VERSION ""

NS_ :

BS_:

BU_: IFV_VFP External_Tool IFV_Host MRR

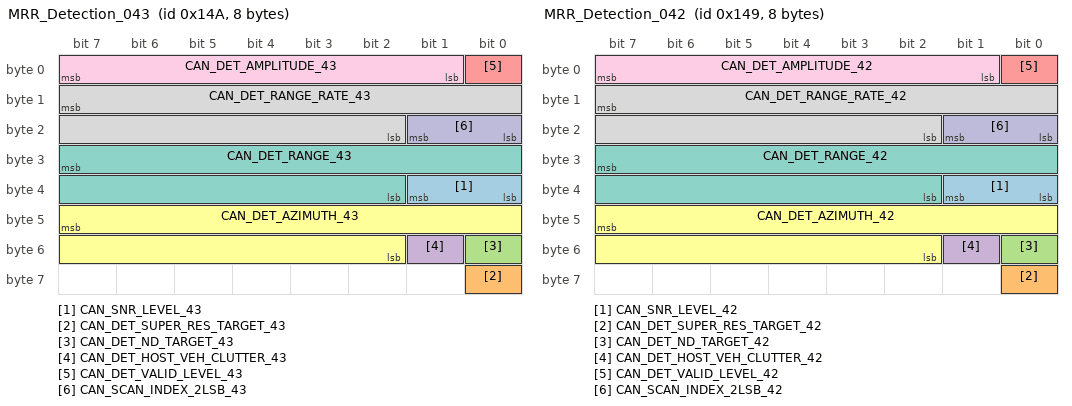
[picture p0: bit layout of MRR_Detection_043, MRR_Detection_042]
BO_ 330 MRR_Detection_043: 8 MRR
 SG_ CAN_SNR_LEVEL_43 : 33|2@0+ (1,0) [0|3] ""  IFV_VFP
 SG_ CAN_DET_SUPER_RES_TARGET_43 : 56|1@0+ (1,0) [0|1] ""  IFV_VFP
 SG_ CAN_DET_ND_TARGET_43 : 48|1@0+ (1,0) [0|1] ""  IFV_VFP
 SG_ CAN_DET_HOST_VEH_CLUTTER_43 : 49|1@0+ (1,0) [0|1] ""  IFV_VFP
 SG_ CAN_DET_VALID_LEVEL_43 : 0|1@0+ (1,0) [0|1] ""  IFV_VFP
 SG_ CAN_DET_AZIMUTH_43 : 47|14@0+ (0.0003834,-3.1416) [-3.1416|3.1396422] "rad"  IFV_VFP
 SG_ CAN_DET_RANGE_43 : 31|14@0+ (0.015625,0) [0|255.984375] "m"  IFV_VFP
 SG_ CAN_DET_RANGE_RATE_43 : 15|14@0+ (0.015625,-128) [-128|127.984375] "m/s"  IFV_VFP
 SG_ CAN_DET_AMPLITUDE_43 : 7|7@0+ (1,-64) [-64|63] "dBsm"  IFV_VFP
 SG_ CAN_SCAN_INDEX_2LSB_43 : 17|2@0+ (1,0) [0|3] ""  IFV_VFP

BO_ 329 MRR_Detection_042: 8 MRR
 SG_ CAN_SNR_LEVEL_42 : 33|2@0+ (1,0) [0|3] ""  IFV_VFP
 SG_ CAN_DET_SUPER_RES_TARGET_42 : 56|1@0+ (1,0) [0|1] ""  IFV_VFP
 SG_ CAN_DET_ND_TARGET_42 : 48|1@0+ (1,0) [0|1] ""  IFV_VFP
 SG_ CAN_DET_HOST_VEH_CLUTTER_42 : 49|1@0+ (1,0) [0|1] ""  IFV_VFP
 SG_ CAN_DET_VALID_LEVEL_42 : 0|1@0+ (1,0) [0|1] ""  IFV_VFP
 SG_ CAN_DET_AZIMUTH_42 : 47|14@0+ (0.0003834,-3.1416) [-3.1416|3.1396422] "rad"  IFV_VFP
 SG_ CAN_DET_RANGE_42 : 31|14@0+ (0.015625,0) [0|255.984375] "m"  IFV_VFP
 SG_ CAN_DET_RANGE_RATE_42 : 15|14@0+ (0.015625,-128) [-128|127.984375] "m/s"  IFV_VFP
 SG_ CAN_DET_AMPLITUDE_42 : 7|7@0+ (1,-64) [-64|63] "dBsm"  IFV_VFP
 SG_ CAN_SCAN_INDEX_2LSB_42 : 17|2@0+ (1,0) [0|3] ""  IFV_VFP

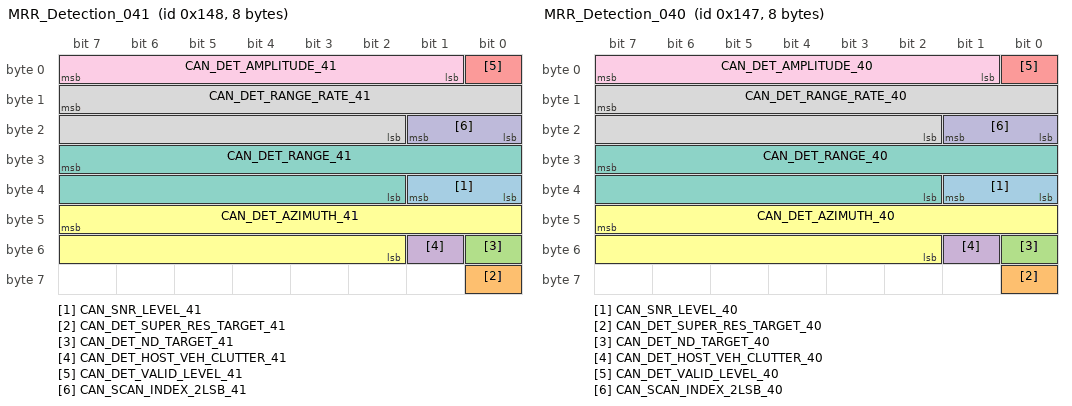
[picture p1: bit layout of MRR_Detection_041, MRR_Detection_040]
BO_ 328 MRR_Detection_041: 8 MRR
 SG_ CAN_SNR_LEVEL_41 : 33|2@0+ (1,0) [0|3] ""  IFV_VFP
 SG_ CAN_DET_SUPER_RES_TARGET_41 : 56|1@0+ (1,0) [0|1] ""  IFV_VFP
 SG_ CAN_DET_ND_TARGET_41 : 48|1@0+ (1,0) [0|1] ""  IFV_VFP
 SG_ CAN_DET_HOST_VEH_CLUTTER_41 : 49|1@0+ (1,0) [0|1] ""  IFV_VFP
 SG_ CAN_DET_VALID_LEVEL_41 : 0|1@0+ (1,0) [0|1] ""  IFV_VFP
 SG_ CAN_DET_AZIMUTH_41 : 47|14@0+ (0.0003834,-3.1416) [-3.1416|3.1396422] "rad"  IFV_VFP
 SG_ CAN_DET_RANGE_41 : 31|14@0+ (0.015625,0) [0|255.984375] "m"  IFV_VFP
 SG_ CAN_DET_RANGE_RATE_41 : 15|14@0+ (0.015625,-128) [-128|127.984375] "m/s"  IFV_VFP
 SG_ CAN_DET_AMPLITUDE_41 : 7|7@0+ (1,-64) [-64|63] "dBsm"  IFV_VFP
 SG_ CAN_SCAN_INDEX_2LSB_41 : 17|2@0+ (1,0) [0|3] ""  IFV_VFP

BO_ 327 MRR_Detection_040: 8 MRR
 SG_ CAN_SNR_LEVEL_40 : 33|2@0+ (1,0) [0|3] ""  IFV_VFP
 SG_ CAN_DET_SUPER_RES_TARGET_40 : 56|1@0+ (1,0) [0|1] ""  IFV_VFP
 SG_ CAN_DET_ND_TARGET_40 : 48|1@0+ (1,0) [0|1] ""  IFV_VFP
 SG_ CAN_DET_HOST_VEH_CLUTTER_40 : 49|1@0+ (1,0) [0|1] ""  IFV_VFP
 SG_ CAN_DET_VALID_LEVEL_40 : 0|1@0+ (1,0) [0|1] ""  IFV_VFP
 SG_ CAN_DET_AZIMUTH_40 : 47|14@0+ (0.0003834,-3.1416) [-3.1416|3.1396422] "rad"  IFV_VFP
 SG_ CAN_DET_RANGE_40 : 31|14@0+ (0.015625,0) [0|255.984375] "m"  IFV_VFP
 SG_ CAN_DET_RANGE_RATE_40 : 15|14@0+ (0.015625,-128) [-128|127.984375] "m/s"  IFV_VFP
 SG_ CAN_DET_AMPLITUDE_40 : 7|7@0+ (1,-64) [-64|63] "dBsm"  IFV_VFP
 SG_ CAN_SCAN_INDEX_2LSB_40 : 17|2@0+ (1,0) [0|3] ""  IFV_VFP

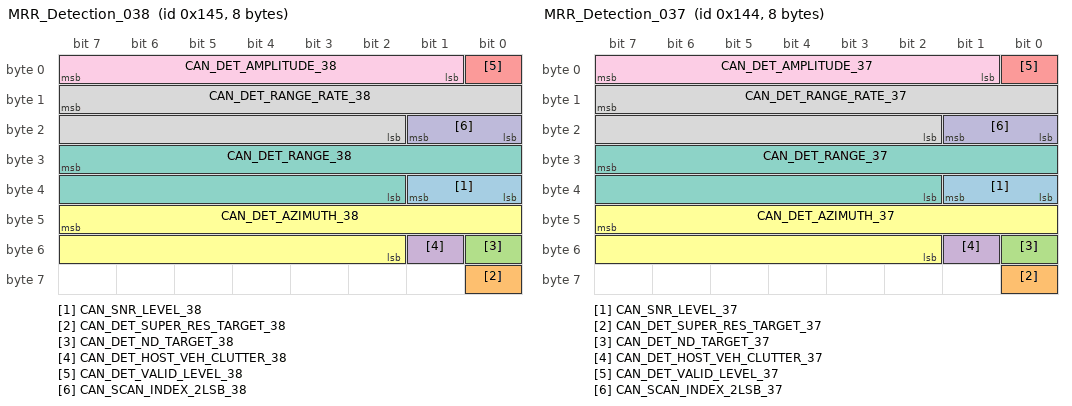
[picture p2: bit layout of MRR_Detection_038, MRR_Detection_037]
BO_ 325 MRR_Detection_038: 8 MRR
 SG_ CAN_SNR_LEVEL_38 : 33|2@0+ (1,0) [0|3] ""  IFV_VFP
 SG_ CAN_DET_SUPER_RES_TARGET_38 : 56|1@0+ (1,0) [0|1] ""  IFV_VFP
 SG_ CAN_DET_ND_TARGET_38 : 48|1@0+ (1,0) [0|1] ""  IFV_VFP
 SG_ CAN_DET_HOST_VEH_CLUTTER_38 : 49|1@0+ (1,0) [0|1] ""  IFV_VFP
 SG_ CAN_DET_VALID_LEVEL_38 : 0|1@0+ (1,0) [0|1] ""  IFV_VFP
 SG_ CAN_DET_AZIMUTH_38 : 47|14@0+ (0.0003834,-3.1416) [-3.1416|3.1396422] "rad"  IFV_VFP
 SG_ CAN_DET_RANGE_38 : 31|14@0+ (0.015625,0) [0|255.984375] "m"  IFV_VFP
 SG_ CAN_DET_RANGE_RATE_38 : 15|14@0+ (0.015625,-128) [-128|127.984375] "m/s"  IFV_VFP
 SG_ CAN_DET_AMPLITUDE_38 : 7|7@0+ (1,-64) [-64|63] "dBsm"  IFV_VFP
 SG_ CAN_SCAN_INDEX_2LSB_38 : 17|2@0+ (1,0) [0|3] ""  IFV_VFP

BO_ 324 MRR_Detection_037: 8 MRR
 SG_ CAN_SNR_LEVEL_37 : 33|2@0+ (1,0) [0|3] ""  IFV_VFP
 SG_ CAN_DET_SUPER_RES_TARGET_37 : 56|1@0+ (1,0) [0|1] ""  IFV_VFP
 SG_ CAN_DET_ND_TARGET_37 : 48|1@0+ (1,0) [0|1] ""  IFV_VFP
 SG_ CAN_DET_HOST_VEH_CLUTTER_37 : 49|1@0+ (1,0) [0|1] ""  IFV_VFP
 SG_ CAN_DET_VALID_LEVEL_37 : 0|1@0+ (1,0) [0|1] ""  IFV_VFP
 SG_ CAN_DET_AZIMUTH_37 : 47|14@0+ (0.0003834,-3.1416) [-3.1416|3.1396422] "rad"  IFV_VFP
 SG_ CAN_DET_RANGE_37 : 31|14@0+ (0.015625,0) [0|255.984375] "m"  IFV_VFP
 SG_ CAN_DET_RANGE_RATE_37 : 15|14@0+ (0.015625,-128) [-128|127.984375] "m/s"  IFV_VFP
 SG_ CAN_DET_AMPLITUDE_37 : 7|7@0+ (1,-64) [-64|63] "dBsm"  IFV_VFP
 SG_ CAN_SCAN_INDEX_2LSB_37 : 17|2@0+ (1,0) [0|3] ""  IFV_VFP

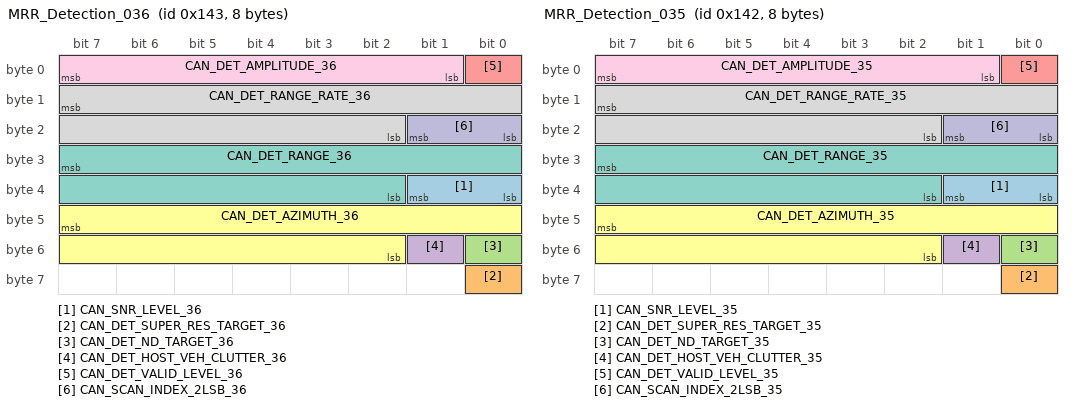
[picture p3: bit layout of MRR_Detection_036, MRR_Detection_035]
BO_ 323 MRR_Detection_036: 8 MRR
 SG_ CAN_SNR_LEVEL_36 : 33|2@0+ (1,0) [0|3] ""  IFV_VFP
 SG_ CAN_DET_SUPER_RES_TARGET_36 : 56|1@0+ (1,0) [0|1] ""  IFV_VFP
 SG_ CAN_DET_ND_TARGET_36 : 48|1@0+ (1,0) [0|1] ""  IFV_VFP
 SG_ CAN_DET_HOST_VEH_CLUTTER_36 : 49|1@0+ (1,0) [0|1] ""  IFV_VFP
 SG_ CAN_DET_VALID_LEVEL_36 : 0|1@0+ (1,0) [0|1] ""  IFV_VFP
 SG_ CAN_DET_AZIMUTH_36 : 47|14@0+ (0.0003834,-3.1416) [-3.1416|3.1396422] "rad"  IFV_VFP
 SG_ CAN_DET_RANGE_36 : 31|14@0+ (0.015625,0) [0|255.984375] "m"  IFV_VFP
 SG_ CAN_DET_RANGE_RATE_36 : 15|14@0+ (0.015625,-128) [-128|127.984375] "m/s"  IFV_VFP
 SG_ CAN_DET_AMPLITUDE_36 : 7|7@0+ (1,-64) [-64|63] "dBsm"  IFV_VFP
 SG_ CAN_SCAN_INDEX_2LSB_36 : 17|2@0+ (1,0) [0|3] ""  IFV_VFP

BO_ 322 MRR_Detection_035: 8 MRR
 SG_ CAN_SNR_LEVEL_35 : 33|2@0+ (1,0) [0|3] ""  IFV_VFP
 SG_ CAN_DET_SUPER_RES_TARGET_35 : 56|1@0+ (1,0) [0|1] ""  IFV_VFP
 SG_ CAN_DET_ND_TARGET_35 : 48|1@0+ (1,0) [0|1] ""  IFV_VFP
 SG_ CAN_DET_HOST_VEH_CLUTTER_35 : 49|1@0+ (1,0) [0|1] ""  IFV_VFP
 SG_ CAN_DET_VALID_LEVEL_35 : 0|1@0+ (1,0) [0|1] ""  IFV_VFP
 SG_ CAN_DET_AZIMUTH_35 : 47|14@0+ (0.0003834,-3.1416) [-3.1416|3.1396422] "rad"  IFV_VFP
 SG_ CAN_DET_RANGE_35 : 31|14@0+ (0.015625,0) [0|255.984375] "m"  IFV_VFP
 SG_ CAN_DET_RANGE_RATE_35 : 15|14@0+ (0.015625,-128) [-128|127.984375] "m/s"  IFV_VFP
 SG_ CAN_DET_AMPLITUDE_35 : 7|7@0+ (1,-64) [-64|63] "dBsm"  IFV_VFP
 SG_ CAN_SCAN_INDEX_2LSB_35 : 17|2@0+ (1,0) [0|3] ""  IFV_VFP

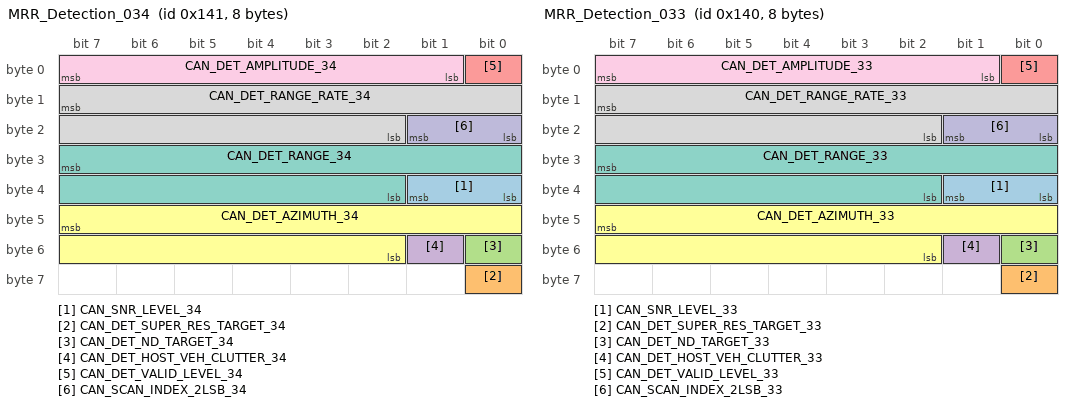
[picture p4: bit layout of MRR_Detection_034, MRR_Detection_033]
BO_ 321 MRR_Detection_034: 8 MRR
 SG_ CAN_SNR_LEVEL_34 : 33|2@0+ (1,0) [0|3] ""  IFV_VFP
 SG_ CAN_DET_SUPER_RES_TARGET_34 : 56|1@0+ (1,0) [0|1] ""  IFV_VFP
 SG_ CAN_DET_ND_TARGET_34 : 48|1@0+ (1,0) [0|1] ""  IFV_VFP
 SG_ CAN_DET_HOST_VEH_CLUTTER_34 : 49|1@0+ (1,0) [0|1] ""  IFV_VFP
 SG_ CAN_DET_VALID_LEVEL_34 : 0|1@0+ (1,0) [0|1] ""  IFV_VFP
 SG_ CAN_DET_AZIMUTH_34 : 47|14@0+ (0.0003834,-3.1416) [-3.1416|3.1396422] "rad"  IFV_VFP
 SG_ CAN_DET_RANGE_34 : 31|14@0+ (0.015625,0) [0|255.984375] "m"  IFV_VFP
 SG_ CAN_DET_RANGE_RATE_34 : 15|14@0+ (0.015625,-128) [-128|127.984375] "m/s"  IFV_VFP
 SG_ CAN_DET_AMPLITUDE_34 : 7|7@0+ (1,-64) [-64|63] "dBsm"  IFV_VFP
 SG_ CAN_SCAN_INDEX_2LSB_34 : 17|2@0+ (1,0) [0|3] ""  IFV_VFP

BO_ 320 MRR_Detection_033: 8 MRR
 SG_ CAN_SNR_LEVEL_33 : 33|2@0+ (1,0) [0|3] ""  IFV_VFP
 SG_ CAN_DET_SUPER_RES_TARGET_33 : 56|1@0+ (1,0) [0|1] ""  IFV_VFP
 SG_ CAN_DET_ND_TARGET_33 : 48|1@0+ (1,0) [0|1] ""  IFV_VFP
 SG_ CAN_DET_HOST_VEH_CLUTTER_33 : 49|1@0+ (1,0) [0|1] ""  IFV_VFP
 SG_ CAN_DET_VALID_LEVEL_33 : 0|1@0+ (1,0) [0|1] ""  IFV_VFP
 SG_ CAN_DET_AZIMUTH_33 : 47|14@0+ (0.0003834,-3.1416) [-3.1416|3.1396422] "rad"  IFV_VFP
 SG_ CAN_DET_RANGE_33 : 31|14@0+ (0.015625,0) [0|255.984375] "m"  IFV_VFP
 SG_ CAN_DET_RANGE_RATE_33 : 15|14@0+ (0.015625,-128) [-128|127.984375] "m/s"  IFV_VFP
 SG_ CAN_DET_AMPLITUDE_33 : 7|7@0+ (1,-64) [-64|63] "dBsm"  IFV_VFP
 SG_ CAN_SCAN_INDEX_2LSB_33 : 17|2@0+ (1,0) [0|3] ""  IFV_VFP

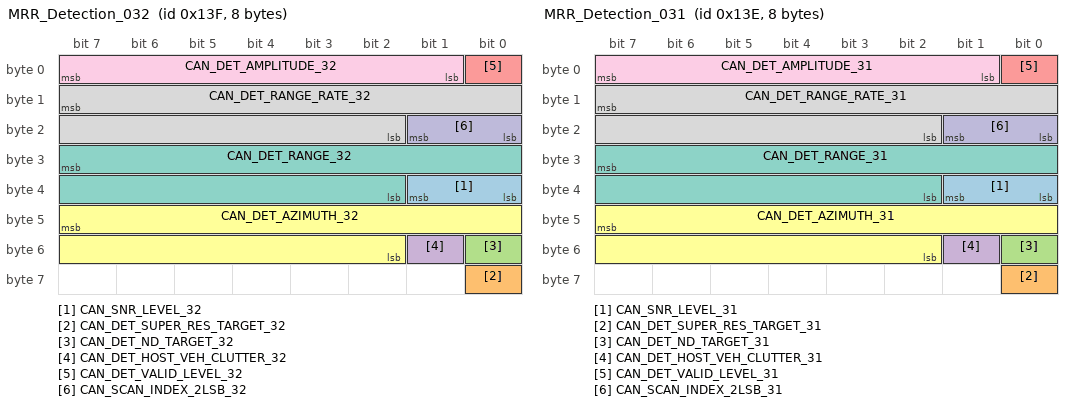
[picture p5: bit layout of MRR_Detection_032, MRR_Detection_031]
BO_ 319 MRR_Detection_032: 8 MRR
 SG_ CAN_SNR_LEVEL_32 : 33|2@0+ (1,0) [0|3] ""  IFV_VFP
 SG_ CAN_DET_SUPER_RES_TARGET_32 : 56|1@0+ (1,0) [0|1] ""  IFV_VFP
 SG_ CAN_DET_ND_TARGET_32 : 48|1@0+ (1,0) [0|1] ""  IFV_VFP
 SG_ CAN_DET_HOST_VEH_CLUTTER_32 : 49|1@0+ (1,0) [0|1] ""  IFV_VFP
 SG_ CAN_DET_VALID_LEVEL_32 : 0|1@0+ (1,0) [0|1] ""  IFV_VFP
 SG_ CAN_DET_AZIMUTH_32 : 47|14@0+ (0.0003834,-3.1416) [-3.1416|3.1396422] "rad"  IFV_VFP
 SG_ CAN_DET_RANGE_32 : 31|14@0+ (0.015625,0) [0|255.984375] "m"  IFV_VFP
 SG_ CAN_DET_RANGE_RATE_32 : 15|14@0+ (0.015625,-128) [-128|127.984375] "m/s"  IFV_VFP
 SG_ CAN_DET_AMPLITUDE_32 : 7|7@0+ (1,-64) [-64|63] "dBsm"  IFV_VFP
 SG_ CAN_SCAN_INDEX_2LSB_32 : 17|2@0+ (1,0) [0|3] ""  IFV_VFP

BO_ 318 MRR_Detection_031: 8 MRR
 SG_ CAN_SNR_LEVEL_31 : 33|2@0+ (1,0) [0|3] ""  IFV_VFP
 SG_ CAN_DET_SUPER_RES_TARGET_31 : 56|1@0+ (1,0) [0|1] ""  IFV_VFP
 SG_ CAN_DET_ND_TARGET_31 : 48|1@0+ (1,0) [0|1] ""  IFV_VFP
 SG_ CAN_DET_HOST_VEH_CLUTTER_31 : 49|1@0+ (1,0) [0|1] ""  IFV_VFP
 SG_ CAN_DET_VALID_LEVEL_31 : 0|1@0+ (1,0) [0|1] ""  IFV_VFP
 SG_ CAN_DET_AZIMUTH_31 : 47|14@0+ (0.0003834,-3.1416) [-3.1416|3.1396422] "rad"  IFV_VFP
 SG_ CAN_DET_RANGE_31 : 31|14@0+ (0.015625,0) [0|255.984375] "m"  IFV_VFP
 SG_ CAN_DET_RANGE_RATE_31 : 15|14@0+ (0.015625,-128) [-128|127.984375] "m/s"  IFV_VFP
 SG_ CAN_DET_AMPLITUDE_31 : 7|7@0+ (1,-64) [-64|63] "dBsm"  IFV_VFP
 SG_ CAN_SCAN_INDEX_2LSB_31 : 17|2@0+ (1,0) [0|3] ""  IFV_VFP

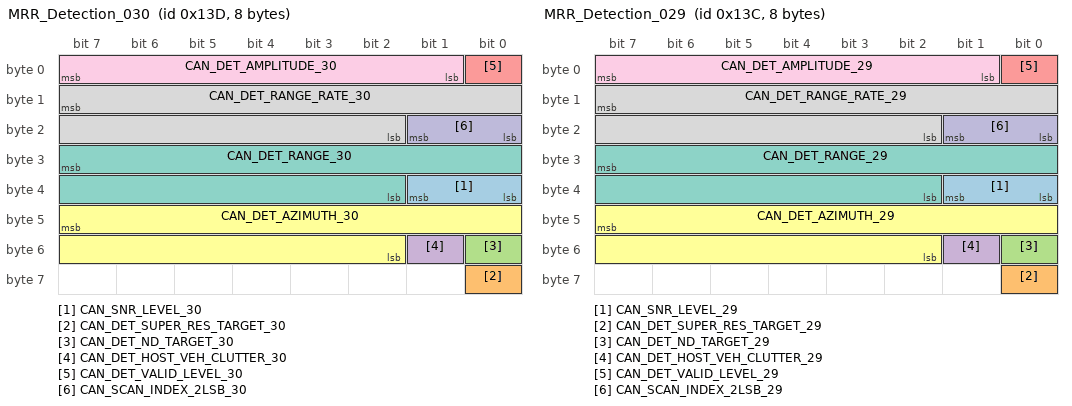
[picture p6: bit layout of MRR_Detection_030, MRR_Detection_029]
BO_ 317 MRR_Detection_030: 8 MRR
 SG_ CAN_SNR_LEVEL_30 : 33|2@0+ (1,0) [0|3] ""  IFV_VFP
 SG_ CAN_DET_SUPER_RES_TARGET_30 : 56|1@0+ (1,0) [0|1] ""  IFV_VFP
 SG_ CAN_DET_ND_TARGET_30 : 48|1@0+ (1,0) [0|1] ""  IFV_VFP
 SG_ CAN_DET_HOST_VEH_CLUTTER_30 : 49|1@0+ (1,0) [0|1] ""  IFV_VFP
 SG_ CAN_DET_VALID_LEVEL_30 : 0|1@0+ (1,0) [0|1] ""  IFV_VFP
 SG_ CAN_DET_AZIMUTH_30 : 47|14@0+ (0.0003834,-3.1416) [-3.1416|3.1396422] "rad"  IFV_VFP
 SG_ CAN_DET_RANGE_30 : 31|14@0+ (0.015625,0) [0|255.984375] "m"  IFV_VFP
 SG_ CAN_DET_RANGE_RATE_30 : 15|14@0+ (0.015625,-128) [-128|127.984375] "m/s"  IFV_VFP
 SG_ CAN_DET_AMPLITUDE_30 : 7|7@0+ (1,-64) [-64|63] "dBsm"  IFV_VFP
 SG_ CAN_SCAN_INDEX_2LSB_30 : 17|2@0+ (1,0) [0|3] ""  IFV_VFP

BO_ 316 MRR_Detection_029: 8 MRR
 SG_ CAN_SNR_LEVEL_29 : 33|2@0+ (1,0) [0|3] ""  IFV_VFP
 SG_ CAN_DET_SUPER_RES_TARGET_29 : 56|1@0+ (1,0) [0|1] ""  IFV_VFP
 SG_ CAN_DET_ND_TARGET_29 : 48|1@0+ (1,0) [0|1] ""  IFV_VFP
 SG_ CAN_DET_HOST_VEH_CLUTTER_29 : 49|1@0+ (1,0) [0|1] ""  IFV_VFP
 SG_ CAN_DET_VALID_LEVEL_29 : 0|1@0+ (1,0) [0|1] ""  IFV_VFP
 SG_ CAN_DET_AZIMUTH_29 : 47|14@0+ (0.0003834,-3.1416) [-3.1416|3.1396422] "rad"  IFV_VFP
 SG_ CAN_DET_RANGE_29 : 31|14@0+ (0.015625,0) [0|255.984375] "m"  IFV_VFP
 SG_ CAN_DET_RANGE_RATE_29 : 15|14@0+ (0.015625,-128) [-128|127.984375] "m/s"  IFV_VFP
 SG_ CAN_DET_AMPLITUDE_29 : 7|7@0+ (1,-64) [-64|63] "dBsm"  IFV_VFP
 SG_ CAN_SCAN_INDEX_2LSB_29 : 17|2@0+ (1,0) [0|3] ""  IFV_VFP

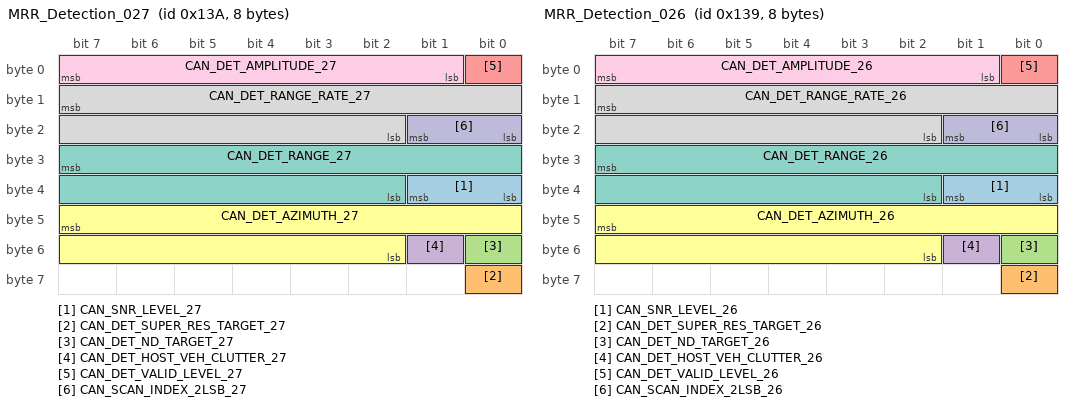
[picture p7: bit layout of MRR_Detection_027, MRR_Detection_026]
BO_ 314 MRR_Detection_027: 8 MRR
 SG_ CAN_SNR_LEVEL_27 : 33|2@0+ (1,0) [0|3] ""  IFV_VFP
 SG_ CAN_DET_SUPER_RES_TARGET_27 : 56|1@0+ (1,0) [0|1] ""  IFV_VFP
 SG_ CAN_DET_ND_TARGET_27 : 48|1@0+ (1,0) [0|1] ""  IFV_VFP
 SG_ CAN_DET_HOST_VEH_CLUTTER_27 : 49|1@0+ (1,0) [0|1] ""  IFV_VFP
 SG_ CAN_DET_VALID_LEVEL_27 : 0|1@0+ (1,0) [0|1] ""  IFV_VFP
 SG_ CAN_DET_AZIMUTH_27 : 47|14@0+ (0.0003834,-3.1416) [-3.1416|3.1396422] "rad"  IFV_VFP
 SG_ CAN_DET_RANGE_27 : 31|14@0+ (0.015625,0) [0|255.984375] "m"  IFV_VFP
 SG_ CAN_DET_RANGE_RATE_27 : 15|14@0+ (0.015625,-128) [-128|127.984375] "m/s"  IFV_VFP
 SG_ CAN_DET_AMPLITUDE_27 : 7|7@0+ (1,-64) [-64|63] "dBsm"  IFV_VFP
 SG_ CAN_SCAN_INDEX_2LSB_27 : 17|2@0+ (1,0) [0|3] ""  IFV_VFP

BO_ 313 MRR_Detection_026: 8 MRR
 SG_ CAN_SNR_LEVEL_26 : 33|2@0+ (1,0) [0|3] ""  IFV_VFP
 SG_ CAN_DET_SUPER_RES_TARGET_26 : 56|1@0+ (1,0) [0|1] ""  IFV_VFP
 SG_ CAN_DET_ND_TARGET_26 : 48|1@0+ (1,0) [0|1] ""  IFV_VFP
 SG_ CAN_DET_HOST_VEH_CLUTTER_26 : 49|1@0+ (1,0) [0|1] ""  IFV_VFP
 SG_ CAN_DET_VALID_LEVEL_26 : 0|1@0+ (1,0) [0|1] ""  IFV_VFP
 SG_ CAN_DET_AZIMUTH_26 : 47|14@0+ (0.0003834,-3.1416) [-3.1416|3.1396422] "rad"  IFV_VFP
 SG_ CAN_DET_RANGE_26 : 31|14@0+ (0.015625,0) [0|255.984375] "m"  IFV_VFP
 SG_ CAN_DET_RANGE_RATE_26 : 15|14@0+ (0.015625,-128) [-128|127.984375] "m/s"  IFV_VFP
 SG_ CAN_DET_AMPLITUDE_26 : 7|7@0+ (1,-64) [-64|63] "dBsm"  IFV_VFP
 SG_ CAN_SCAN_INDEX_2LSB_26 : 17|2@0+ (1,0) [0|3] ""  IFV_VFP

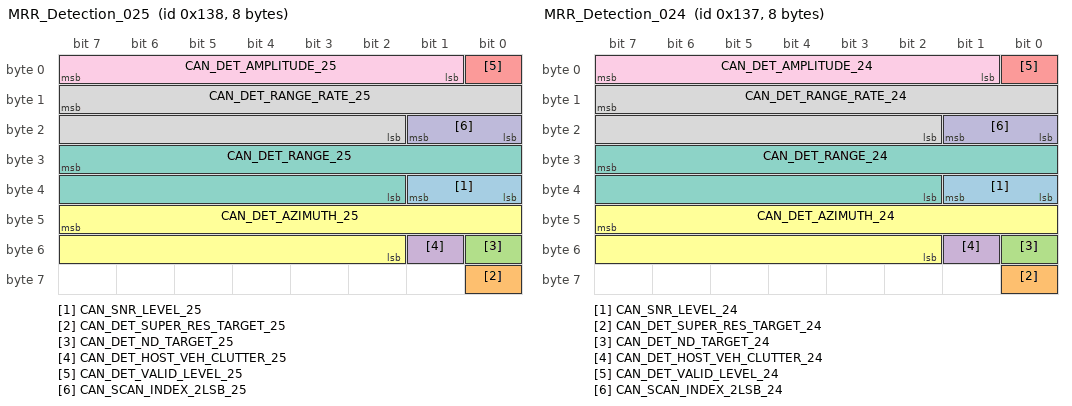
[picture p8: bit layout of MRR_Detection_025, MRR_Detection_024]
BO_ 312 MRR_Detection_025: 8 MRR
 SG_ CAN_SNR_LEVEL_25 : 33|2@0+ (1,0) [0|3] ""  IFV_VFP
 SG_ CAN_DET_SUPER_RES_TARGET_25 : 56|1@0+ (1,0) [0|1] ""  IFV_VFP
 SG_ CAN_DET_ND_TARGET_25 : 48|1@0+ (1,0) [0|1] ""  IFV_VFP
 SG_ CAN_DET_HOST_VEH_CLUTTER_25 : 49|1@0+ (1,0) [0|1] ""  IFV_VFP
 SG_ CAN_DET_VALID_LEVEL_25 : 0|1@0+ (1,0) [0|1] ""  IFV_VFP
 SG_ CAN_DET_AZIMUTH_25 : 47|14@0+ (0.0003834,-3.1416) [-3.1416|3.1396422] "rad"  IFV_VFP
 SG_ CAN_DET_RANGE_25 : 31|14@0+ (0.015625,0) [0|255.984375] "m"  IFV_VFP
 SG_ CAN_DET_RANGE_RATE_25 : 15|14@0+ (0.015625,-128) [-128|127.984375] "m/s"  IFV_VFP
 SG_ CAN_DET_AMPLITUDE_25 : 7|7@0+ (1,-64) [-64|63] "dBsm"  IFV_VFP
 SG_ CAN_SCAN_INDEX_2LSB_25 : 17|2@0+ (1,0) [0|3] ""  IFV_VFP

BO_ 311 MRR_Detection_024: 8 MRR
 SG_ CAN_SNR_LEVEL_24 : 33|2@0+ (1,0) [0|3] ""  IFV_VFP
 SG_ CAN_DET_SUPER_RES_TARGET_24 : 56|1@0+ (1,0) [0|1] ""  IFV_VFP
 SG_ CAN_DET_ND_TARGET_24 : 48|1@0+ (1,0) [0|1] ""  IFV_VFP
 SG_ CAN_DET_HOST_VEH_CLUTTER_24 : 49|1@0+ (1,0) [0|1] ""  IFV_VFP
 SG_ CAN_DET_VALID_LEVEL_24 : 0|1@0+ (1,0) [0|1] ""  IFV_VFP
 SG_ CAN_DET_AZIMUTH_24 : 47|14@0+ (0.0003834,-3.1416) [-3.1416|3.1396422] "rad"  IFV_VFP
 SG_ CAN_DET_RANGE_24 : 31|14@0+ (0.015625,0) [0|255.984375] "m"  IFV_VFP
 SG_ CAN_DET_RANGE_RATE_24 : 15|14@0+ (0.015625,-128) [-128|127.984375] "m/s"  IFV_VFP
 SG_ CAN_DET_AMPLITUDE_24 : 7|7@0+ (1,-64) [-64|63] "dBsm"  IFV_VFP
 SG_ CAN_SCAN_INDEX_2LSB_24 : 17|2@0+ (1,0) [0|3] ""  IFV_VFP

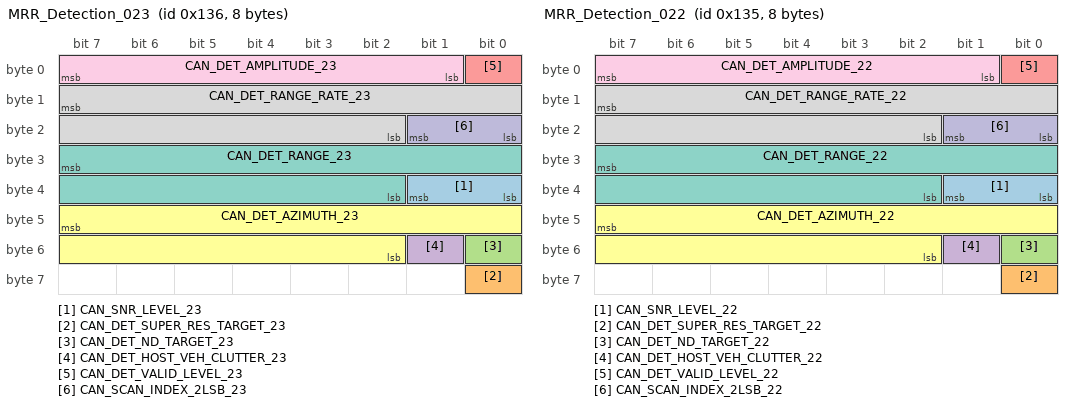
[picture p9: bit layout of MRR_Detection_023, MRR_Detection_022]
BO_ 310 MRR_Detection_023: 8 MRR
 SG_ CAN_SNR_LEVEL_23 : 33|2@0+ (1,0) [0|3] ""  IFV_VFP
 SG_ CAN_DET_SUPER_RES_TARGET_23 : 56|1@0+ (1,0) [0|1] ""  IFV_VFP
 SG_ CAN_DET_ND_TARGET_23 : 48|1@0+ (1,0) [0|1] ""  IFV_VFP
 SG_ CAN_DET_HOST_VEH_CLUTTER_23 : 49|1@0+ (1,0) [0|1] ""  IFV_VFP
 SG_ CAN_DET_VALID_LEVEL_23 : 0|1@0+ (1,0) [0|1] ""  IFV_VFP
 SG_ CAN_DET_AZIMUTH_23 : 47|14@0+ (0.0003834,-3.1416) [-3.1416|3.1396422] "rad"  IFV_VFP
 SG_ CAN_DET_RANGE_23 : 31|14@0+ (0.015625,0) [0|255.984375] "m"  IFV_VFP
 SG_ CAN_DET_RANGE_RATE_23 : 15|14@0+ (0.015625,-128) [-128|127.984375] "m/s"  IFV_VFP
 SG_ CAN_DET_AMPLITUDE_23 : 7|7@0+ (1,-64) [-64|63] "dBsm"  IFV_VFP
 SG_ CAN_SCAN_INDEX_2LSB_23 : 17|2@0+ (1,0) [0|3] ""  IFV_VFP

BO_ 309 MRR_Detection_022: 8 MRR
 SG_ CAN_SNR_LEVEL_22 : 33|2@0+ (1,0) [0|3] ""  IFV_VFP
 SG_ CAN_DET_SUPER_RES_TARGET_22 : 56|1@0+ (1,0) [0|1] ""  IFV_VFP
 SG_ CAN_DET_ND_TARGET_22 : 48|1@0+ (1,0) [0|1] ""  IFV_VFP
 SG_ CAN_DET_HOST_VEH_CLUTTER_22 : 49|1@0+ (1,0) [0|1] ""  IFV_VFP
 SG_ CAN_DET_VALID_LEVEL_22 : 0|1@0+ (1,0) [0|1] ""  IFV_VFP
 SG_ CAN_DET_AZIMUTH_22 : 47|14@0+ (0.0003834,-3.1416) [-3.1416|3.1396422] "rad"  IFV_VFP
 SG_ CAN_DET_RANGE_22 : 31|14@0+ (0.015625,0) [0|255.984375] "m"  IFV_VFP
 SG_ CAN_DET_RANGE_RATE_22 : 15|14@0+ (0.015625,-128) [-128|127.984375] "m/s"  IFV_VFP
 SG_ CAN_DET_AMPLITUDE_22 : 7|7@0+ (1,-64) [-64|63] "dBsm"  IFV_VFP
 SG_ CAN_SCAN_INDEX_2LSB_22 : 17|2@0+ (1,0) [0|3] ""  IFV_VFP

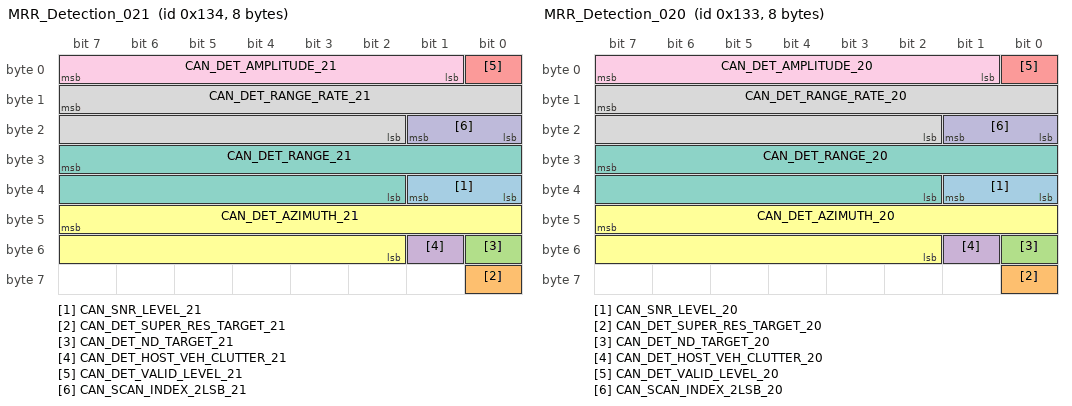
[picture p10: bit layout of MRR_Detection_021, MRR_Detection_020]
BO_ 308 MRR_Detection_021: 8 MRR
 SG_ CAN_SNR_LEVEL_21 : 33|2@0+ (1,0) [0|3] ""  IFV_VFP
 SG_ CAN_DET_SUPER_RES_TARGET_21 : 56|1@0+ (1,0) [0|1] ""  IFV_VFP
 SG_ CAN_DET_ND_TARGET_21 : 48|1@0+ (1,0) [0|1] ""  IFV_VFP
 SG_ CAN_DET_HOST_VEH_CLUTTER_21 : 49|1@0+ (1,0) [0|1] ""  IFV_VFP
 SG_ CAN_DET_VALID_LEVEL_21 : 0|1@0+ (1,0) [0|1] ""  IFV_VFP
 SG_ CAN_DET_AZIMUTH_21 : 47|14@0+ (0.0003834,-3.1416) [-3.1416|3.1396422] "rad"  IFV_VFP
 SG_ CAN_DET_RANGE_21 : 31|14@0+ (0.015625,0) [0|255.984375] "m"  IFV_VFP
 SG_ CAN_DET_RANGE_RATE_21 : 15|14@0+ (0.015625,-128) [-128|127.984375] "m/s"  IFV_VFP
 SG_ CAN_DET_AMPLITUDE_21 : 7|7@0+ (1,-64) [-64|63] "dBsm"  IFV_VFP
 SG_ CAN_SCAN_INDEX_2LSB_21 : 17|2@0+ (1,0) [0|3] ""  IFV_VFP

BO_ 307 MRR_Detection_020: 8 MRR
 SG_ CAN_SNR_LEVEL_20 : 33|2@0+ (1,0) [0|3] ""  IFV_VFP
 SG_ CAN_DET_SUPER_RES_TARGET_20 : 56|1@0+ (1,0) [0|1] ""  IFV_VFP
 SG_ CAN_DET_ND_TARGET_20 : 48|1@0+ (1,0) [0|1] ""  IFV_VFP
 SG_ CAN_DET_HOST_VEH_CLUTTER_20 : 49|1@0+ (1,0) [0|1] ""  IFV_VFP
 SG_ CAN_DET_VALID_LEVEL_20 : 0|1@0+ (1,0) [0|1] ""  IFV_VFP
 SG_ CAN_DET_AZIMUTH_20 : 47|14@0+ (0.0003834,-3.1416) [-3.1416|3.1396422] "rad"  IFV_VFP
 SG_ CAN_DET_RANGE_20 : 31|14@0+ (0.015625,0) [0|255.984375] "m"  IFV_VFP
 SG_ CAN_DET_RANGE_RATE_20 : 15|14@0+ (0.015625,-128) [-128|127.984375] "m/s"  IFV_VFP
 SG_ CAN_DET_AMPLITUDE_20 : 7|7@0+ (1,-64) [-64|63] "dBsm"  IFV_VFP
 SG_ CAN_SCAN_INDEX_2LSB_20 : 17|2@0+ (1,0) [0|3] ""  IFV_VFP

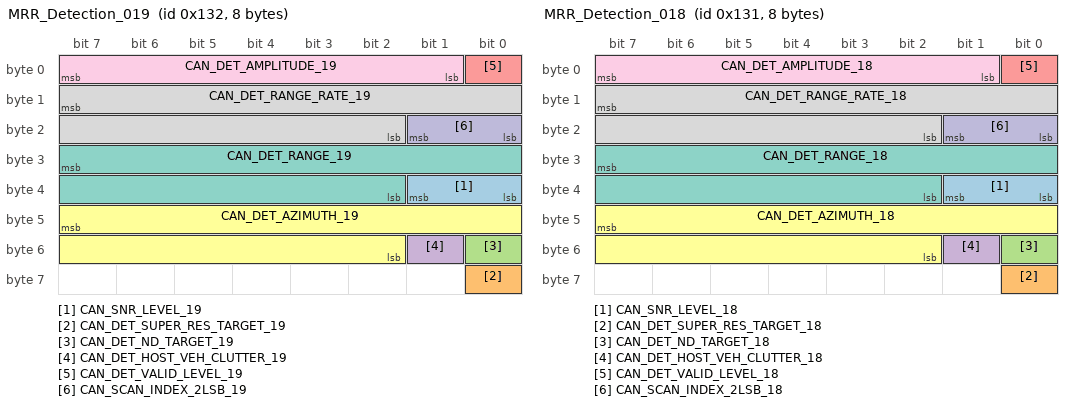
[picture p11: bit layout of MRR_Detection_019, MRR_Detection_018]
BO_ 306 MRR_Detection_019: 8 MRR
 SG_ CAN_SNR_LEVEL_19 : 33|2@0+ (1,0) [0|3] ""  IFV_VFP
 SG_ CAN_DET_SUPER_RES_TARGET_19 : 56|1@0+ (1,0) [0|1] ""  IFV_VFP
 SG_ CAN_DET_ND_TARGET_19 : 48|1@0+ (1,0) [0|1] ""  IFV_VFP
 SG_ CAN_DET_HOST_VEH_CLUTTER_19 : 49|1@0+ (1,0) [0|1] ""  IFV_VFP
 SG_ CAN_DET_VALID_LEVEL_19 : 0|1@0+ (1,0) [0|1] ""  IFV_VFP
 SG_ CAN_DET_AZIMUTH_19 : 47|14@0+ (0.0003834,-3.1416) [-3.1416|3.1396422] "rad"  IFV_VFP
 SG_ CAN_DET_RANGE_19 : 31|14@0+ (0.015625,0) [0|255.984375] "m"  IFV_VFP
 SG_ CAN_DET_RANGE_RATE_19 : 15|14@0+ (0.015625,-128) [-128|127.984375] "m/s"  IFV_VFP
 SG_ CAN_DET_AMPLITUDE_19 : 7|7@0+ (1,-64) [-64|63] "dBsm"  IFV_VFP
 SG_ CAN_SCAN_INDEX_2LSB_19 : 17|2@0+ (1,0) [0|3] ""  IFV_VFP

BO_ 305 MRR_Detection_018: 8 MRR
 SG_ CAN_SNR_LEVEL_18 : 33|2@0+ (1,0) [0|3] ""  IFV_VFP
 SG_ CAN_DET_SUPER_RES_TARGET_18 : 56|1@0+ (1,0) [0|1] ""  IFV_VFP
 SG_ CAN_DET_ND_TARGET_18 : 48|1@0+ (1,0) [0|1] ""  IFV_VFP
 SG_ CAN_DET_HOST_VEH_CLUTTER_18 : 49|1@0+ (1,0) [0|1] ""  IFV_VFP
 SG_ CAN_DET_VALID_LEVEL_18 : 0|1@0+ (1,0) [0|1] ""  IFV_VFP
 SG_ CAN_DET_AZIMUTH_18 : 47|14@0+ (0.0003834,-3.1416) [-3.1416|3.1396422] "rad"  IFV_VFP
 SG_ CAN_DET_RANGE_18 : 31|14@0+ (0.015625,0) [0|255.984375] "m"  IFV_VFP
 SG_ CAN_DET_RANGE_RATE_18 : 15|14@0+ (0.015625,-128) [-128|127.984375] "m/s"  IFV_VFP
 SG_ CAN_DET_AMPLITUDE_18 : 7|7@0+ (1,-64) [-64|63] "dBsm"  IFV_VFP
 SG_ CAN_SCAN_INDEX_2LSB_18 : 17|2@0+ (1,0) [0|3] ""  IFV_VFP

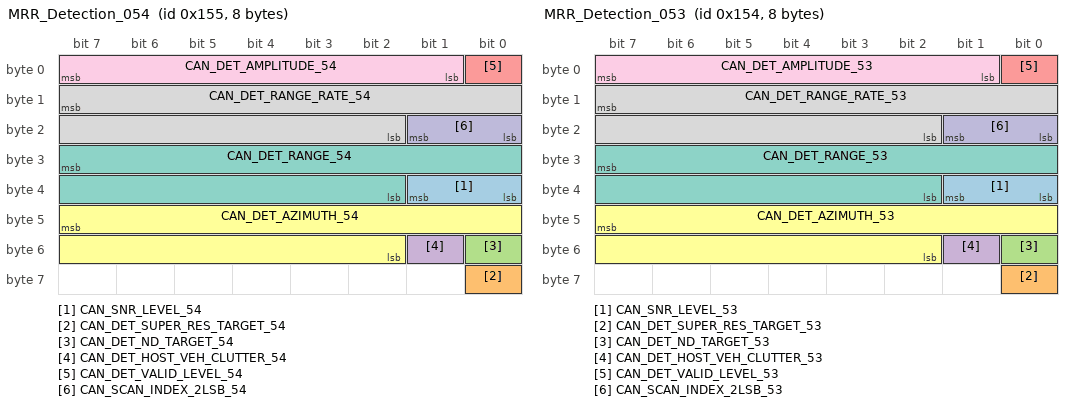
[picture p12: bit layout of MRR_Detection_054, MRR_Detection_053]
BO_ 341 MRR_Detection_054: 8 MRR
 SG_ CAN_SNR_LEVEL_54 : 33|2@0+ (1,0) [0|3] ""  IFV_VFP
 SG_ CAN_DET_SUPER_RES_TARGET_54 : 56|1@0+ (1,0) [0|1] ""  IFV_VFP
 SG_ CAN_DET_ND_TARGET_54 : 48|1@0+ (1,0) [0|1] ""  IFV_VFP
 SG_ CAN_DET_HOST_VEH_CLUTTER_54 : 49|1@0+ (1,0) [0|1] ""  IFV_VFP
 SG_ CAN_DET_VALID_LEVEL_54 : 0|1@0+ (1,0) [0|1] ""  IFV_VFP
 SG_ CAN_DET_AZIMUTH_54 : 47|14@0+ (0.0003834,-3.1416) [-3.1416|3.1396422] "rad"  IFV_VFP
 SG_ CAN_DET_RANGE_54 : 31|14@0+ (0.015625,0) [0|255.984375] "m"  IFV_VFP
 SG_ CAN_DET_RANGE_RATE_54 : 15|14@0+ (0.015625,-128) [-128|127.984375] "m/s"  IFV_VFP
 SG_ CAN_DET_AMPLITUDE_54 : 7|7@0+ (1,-64) [-64|63] "dBsm"  IFV_VFP
 SG_ CAN_SCAN_INDEX_2LSB_54 : 17|2@0+ (1,0) [0|3] ""  IFV_VFP

BO_ 340 MRR_Detection_053: 8 MRR
 SG_ CAN_SNR_LEVEL_53 : 33|2@0+ (1,0) [0|3] ""  IFV_VFP
 SG_ CAN_DET_SUPER_RES_TARGET_53 : 56|1@0+ (1,0) [0|1] ""  IFV_VFP
 SG_ CAN_DET_ND_TARGET_53 : 48|1@0+ (1,0) [0|1] ""  IFV_VFP
 SG_ CAN_DET_HOST_VEH_CLUTTER_53 : 49|1@0+ (1,0) [0|1] ""  IFV_VFP
 SG_ CAN_DET_VALID_LEVEL_53 : 0|1@0+ (1,0) [0|1] ""  IFV_VFP
 SG_ CAN_DET_AZIMUTH_53 : 47|14@0+ (0.0003834,-3.1416) [-3.1416|3.1396422] "rad"  IFV_VFP
 SG_ CAN_DET_RANGE_53 : 31|14@0+ (0.015625,0) [0|255.984375] "m"  IFV_VFP
 SG_ CAN_DET_RANGE_RATE_53 : 15|14@0+ (0.015625,-128) [-128|127.984375] "m/s"  IFV_VFP
 SG_ CAN_DET_AMPLITUDE_53 : 7|7@0+ (1,-64) [-64|63] "dBsm"  IFV_VFP
 SG_ CAN_SCAN_INDEX_2LSB_53 : 17|2@0+ (1,0) [0|3] ""  IFV_VFP

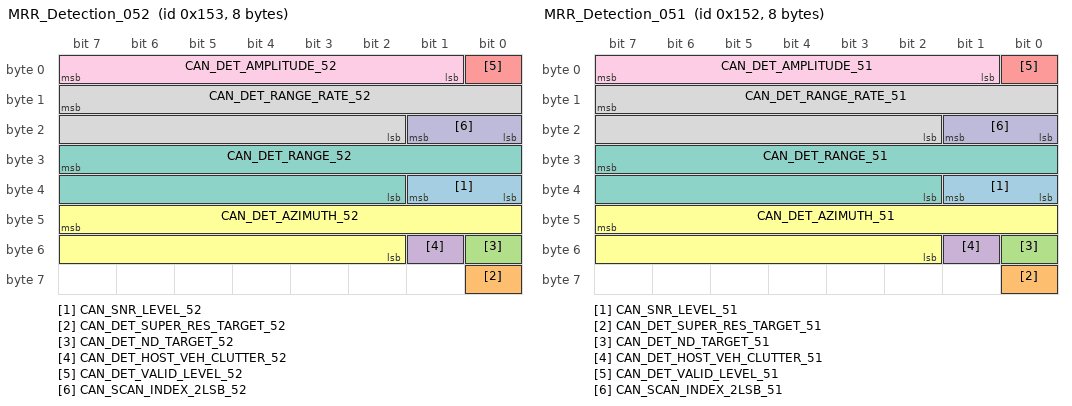
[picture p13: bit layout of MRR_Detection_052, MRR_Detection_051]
BO_ 339 MRR_Detection_052: 8 MRR
 SG_ CAN_SNR_LEVEL_52 : 33|2@0+ (1,0) [0|3] ""  IFV_VFP
 SG_ CAN_DET_SUPER_RES_TARGET_52 : 56|1@0+ (1,0) [0|1] ""  IFV_VFP
 SG_ CAN_DET_ND_TARGET_52 : 48|1@0+ (1,0) [0|1] ""  IFV_VFP
 SG_ CAN_DET_HOST_VEH_CLUTTER_52 : 49|1@0+ (1,0) [0|1] ""  IFV_VFP
 SG_ CAN_DET_VALID_LEVEL_52 : 0|1@0+ (1,0) [0|1] ""  IFV_VFP
 SG_ CAN_DET_AZIMUTH_52 : 47|14@0+ (0.0003834,-3.1416) [-3.1416|3.1396422] "rad"  IFV_VFP
 SG_ CAN_DET_RANGE_52 : 31|14@0+ (0.015625,0) [0|255.984375] "m"  IFV_VFP
 SG_ CAN_DET_RANGE_RATE_52 : 15|14@0+ (0.015625,-128) [-128|127.984375] "m/s"  IFV_VFP
 SG_ CAN_DET_AMPLITUDE_52 : 7|7@0+ (1,-64) [-64|63] "dBsm"  IFV_VFP
 SG_ CAN_SCAN_INDEX_2LSB_52 : 17|2@0+ (1,0) [0|3] ""  IFV_VFP

BO_ 338 MRR_Detection_051: 8 MRR
 SG_ CAN_SNR_LEVEL_51 : 33|2@0+ (1,0) [0|3] ""  IFV_VFP
 SG_ CAN_DET_SUPER_RES_TARGET_51 : 56|1@0+ (1,0) [0|1] ""  IFV_VFP
 SG_ CAN_DET_ND_TARGET_51 : 48|1@0+ (1,0) [0|1] ""  IFV_VFP
 SG_ CAN_DET_HOST_VEH_CLUTTER_51 : 49|1@0+ (1,0) [0|1] ""  IFV_VFP
 SG_ CAN_DET_VALID_LEVEL_51 : 0|1@0+ (1,0) [0|1] ""  IFV_VFP
 SG_ CAN_DET_AZIMUTH_51 : 47|14@0+ (0.0003834,-3.1416) [-3.1416|3.1396422] "rad"  IFV_VFP
 SG_ CAN_DET_RANGE_51 : 31|14@0+ (0.015625,0) [0|255.984375] "m"  IFV_VFP
 SG_ CAN_DET_RANGE_RATE_51 : 15|14@0+ (0.015625,-128) [-128|127.984375] "m/s"  IFV_VFP
 SG_ CAN_DET_AMPLITUDE_51 : 7|7@0+ (1,-64) [-64|63] "dBsm"  IFV_VFP
 SG_ CAN_SCAN_INDEX_2LSB_51 : 17|2@0+ (1,0) [0|3] ""  IFV_VFP

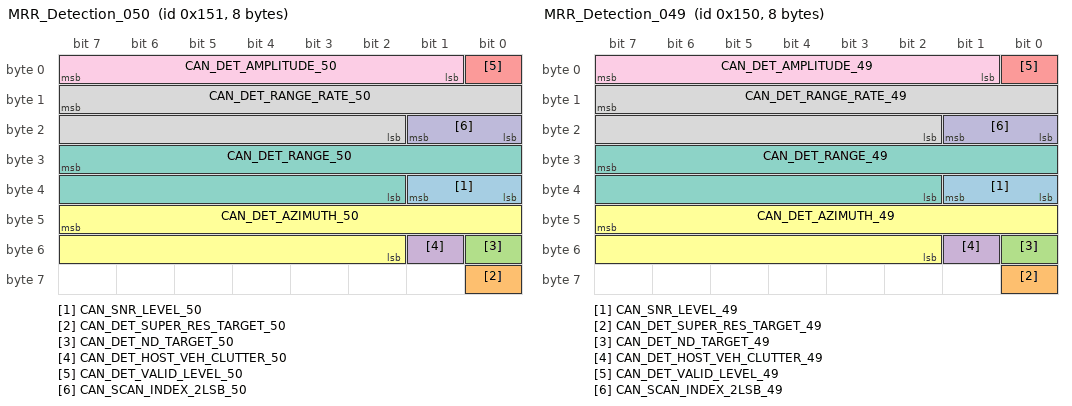
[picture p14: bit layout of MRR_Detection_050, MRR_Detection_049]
BO_ 337 MRR_Detection_050: 8 MRR
 SG_ CAN_SNR_LEVEL_50 : 33|2@0+ (1,0) [0|3] ""  IFV_VFP
 SG_ CAN_DET_SUPER_RES_TARGET_50 : 56|1@0+ (1,0) [0|1] ""  IFV_VFP
 SG_ CAN_DET_ND_TARGET_50 : 48|1@0+ (1,0) [0|1] ""  IFV_VFP
 SG_ CAN_DET_HOST_VEH_CLUTTER_50 : 49|1@0+ (1,0) [0|1] ""  IFV_VFP
 SG_ CAN_DET_VALID_LEVEL_50 : 0|1@0+ (1,0) [0|1] ""  IFV_VFP
 SG_ CAN_DET_AZIMUTH_50 : 47|14@0+ (0.0003834,-3.1416) [-3.1416|3.1396422] "rad"  IFV_VFP
 SG_ CAN_DET_RANGE_50 : 31|14@0+ (0.015625,0) [0|255.984375] "m"  IFV_VFP
 SG_ CAN_DET_RANGE_RATE_50 : 15|14@0+ (0.015625,-128) [-128|127.984375] "m/s"  IFV_VFP
 SG_ CAN_DET_AMPLITUDE_50 : 7|7@0+ (1,-64) [-64|63] "dBsm"  IFV_VFP
 SG_ CAN_SCAN_INDEX_2LSB_50 : 17|2@0+ (1,0) [0|3] ""  IFV_VFP

BO_ 336 MRR_Detection_049: 8 MRR
 SG_ CAN_SNR_LEVEL_49 : 33|2@0+ (1,0) [0|3] ""  IFV_VFP
 SG_ CAN_DET_SUPER_RES_TARGET_49 : 56|1@0+ (1,0) [0|1] ""  IFV_VFP
 SG_ CAN_DET_ND_TARGET_49 : 48|1@0+ (1,0) [0|1] ""  IFV_VFP
 SG_ CAN_DET_HOST_VEH_CLUTTER_49 : 49|1@0+ (1,0) [0|1] ""  IFV_VFP
 SG_ CAN_DET_VALID_LEVEL_49 : 0|1@0+ (1,0) [0|1] ""  IFV_VFP
 SG_ CAN_DET_AZIMUTH_49 : 47|14@0+ (0.0003834,-3.1416) [-3.1416|3.1396422] "rad"  IFV_VFP
 SG_ CAN_DET_RANGE_49 : 31|14@0+ (0.015625,0) [0|255.984375] "m"  IFV_VFP
 SG_ CAN_DET_RANGE_RATE_49 : 15|14@0+ (0.015625,-128) [-128|127.984375] "m/s"  IFV_VFP
 SG_ CAN_DET_AMPLITUDE_49 : 7|7@0+ (1,-64) [-64|63] "dBsm"  IFV_VFP
 SG_ CAN_SCAN_INDEX_2LSB_49 : 17|2@0+ (1,0) [0|3] ""  IFV_VFP

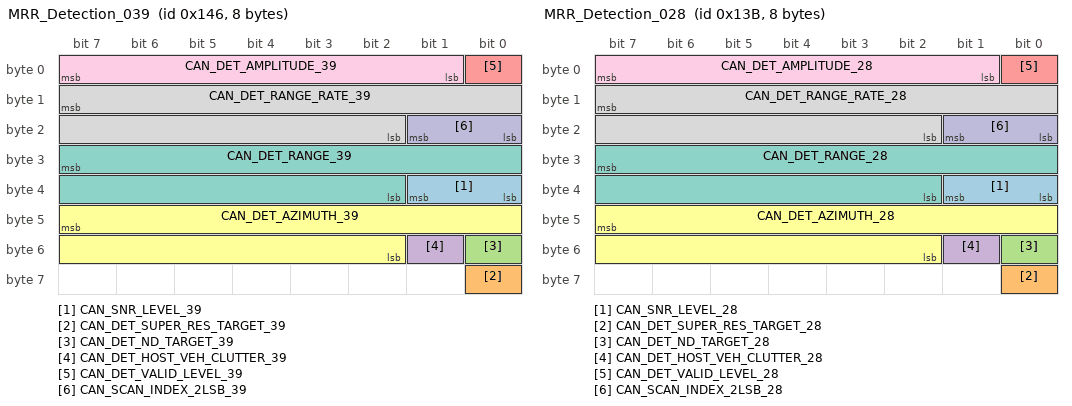
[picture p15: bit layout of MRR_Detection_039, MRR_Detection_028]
BO_ 326 MRR_Detection_039: 8 MRR
 SG_ CAN_SNR_LEVEL_39 : 33|2@0+ (1,0) [0|3] ""  IFV_VFP
 SG_ CAN_DET_SUPER_RES_TARGET_39 : 56|1@0+ (1,0) [0|1] ""  IFV_VFP
 SG_ CAN_DET_ND_TARGET_39 : 48|1@0+ (1,0) [0|1] ""  IFV_VFP
 SG_ CAN_DET_HOST_VEH_CLUTTER_39 : 49|1@0+ (1,0) [0|1] ""  IFV_VFP
 SG_ CAN_DET_VALID_LEVEL_39 : 0|1@0+ (1,0) [0|1] ""  IFV_VFP
 SG_ CAN_DET_AZIMUTH_39 : 47|14@0+ (0.0003834,-3.1416) [-3.1416|3.1396422] "rad"  IFV_VFP
 SG_ CAN_DET_RANGE_39 : 31|14@0+ (0.015625,0) [0|255.984375] "m"  IFV_VFP
 SG_ CAN_DET_RANGE_RATE_39 : 15|14@0+ (0.015625,-128) [-128|127.984375] "m/s"  IFV_VFP
 SG_ CAN_DET_AMPLITUDE_39 : 7|7@0+ (1,-64) [-64|63] "dBsm"  IFV_VFP
 SG_ CAN_SCAN_INDEX_2LSB_39 : 17|2@0+ (1,0) [0|3] ""  IFV_VFP

BO_ 315 MRR_Detection_028: 8 MRR
 SG_ CAN_SNR_LEVEL_28 : 33|2@0+ (1,0) [0|3] ""  IFV_VFP
 SG_ CAN_DET_SUPER_RES_TARGET_28 : 56|1@0+ (1,0) [0|1] ""  IFV_VFP
 SG_ CAN_DET_ND_TARGET_28 : 48|1@0+ (1,0) [0|1] ""  IFV_VFP
 SG_ CAN_DET_HOST_VEH_CLUTTER_28 : 49|1@0+ (1,0) [0|1] ""  IFV_VFP
 SG_ CAN_DET_VALID_LEVEL_28 : 0|1@0+ (1,0) [0|1] ""  IFV_VFP
 SG_ CAN_DET_AZIMUTH_28 : 47|14@0+ (0.0003834,-3.1416) [-3.1416|3.1396422] "rad"  IFV_VFP
 SG_ CAN_DET_RANGE_28 : 31|14@0+ (0.015625,0) [0|255.984375] "m"  IFV_VFP
 SG_ CAN_DET_RANGE_RATE_28 : 15|14@0+ (0.015625,-128) [-128|127.984375] "m/s"  IFV_VFP
 SG_ CAN_DET_AMPLITUDE_28 : 7|7@0+ (1,-64) [-64|63] "dBsm"  IFV_VFP
 SG_ CAN_SCAN_INDEX_2LSB_28 : 17|2@0+ (1,0) [0|3] ""  IFV_VFP

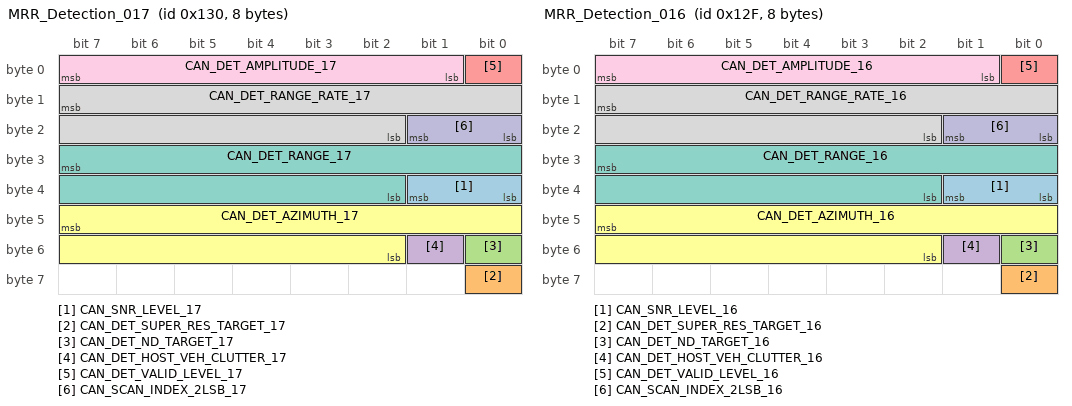
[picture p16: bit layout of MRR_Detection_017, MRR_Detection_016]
BO_ 304 MRR_Detection_017: 8 MRR
 SG_ CAN_SNR_LEVEL_17 : 33|2@0+ (1,0) [0|3] ""  IFV_VFP
 SG_ CAN_DET_SUPER_RES_TARGET_17 : 56|1@0+ (1,0) [0|1] ""  IFV_VFP
 SG_ CAN_DET_ND_TARGET_17 : 48|1@0+ (1,0) [0|1] ""  IFV_VFP
 SG_ CAN_DET_HOST_VEH_CLUTTER_17 : 49|1@0+ (1,0) [0|1] ""  IFV_VFP
 SG_ CAN_DET_VALID_LEVEL_17 : 0|1@0+ (1,0) [0|1] ""  IFV_VFP
 SG_ CAN_DET_AZIMUTH_17 : 47|14@0+ (0.0003834,-3.1416) [-3.1416|3.1396422] "rad"  IFV_VFP
 SG_ CAN_DET_RANGE_17 : 31|14@0+ (0.015625,0) [0|255.984375] "m"  IFV_VFP
 SG_ CAN_DET_RANGE_RATE_17 : 15|14@0+ (0.015625,-128) [-128|127.984375] "m/s"  IFV_VFP
 SG_ CAN_DET_AMPLITUDE_17 : 7|7@0+ (1,-64) [-64|63] "dBsm"  IFV_VFP
 SG_ CAN_SCAN_INDEX_2LSB_17 : 17|2@0+ (1,0) [0|3] ""  IFV_VFP

BO_ 303 MRR_Detection_016: 8 MRR
 SG_ CAN_SNR_LEVEL_16 : 33|2@0+ (1,0) [0|3] ""  IFV_VFP
 SG_ CAN_DET_SUPER_RES_TARGET_16 : 56|1@0+ (1,0) [0|1] ""  IFV_VFP
 SG_ CAN_DET_ND_TARGET_16 : 48|1@0+ (1,0) [0|1] ""  IFV_VFP
 SG_ CAN_DET_HOST_VEH_CLUTTER_16 : 49|1@0+ (1,0) [0|1] ""  IFV_VFP
 SG_ CAN_DET_VALID_LEVEL_16 : 0|1@0+ (1,0) [0|1] ""  IFV_VFP
 SG_ CAN_DET_AZIMUTH_16 : 47|14@0+ (0.0003834,-3.1416) [-3.1416|3.1396422] "rad"  IFV_VFP
 SG_ CAN_DET_RANGE_16 : 31|14@0+ (0.015625,0) [0|255.984375] "m"  IFV_VFP
 SG_ CAN_DET_RANGE_RATE_16 : 15|14@0+ (0.015625,-128) [-128|127.984375] "m/s"  IFV_VFP
 SG_ CAN_DET_AMPLITUDE_16 : 7|7@0+ (1,-64) [-64|63] "dBsm"  IFV_VFP
 SG_ CAN_SCAN_INDEX_2LSB_16 : 17|2@0+ (1,0) [0|3] ""  IFV_VFP

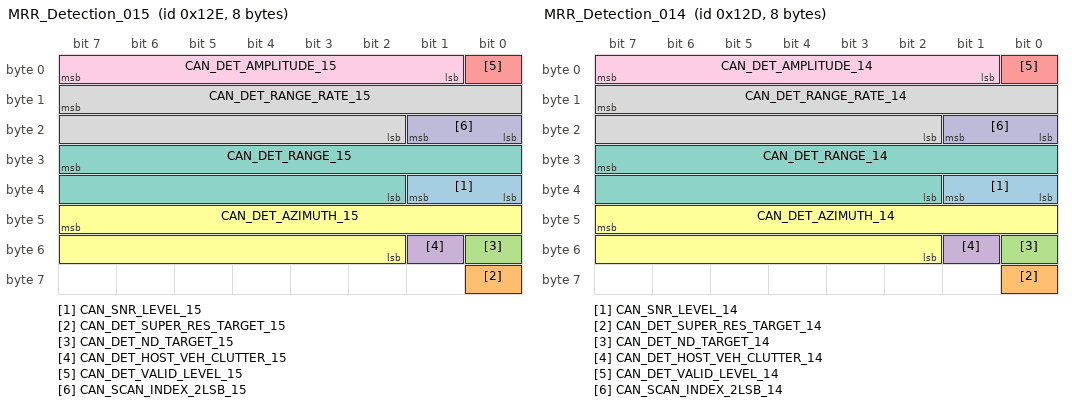
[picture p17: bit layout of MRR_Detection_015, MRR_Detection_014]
BO_ 302 MRR_Detection_015: 8 MRR
 SG_ CAN_SNR_LEVEL_15 : 33|2@0+ (1,0) [0|3] ""  IFV_VFP
 SG_ CAN_DET_SUPER_RES_TARGET_15 : 56|1@0+ (1,0) [0|1] ""  IFV_VFP
 SG_ CAN_DET_ND_TARGET_15 : 48|1@0+ (1,0) [0|1] ""  IFV_VFP
 SG_ CAN_DET_HOST_VEH_CLUTTER_15 : 49|1@0+ (1,0) [0|1] ""  IFV_VFP
 SG_ CAN_DET_VALID_LEVEL_15 : 0|1@0+ (1,0) [0|1] ""  IFV_VFP
 SG_ CAN_DET_AZIMUTH_15 : 47|14@0+ (0.0003834,-3.1416) [-3.1416|3.1396422] "rad"  IFV_VFP
 SG_ CAN_DET_RANGE_15 : 31|14@0+ (0.015625,0) [0|255.984375] "m"  IFV_VFP
 SG_ CAN_DET_RANGE_RATE_15 : 15|14@0+ (0.015625,-128) [-128|127.984375] "m/s"  IFV_VFP
 SG_ CAN_DET_AMPLITUDE_15 : 7|7@0+ (1,-64) [-64|63] "dBsm"  IFV_VFP
 SG_ CAN_SCAN_INDEX_2LSB_15 : 17|2@0+ (1,0) [0|3] ""  IFV_VFP

BO_ 301 MRR_Detection_014: 8 MRR
 SG_ CAN_SNR_LEVEL_14 : 33|2@0+ (1,0) [0|3] ""  IFV_VFP
 SG_ CAN_DET_SUPER_RES_TARGET_14 : 56|1@0+ (1,0) [0|1] ""  IFV_VFP
 SG_ CAN_DET_ND_TARGET_14 : 48|1@0+ (1,0) [0|1] ""  IFV_VFP
 SG_ CAN_DET_HOST_VEH_CLUTTER_14 : 49|1@0+ (1,0) [0|1] ""  IFV_VFP
 SG_ CAN_DET_VALID_LEVEL_14 : 0|1@0+ (1,0) [0|1] ""  IFV_VFP
 SG_ CAN_DET_AZIMUTH_14 : 47|14@0+ (0.0003834,-3.1416) [-3.1416|3.1396422] "rad"  IFV_VFP
 SG_ CAN_DET_RANGE_14 : 31|14@0+ (0.015625,0) [0|255.984375] "m"  IFV_VFP
 SG_ CAN_DET_RANGE_RATE_14 : 15|14@0+ (0.015625,-128) [-128|127.984375] "m/s"  IFV_VFP
 SG_ CAN_DET_AMPLITUDE_14 : 7|7@0+ (1,-64) [-64|63] "dBsm"  IFV_VFP
 SG_ CAN_SCAN_INDEX_2LSB_14 : 17|2@0+ (1,0) [0|3] ""  IFV_VFP

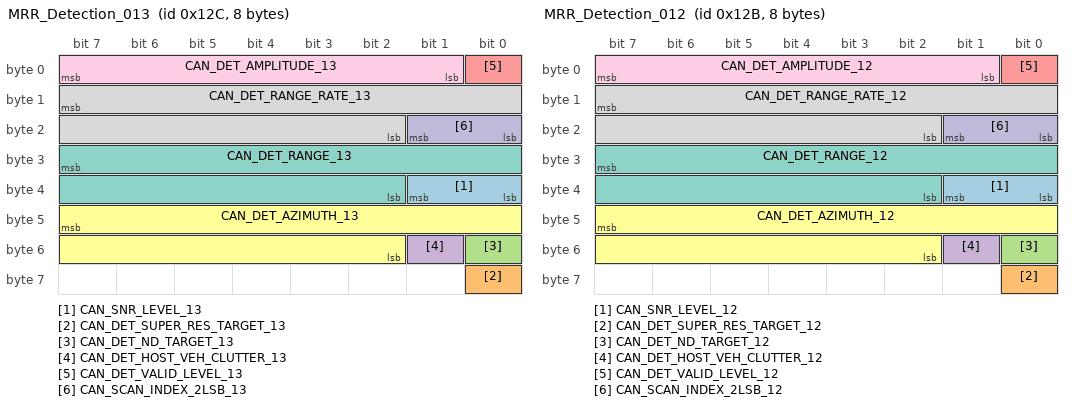
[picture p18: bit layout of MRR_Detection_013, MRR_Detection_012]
BO_ 300 MRR_Detection_013: 8 MRR
 SG_ CAN_SNR_LEVEL_13 : 33|2@0+ (1,0) [0|3] ""  IFV_VFP
 SG_ CAN_DET_SUPER_RES_TARGET_13 : 56|1@0+ (1,0) [0|1] ""  IFV_VFP
 SG_ CAN_DET_ND_TARGET_13 : 48|1@0+ (1,0) [0|1] ""  IFV_VFP
 SG_ CAN_DET_HOST_VEH_CLUTTER_13 : 49|1@0+ (1,0) [0|1] ""  IFV_VFP
 SG_ CAN_DET_VALID_LEVEL_13 : 0|1@0+ (1,0) [0|1] ""  IFV_VFP
 SG_ CAN_DET_AZIMUTH_13 : 47|14@0+ (0.0003834,-3.1416) [-3.1416|3.1396422] "rad"  IFV_VFP
 SG_ CAN_DET_RANGE_13 : 31|14@0+ (0.015625,0) [0|255.984375] "m"  IFV_VFP
 SG_ CAN_DET_RANGE_RATE_13 : 15|14@0+ (0.015625,-128) [-128|127.984375] "m/s"  IFV_VFP
 SG_ CAN_DET_AMPLITUDE_13 : 7|7@0+ (1,-64) [-64|63] "dBsm"  IFV_VFP
 SG_ CAN_SCAN_INDEX_2LSB_13 : 17|2@0+ (1,0) [0|3] ""  IFV_VFP

BO_ 299 MRR_Detection_012: 8 MRR
 SG_ CAN_SNR_LEVEL_12 : 33|2@0+ (1,0) [0|3] ""  IFV_VFP
 SG_ CAN_DET_SUPER_RES_TARGET_12 : 56|1@0+ (1,0) [0|1] ""  IFV_VFP
 SG_ CAN_DET_ND_TARGET_12 : 48|1@0+ (1,0) [0|1] ""  IFV_VFP
 SG_ CAN_DET_HOST_VEH_CLUTTER_12 : 49|1@0+ (1,0) [0|1] ""  IFV_VFP
 SG_ CAN_DET_VALID_LEVEL_12 : 0|1@0+ (1,0) [0|1] ""  IFV_VFP
 SG_ CAN_DET_AZIMUTH_12 : 47|14@0+ (0.0003834,-3.1416) [-3.1416|3.1396422] "rad"  IFV_VFP
 SG_ CAN_DET_RANGE_12 : 31|14@0+ (0.015625,0) [0|255.984375] "m"  IFV_VFP
 SG_ CAN_DET_RANGE_RATE_12 : 15|14@0+ (0.015625,-128) [-128|127.984375] "m/s"  IFV_VFP
 SG_ CAN_DET_AMPLITUDE_12 : 7|7@0+ (1,-64) [-64|63] "dBsm"  IFV_VFP
 SG_ CAN_SCAN_INDEX_2LSB_12 : 17|2@0+ (1,0) [0|3] ""  IFV_VFP

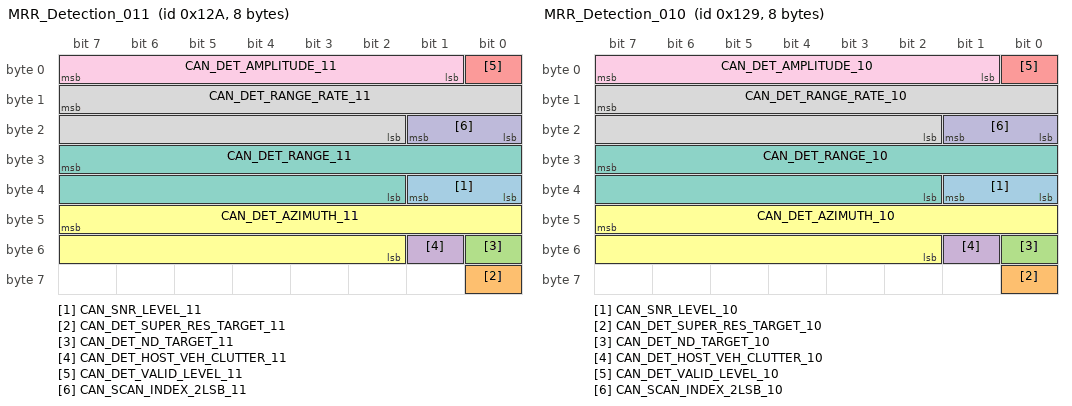
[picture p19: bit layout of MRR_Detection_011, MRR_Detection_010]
BO_ 298 MRR_Detection_011: 8 MRR
 SG_ CAN_SNR_LEVEL_11 : 33|2@0+ (1,0) [0|3] ""  IFV_VFP
 SG_ CAN_DET_SUPER_RES_TARGET_11 : 56|1@0+ (1,0) [0|1] ""  IFV_VFP
 SG_ CAN_DET_ND_TARGET_11 : 48|1@0+ (1,0) [0|1] ""  IFV_VFP
 SG_ CAN_DET_HOST_VEH_CLUTTER_11 : 49|1@0+ (1,0) [0|1] ""  IFV_VFP
 SG_ CAN_DET_VALID_LEVEL_11 : 0|1@0+ (1,0) [0|1] ""  IFV_VFP
 SG_ CAN_DET_AZIMUTH_11 : 47|14@0+ (0.0003834,-3.1416) [-3.1416|3.1396422] "rad"  IFV_VFP
 SG_ CAN_DET_RANGE_11 : 31|14@0+ (0.015625,0) [0|255.984375] "m"  IFV_VFP
 SG_ CAN_DET_RANGE_RATE_11 : 15|14@0+ (0.015625,-128) [-128|127.984375] "m/s"  IFV_VFP
 SG_ CAN_DET_AMPLITUDE_11 : 7|7@0+ (1,-64) [-64|63] "dBsm"  IFV_VFP
 SG_ CAN_SCAN_INDEX_2LSB_11 : 17|2@0+ (1,0) [0|3] ""  IFV_VFP

BO_ 297 MRR_Detection_010: 8 MRR
 SG_ CAN_SNR_LEVEL_10 : 33|2@0+ (1,0) [0|3] ""  IFV_VFP
 SG_ CAN_DET_SUPER_RES_TARGET_10 : 56|1@0+ (1,0) [0|1] ""  IFV_VFP
 SG_ CAN_DET_ND_TARGET_10 : 48|1@0+ (1,0) [0|1] ""  IFV_VFP
 SG_ CAN_DET_HOST_VEH_CLUTTER_10 : 49|1@0+ (1,0) [0|1] ""  IFV_VFP
 SG_ CAN_DET_VALID_LEVEL_10 : 0|1@0+ (1,0) [0|1] ""  IFV_VFP
 SG_ CAN_DET_AZIMUTH_10 : 47|14@0+ (0.0003834,-3.1416) [-3.1416|3.1396422] "rad"  IFV_VFP
 SG_ CAN_DET_RANGE_10 : 31|14@0+ (0.015625,0) [0|255.984375] "m"  IFV_VFP
 SG_ CAN_DET_RANGE_RATE_10 : 15|14@0+ (0.015625,-128) [-128|127.984375] "m/s"  IFV_VFP
 SG_ CAN_DET_AMPLITUDE_10 : 7|7@0+ (1,-64) [-64|63] "dBsm"  IFV_VFP
 SG_ CAN_SCAN_INDEX_2LSB_10 : 17|2@0+ (1,0) [0|3] ""  IFV_VFP

BO_ 296 MRR_Detection_009: 8 MRR
 SG_ CAN_SNR_LEVEL_09 : 33|2@0+ (1,0) [0|3] ""  IFV_VFP
 SG_ CAN_DET_SUPER_RES_TARGET_09 : 56|1@0+ (1,0) [0|1] ""  IFV_VFP
 SG_ CAN_DET_ND_TARGET_09 : 48|1@0+ (1,0) [0|1] ""  IFV_VFP
 SG_ CAN_DET_HOST_VEH_CLUTTER_09 : 49|1@0+ (1,0) [0|1] ""  IFV_VFP
 SG_ CAN_DET_VALID_LEVEL_09 : 0|1@0+ (1,0) [0|1] ""  IFV_VFP
 SG_ CAN_DET_AZIMUTH_09 : 47|14@0+ (0.0003834,-3.1416) [-3.1416|3.1396422] "rad"  IFV_VFP
 SG_ CAN_DET_RANGE_09 : 31|14@0+ (0.015625,0) [0|255.984375] "m"  IFV_VFP
 SG_ CAN_DET_RANGE_RATE_09 : 15|14@0+ (0.015625,-128) [-128|127.984375] "m/s"  IFV_VFP
 SG_ CAN_DET_AMPLITUDE_09 : 7|7@0+ (1,-64) [-64|63] "dBsm"  IFV_VFP
 SG_ CAN_SCAN_INDEX_2LSB_09 : 17|2@0+ (1,0) [0|3] ""  IFV_VFP

BO_ 295 MRR_Detection_008: 8 MRR
 SG_ CAN_SNR_LEVEL_08 : 33|2@0+ (1,0) [0|3] ""  IFV_VFP
 SG_ CAN_DET_SUPER_RES_TARGET_08 : 56|1@0+ (1,0) [0|1] ""  IFV_VFP
 SG_ CAN_DET_ND_TARGET_08 : 48|1@0+ (1,0) [0|1] ""  IFV_VFP
 SG_ CAN_DET_HOST_VEH_CLUTTER_08 : 49|1@0+ (1,0) [0|1] ""  IFV_VFP
 SG_ CAN_DET_VALID_LEVEL_08 : 0|1@0+ (1,0) [0|1] ""  IFV_VFP
 SG_ CAN_DET_AZIMUTH_08 : 47|14@0+ (0.0003834,-3.1416) [-3.1416|3.1396422] "rad"  IFV_VFP
 SG_ CAN_DET_RANGE_08 : 31|14@0+ (0.015625,0) [0|255.984375] "m"  IFV_VFP
 SG_ CAN_DET_RANGE_RATE_08 : 15|14@0+ (0.015625,-128) [-128|127.984375] "m/s"  IFV_VFP
 SG_ CAN_DET_AMPLITUDE_08 : 7|7@0+ (1,-64) [-64|63] "dBsm"  IFV_VFP
 SG_ CAN_SCAN_INDEX_2LSB_08 : 17|2@0+ (1,0) [0|3] ""  IFV_VFP

BO_ 294 MRR_Detection_007: 8 MRR
 SG_ CAN_SNR_LEVEL_07 : 33|2@0+ (1,0) [0|3] ""  IFV_VFP
 SG_ CAN_DET_SUPER_RES_TARGET_07 : 56|1@0+ (1,0) [0|1] ""  IFV_VFP
 SG_ CAN_DET_ND_TARGET_07 : 48|1@0+ (1,0) [0|1] ""  IFV_VFP
 SG_ CAN_DET_HOST_VEH_CLUTTER_07 : 49|1@0+ (1,0) [0|1] ""  IFV_VFP
 SG_ CAN_DET_VALID_LEVEL_07 : 0|1@0+ (1,0) [0|1] ""  IFV_VFP
 SG_ CAN_DET_AZIMUTH_07 : 47|14@0+ (0.0003834,-3.1416) [-3.1416|3.1396422] "rad"  IFV_VFP
 SG_ CAN_DET_RANGE_07 : 31|14@0+ (0.015625,0) [0|255.984375] "m"  IFV_VFP
 SG_ CAN_DET_RANGE_RATE_07 : 15|14@0+ (0.015625,-128) [-128|127.984375] "m/s"  IFV_VFP
 SG_ CAN_DET_AMPLITUDE_07 : 7|7@0+ (1,-64) [-64|63] "dBsm"  IFV_VFP
 SG_ CAN_SCAN_INDEX_2LSB_07 : 17|2@0+ (1,0) [0|3] ""  IFV_VFP

BO_ 293 MRR_Detection_006: 8 MRR
 SG_ CAN_SNR_LEVEL_06 : 33|2@0+ (1,0) [0|3] ""  IFV_VFP
 SG_ CAN_DET_SUPER_RES_TARGET_06 : 56|1@0+ (1,0) [0|1] ""  IFV_VFP
 SG_ CAN_DET_ND_TARGET_06 : 48|1@0+ (1,0) [0|1] ""  IFV_VFP
 SG_ CAN_DET_HOST_VEH_CLUTTER_06 : 49|1@0+ (1,0) [0|1] ""  IFV_VFP
 SG_ CAN_DET_VALID_LEVEL_06 : 0|1@0+ (1,0) [0|1] ""  IFV_VFP
 SG_ CAN_DET_AZIMUTH_06 : 47|14@0+ (0.0003834,-3.1416) [-3.1416|3.1396422] "rad"  IFV_VFP
 SG_ CAN_DET_RANGE_06 : 31|14@0+ (0.015625,0) [0|255.984375] "m"  IFV_VFP
 SG_ CAN_DET_RANGE_RATE_06 : 15|14@0+ (0.015625,-128) [-128|127.984375] "m/s"  IFV_VFP
 SG_ CAN_DET_AMPLITUDE_06 : 7|7@0+ (1,-64) [-64|63] "dBsm"  IFV_VFP
 SG_ CAN_SCAN_INDEX_2LSB_06 : 17|2@0+ (1,0) [0|3] ""  IFV_VFP

BO_ 292 MRR_Detection_005: 8 MRR
 SG_ CAN_SNR_LEVEL_05 : 33|2@0+ (1,0) [0|3] ""  IFV_VFP
 SG_ CAN_DET_SUPER_RES_TARGET_05 : 56|1@0+ (1,0) [0|1] ""  IFV_VFP
 SG_ CAN_DET_ND_TARGET_05 : 48|1@0+ (1,0) [0|1] ""  IFV_VFP
 SG_ CAN_DET_HOST_VEH_CLUTTER_05 : 49|1@0+ (1,0) [0|1] ""  IFV_VFP
 SG_ CAN_DET_VALID_LEVEL_05 : 0|1@0+ (1,0) [0|1] ""  IFV_VFP
 SG_ CAN_DET_AZIMUTH_05 : 47|14@0+ (0.0003834,-3.1416) [-3.1416|3.1396422] "rad"  IFV_VFP
 SG_ CAN_DET_RANGE_05 : 31|14@0+ (0.015625,0) [0|255.984375] "m"  IFV_VFP
 SG_ CAN_DET_RANGE_RATE_05 : 15|14@0+ (0.015625,-128) [-128|127.984375] "m/s"  IFV_VFP
 SG_ CAN_DET_AMPLITUDE_05 : 7|7@0+ (1,-64) [-64|63] "dBsm"  IFV_VFP
 SG_ CAN_SCAN_INDEX_2LSB_05 : 17|2@0+ (1,0) [0|3] ""  IFV_VFP

BO_ 290 MRR_Detection_003: 8 MRR
 SG_ CAN_SNR_LEVEL_03 : 33|2@0+ (1,0) [0|3] ""  IFV_VFP
 SG_ CAN_DET_SUPER_RES_TARGET_03 : 56|1@0+ (1,0) [0|1] ""  IFV_VFP
 SG_ CAN_DET_ND_TARGET_03 : 48|1@0+ (1,0) [0|1] ""  IFV_VFP
 SG_ CAN_DET_HOST_VEH_CLUTTER_03 : 49|1@0+ (1,0) [0|1] ""  IFV_VFP
 SG_ CAN_DET_VALID_LEVEL_03 : 0|1@0+ (1,0) [0|1] ""  IFV_VFP
 SG_ CAN_DET_AZIMUTH_03 : 47|14@0+ (0.0003834,-3.1416) [-3.1416|3.1396422] "rad"  IFV_VFP
 SG_ CAN_DET_RANGE_03 : 31|14@0+ (0.015625,0) [0|255.984375] "m"  IFV_VFP
 SG_ CAN_DET_RANGE_RATE_03 : 15|14@0+ (0.015625,-128) [-128|127.984375] "m/s"  IFV_VFP
 SG_ CAN_DET_AMPLITUDE_03 : 7|7@0+ (1,-64) [-64|63] "dBsm"  IFV_VFP
 SG_ CAN_SCAN_INDEX_2LSB_03 : 17|2@0+ (1,0) [0|3] ""  IFV_VFP

BO_ 289 MRR_Detection_002: 8 MRR
 SG_ CAN_SNR_LEVEL_02 : 33|2@0+ (1,0) [0|3] ""  IFV_VFP
 SG_ CAN_DET_SUPER_RES_TARGET_02 : 56|1@0+ (1,0) [0|1] ""  IFV_VFP
 SG_ CAN_DET_ND_TARGET_02 : 48|1@0+ (1,0) [0|1] ""  IFV_VFP
 SG_ CAN_DET_HOST_VEH_CLUTTER_02 : 49|1@0+ (1,0) [0|1] ""  IFV_VFP
 SG_ CAN_DET_VALID_LEVEL_02 : 0|1@0+ (1,0) [0|1] ""  IFV_VFP
 SG_ CAN_DET_AZIMUTH_02 : 47|14@0+ (0.0003834,-3.1416) [-3.1416|3.1396422] "rad"  IFV_VFP
 SG_ CAN_DET_RANGE_02 : 31|14@0+ (0.015625,0) [0|255.984375] "m"  IFV_VFP
 SG_ CAN_DET_RANGE_RATE_02 : 15|14@0+ (0.015625,-128) [-128|127.984375] "m/s"  IFV_VFP
 SG_ CAN_DET_AMPLITUDE_02 : 7|7@0+ (1,-64) [-64|63] "dBsm"  IFV_VFP
 SG_ CAN_SCAN_INDEX_2LSB_02 : 17|2@0+ (1,0) [0|3] ""  IFV_VFP

BO_ 288 MRR_Detection_001: 8 MRR
 SG_ CAN_SNR_LEVEL_01 : 33|2@0+ (1,0) [0|3] ""  IFV_VFP
 SG_ CAN_DET_SUPER_RES_TARGET_01 : 56|1@0+ (1,0) [0|1] ""  IFV_VFP
 SG_ CAN_DET_ND_TARGET_01 : 48|1@0+ (1,0) [0|1] ""  IFV_VFP
 SG_ CAN_DET_HOST_VEH_CLUTTER_01 : 49|1@0+ (1,0) [0|1] ""  IFV_VFP
 SG_ CAN_DET_VALID_LEVEL_01 : 0|1@0+ (1,0) [0|1] ""  IFV_VFP
 SG_ CAN_DET_AZIMUTH_01 : 47|14@0+ (0.0003834,-3.1416) [-3.1416|3.1396422] "rad"  IFV_VFP
 SG_ CAN_DET_RANGE_01 : 31|14@0+ (0.015625,0) [0|255.984375] "m"  IFV_VFP
 SG_ CAN_DET_RANGE_RATE_01 : 15|14@0+ (0.015625,-128) [-128|127.984375] "m/s"  IFV_VFP
 SG_ CAN_DET_AMPLITUDE_01 : 7|7@0+ (1,-64) [-64|63] "dBsm"  IFV_VFP
 SG_ CAN_SCAN_INDEX_2LSB_01 : 17|2@0+ (1,0) [0|3] ""  IFV_VFP

BA_DEF_ SG_  "CrossOver_InfoCAN" ENUM  "No","Yes";
BA_DEF_ SG_  "CrossOver_LIN" ENUM  "No","Yes";
BA_DEF_ SG_  "UsedOnPgmDBC" ENUM  "No","Yes";
BA_DEF_ SG_  "GenSigTimeoutTime_RCM" INT 0 100000;
BA_DEF_ SG_  "GenSigTimeoutTime_OCS" INT 0 100000;
BA_DEF_ SG_  "GenSigTimeoutTime_ABS_ESC" INT 0 100000;
BA_DEF_ SG_  "GenSigTimeoutTime_CCM" INT 0 100000;
BA_DEF_ SG_  "GenSigTimeoutTime_IPMA" INT 0 100000;
BA_DEF_ SG_  "GenSigTimeoutTime_SCCM" INT 0 100000;
BA_DEF_ SG_  "GenSigTimeoutTime_PSCM" INT 0 100000;
BA_DEF_ BO_  "EventRateOfChange" INT 10 10000;
BA_DEF_ SG_  "GenSigVtName" STRING ;
BA_DEF_ SG_  "GenSigVtEn" STRING ;
BA_DEF_ SG_  "GenSigCmt" STRING ;
BA_DEF_ SG_  "GenSigSendType" ENUM  "Cyclic","OnWrite","vector_leerstring","OnChange","vector_leerstring","IfActive","vector_leerstring","NoSigSendType";
BA_DEF_ SG_  "GenSigStartValue" INT 0 1000000000;
BA_DEF_ BO_  "GenMsgILSupport" ENUM  "No","Yes";
BA_DEF_ BO_  "GenMsgSendType" ENUM  "FixedPeriodic","Event","EnabledPeriodic","NotUsed","NotUsed","EventPeriodic","NotUsed","NotUsed","NoMsgSendType";
BA_DEF_ BO_  "GenMsgCycleTime" INT 0 100000;
BA_DEF_ BO_  "GenMsgDelayTime" INT 0 1000;
BA_DEF_ BO_  "GenMsgNrOfRepetition" INT 0 100;
BA_DEF_ BO_  "NetworkInitialization" ENUM  "No","Yes";
BA_DEF_ SG_  "SystemSignalLongSymbol" STRING ;
BA_DEF_DEF_  "CrossOver_InfoCAN" "No";
BA_DEF_DEF_  "CrossOver_LIN" "No";
BA_DEF_DEF_  "UsedOnPgmDBC" "Yes";
BA_DEF_DEF_  "GenSigTimeoutTime_RCM" 0;
BA_DEF_DEF_  "GenSigTimeoutTime_OCS" 0;
BA_DEF_DEF_  "GenSigTimeoutTime_ABS_ESC" 0;
BA_DEF_DEF_  "GenSigTimeoutTime_CCM" 0;
BA_DEF_DEF_  "GenSigTimeoutTime_IPMA" 0;
BA_DEF_DEF_  "GenSigTimeoutTime_SCCM" 0;
BA_DEF_DEF_  "GenSigTimeoutTime_PSCM" 0;
BA_DEF_DEF_  "EventRateOfChange" 10000;
BA_DEF_DEF_  "GenSigVtName" "";
BA_DEF_DEF_  "GenSigVtEn" "";
BA_DEF_DEF_  "GenSigCmt" "";
BA_DEF_DEF_  "GenSigSendType" "NoSigSendType";
BA_DEF_DEF_  "GenSigStartValue" 0;
BA_DEF_DEF_  "GenMsgILSupport" "Yes";
BA_DEF_DEF_  "GenMsgSendType" "NoMsgSendType";
BA_DEF_DEF_  "GenMsgCycleTime" 0;
BA_DEF_DEF_  "GenMsgDelayTime" 0;
BA_DEF_DEF_  "GenMsgNrOfRepetition" 0;
BA_DEF_DEF_  "NetworkInitialization" "No";
BA_DEF_DEF_  "SystemSignalLongSymbol" "";
BA_ "GenMsgSendType" BO_ 330 1;
BA_ "GenMsgSendType" BO_ 329 1;
BA_ "GenMsgSendType" BO_ 328 1;
BA_ "GenMsgSendType" BO_ 327 1;
BA_ "GenMsgSendType" BO_ 325 1;
BA_ "GenMsgSendType" BO_ 324 1;
BA_ "GenMsgSendType" BO_ 323 1;
BA_ "GenMsgSendType" BO_ 322 1;
BA_ "GenMsgSendType" BO_ 321 1;
BA_ "GenMsgSendType" BO_ 320 1;
BA_ "GenMsgSendType" BO_ 319 1;
BA_ "GenMsgSendType" BO_ 318 1;
BA_ "GenMsgSendType" BO_ 317 1;
BA_ "GenMsgSendType" BO_ 316 1;
BA_ "GenMsgSendType" BO_ 314 1;
BA_ "GenMsgSendType" BO_ 313 1;
BA_ "GenMsgSendType" BO_ 312 1;
BA_ "GenMsgSendType" BO_ 311 1;
BA_ "GenMsgSendType" BO_ 310 1;
BA_ "GenMsgSendType" BO_ 309 1;
BA_ "GenMsgSendType" BO_ 308 1;
BA_ "GenMsgSendType" BO_ 307 1;
BA_ "GenMsgSendType" BO_ 306 1;
BA_ "GenMsgSendType" BO_ 305 1;
BA_ "GenMsgSendType" BO_ 341 1;
BA_ "GenMsgSendType" BO_ 340 1;
BA_ "GenMsgSendType" BO_ 339 1;
BA_ "GenMsgSendType" BO_ 338 1;
BA_ "GenMsgSendType" BO_ 337 1;
BA_ "GenMsgSendType" BO_ 336 1;
BA_ "GenMsgSendType" BO_ 326 1;
BA_ "GenMsgSendType" BO_ 315 1;
BA_ "GenMsgSendType" BO_ 304 1;
BA_ "GenMsgSendType" BO_ 303 1;
BA_ "GenMsgSendType" BO_ 302 1;
BA_ "GenMsgSendType" BO_ 301 1;
BA_ "GenMsgSendType" BO_ 300 1;
BA_ "GenMsgSendType" BO_ 299 1;
BA_ "GenMsgSendType" BO_ 298 1;
BA_ "GenMsgSendType" BO_ 297 1;
BA_ "GenMsgSendType" BO_ 296 1;
BA_ "GenMsgSendType" BO_ 295 1;
BA_ "GenMsgSendType" BO_ 294 1;
BA_ "GenMsgSendType" BO_ 293 1;
BA_ "GenMsgSendType" BO_ 292 1;
BA_ "GenMsgSendType" BO_ 290 1;
BA_ "GenMsgSendType" BO_ 289 1;
BA_ "GenMsgSendType" BO_ 288 1;
BA_ "GenSigCmt" SG_ 330 CAN_SNR_LEVEL_43 "Signal to noise level 43";
BA_ "GenSigSendType" SG_ 330 CAN_SNR_LEVEL_43 1;
BA_ "GenSigVtName" SG_ 330 CAN_SNR_LEVEL_43 "VtSig_CAN_SNR_LEVEL_43";
BA_ "GenSigVtEn" SG_ 330 CAN_SNR_LEVEL_43 "TRUE";
BA_ "GenSigCmt" SG_ 330 CAN_DET_SUPER_RES_TARGET_43 "Super resolution target 43";
BA_ "GenSigSendType" SG_ 330 CAN_DET_SUPER_RES_TARGET_43 1;
BA_ "GenSigCmt" SG_ 330 CAN_DET_ND_TARGET_43 "Near discrimination target 43";
BA_ "GenSigSendType" SG_ 330 CAN_DET_ND_TARGET_43 1;
BA_ "GenSigCmt" SG_ 330 CAN_DET_HOST_VEH_CLUTTER_43 "Host vehicle clutter 43";
BA_ "GenSigSendType" SG_ 330 CAN_DET_HOST_VEH_CLUTTER_43 1;
BA_ "GenSigCmt" SG_ 330 CAN_DET_VALID_LEVEL_43 "Detected object valid level 43";
BA_ "GenSigSendType" SG_ 330 CAN_DET_VALID_LEVEL_43 1;
BA_ "GenSigCmt" SG_ 330 CAN_DET_AZIMUTH_43 "Detected object azimuth position 43";
BA_ "GenSigSendType" SG_ 330 CAN_DET_AZIMUTH_43 1;
BA_ "GenSigStartValue" SG_ 330 CAN_DET_AZIMUTH_43 8194;
BA_ "GenSigCmt" SG_ 330 CAN_DET_RANGE_43 "Detected object range 43";
BA_ "GenSigSendType" SG_ 330 CAN_DET_RANGE_43 1;
BA_ "GenSigCmt" SG_ 330 CAN_DET_RANGE_RATE_43 "Detected object range rate 43";
BA_ "GenSigSendType" SG_ 330 CAN_DET_RANGE_RATE_43 1;
BA_ "GenSigStartValue" SG_ 330 CAN_DET_RANGE_RATE_43 8192;
BA_ "GenSigCmt" SG_ 330 CAN_DET_AMPLITUDE_43 "Detected object amplitude 43";
BA_ "GenSigSendType" SG_ 330 CAN_DET_AMPLITUDE_43 1;
BA_ "GenSigCmt" SG_ 330 CAN_SCAN_INDEX_2LSB_43 "The two LSB of scan index 43";
BA_ "GenSigSendType" SG_ 330 CAN_SCAN_INDEX_2LSB_43 1;
BA_ "GenSigCmt" SG_ 329 CAN_SNR_LEVEL_42 "Signal to noise level 42";
BA_ "GenSigSendType" SG_ 329 CAN_SNR_LEVEL_42 1;
BA_ "GenSigVtName" SG_ 329 CAN_SNR_LEVEL_42 "VtSig_CAN_SNR_LEVEL_42";
BA_ "GenSigVtEn" SG_ 329 CAN_SNR_LEVEL_42 "TRUE";
BA_ "GenSigCmt" SG_ 329 CAN_DET_SUPER_RES_TARGET_42 "Super resolution target 42";
BA_ "GenSigSendType" SG_ 329 CAN_DET_SUPER_RES_TARGET_42 1;
BA_ "GenSigCmt" SG_ 329 CAN_DET_ND_TARGET_42 "Near discrimination target 42";
BA_ "GenSigSendType" SG_ 329 CAN_DET_ND_TARGET_42 1;
BA_ "GenSigCmt" SG_ 329 CAN_DET_HOST_VEH_CLUTTER_42 "Host vehicle clutter 42";
BA_ "GenSigSendType" SG_ 329 CAN_DET_HOST_VEH_CLUTTER_42 1;
BA_ "GenSigCmt" SG_ 329 CAN_DET_VALID_LEVEL_42 "Detected object valid level 42";
BA_ "GenSigSendType" SG_ 329 CAN_DET_VALID_LEVEL_42 1;
BA_ "GenSigCmt" SG_ 329 CAN_DET_AZIMUTH_42 "Detected object azimuth position 42";
BA_ "GenSigSendType" SG_ 329 CAN_DET_AZIMUTH_42 1;
BA_ "GenSigStartValue" SG_ 329 CAN_DET_AZIMUTH_42 8194;
BA_ "GenSigCmt" SG_ 329 CAN_DET_RANGE_42 "Detected object range 42";
BA_ "GenSigSendType" SG_ 329 CAN_DET_RANGE_42 1;
BA_ "GenSigCmt" SG_ 329 CAN_DET_RANGE_RATE_42 "Detected object range rate 42";
BA_ "GenSigSendType" SG_ 329 CAN_DET_RANGE_RATE_42 1;
BA_ "GenSigStartValue" SG_ 329 CAN_DET_RANGE_RATE_42 8192;
BA_ "GenSigCmt" SG_ 329 CAN_DET_AMPLITUDE_42 "Detected object amplitude 42";
BA_ "GenSigSendType" SG_ 329 CAN_DET_AMPLITUDE_42 1;
BA_ "GenSigCmt" SG_ 329 CAN_SCAN_INDEX_2LSB_42 "The two LSB of scan index 42";
BA_ "GenSigSendType" SG_ 329 CAN_SCAN_INDEX_2LSB_42 1;
BA_ "GenSigCmt" SG_ 328 CAN_SNR_LEVEL_41 "Signal to noise level 41";
BA_ "GenSigSendType" SG_ 328 CAN_SNR_LEVEL_41 1;
BA_ "GenSigVtName" SG_ 328 CAN_SNR_LEVEL_41 "VtSig_CAN_SNR_LEVEL_41";
BA_ "GenSigVtEn" SG_ 328 CAN_SNR_LEVEL_41 "TRUE";
BA_ "GenSigCmt" SG_ 328 CAN_DET_SUPER_RES_TARGET_41 "Super resolution target 41";
BA_ "GenSigSendType" SG_ 328 CAN_DET_SUPER_RES_TARGET_41 1;
BA_ "GenSigCmt" SG_ 328 CAN_DET_ND_TARGET_41 "Near discrimination target 41";
BA_ "GenSigSendType" SG_ 328 CAN_DET_ND_TARGET_41 1;
BA_ "GenSigCmt" SG_ 328 CAN_DET_HOST_VEH_CLUTTER_41 "Host vehicle clutter 41";
BA_ "GenSigSendType" SG_ 328 CAN_DET_HOST_VEH_CLUTTER_41 1;
BA_ "GenSigCmt" SG_ 328 CAN_DET_VALID_LEVEL_41 "Detected object valid level 41";
BA_ "GenSigSendType" SG_ 328 CAN_DET_VALID_LEVEL_41 1;
BA_ "GenSigCmt" SG_ 328 CAN_DET_AZIMUTH_41 "Detected object azimuth position 41";
BA_ "GenSigSendType" SG_ 328 CAN_DET_AZIMUTH_41 1;
BA_ "GenSigStartValue" SG_ 328 CAN_DET_AZIMUTH_41 8194;
BA_ "GenSigCmt" SG_ 328 CAN_DET_RANGE_41 "Detected object range 41";
BA_ "GenSigSendType" SG_ 328 CAN_DET_RANGE_41 1;
BA_ "GenSigCmt" SG_ 328 CAN_DET_RANGE_RATE_41 "Detected object range rate 41";
BA_ "GenSigSendType" SG_ 328 CAN_DET_RANGE_RATE_41 1;
BA_ "GenSigStartValue" SG_ 328 CAN_DET_RANGE_RATE_41 8192;
BA_ "GenSigCmt" SG_ 328 CAN_DET_AMPLITUDE_41 "Detected object amplitude 41";
BA_ "GenSigSendType" SG_ 328 CAN_DET_AMPLITUDE_41 1;
BA_ "GenSigCmt" SG_ 328 CAN_SCAN_INDEX_2LSB_41 "The two LSB of scan index 41";
BA_ "GenSigSendType" SG_ 328 CAN_SCAN_INDEX_2LSB_41 1;
BA_ "GenSigCmt" SG_ 327 CAN_SNR_LEVEL_40 "Signal to noise level 40";
BA_ "GenSigSendType" SG_ 327 CAN_SNR_LEVEL_40 1;
BA_ "GenSigVtName" SG_ 327 CAN_SNR_LEVEL_40 "VtSig_CAN_SNR_LEVEL_40";
BA_ "GenSigVtEn" SG_ 327 CAN_SNR_LEVEL_40 "TRUE";
BA_ "GenSigCmt" SG_ 327 CAN_DET_SUPER_RES_TARGET_40 "Super resolution target 40";
BA_ "GenSigSendType" SG_ 327 CAN_DET_SUPER_RES_TARGET_40 1;
BA_ "GenSigCmt" SG_ 327 CAN_DET_ND_TARGET_40 "Near discrimination target 40";
BA_ "GenSigSendType" SG_ 327 CAN_DET_ND_TARGET_40 1;
BA_ "GenSigCmt" SG_ 327 CAN_DET_HOST_VEH_CLUTTER_40 "Host vehicle clutter 40";
BA_ "GenSigSendType" SG_ 327 CAN_DET_HOST_VEH_CLUTTER_40 1;
BA_ "GenSigCmt" SG_ 327 CAN_DET_VALID_LEVEL_40 "Detected object valid level 40";
BA_ "GenSigSendType" SG_ 327 CAN_DET_VALID_LEVEL_40 1;
BA_ "GenSigCmt" SG_ 327 CAN_DET_AZIMUTH_40 "Detected object azimuth position 40";
BA_ "GenSigSendType" SG_ 327 CAN_DET_AZIMUTH_40 1;
BA_ "GenSigStartValue" SG_ 327 CAN_DET_AZIMUTH_40 8194;
BA_ "GenSigCmt" SG_ 327 CAN_DET_RANGE_40 "Detected object range 40";
BA_ "GenSigSendType" SG_ 327 CAN_DET_RANGE_40 1;
BA_ "GenSigCmt" SG_ 327 CAN_DET_RANGE_RATE_40 "Detected object range rate 40";
BA_ "GenSigSendType" SG_ 327 CAN_DET_RANGE_RATE_40 1;
BA_ "GenSigStartValue" SG_ 327 CAN_DET_RANGE_RATE_40 8192;
BA_ "GenSigCmt" SG_ 327 CAN_DET_AMPLITUDE_40 "Detected object amplitude 40";
BA_ "GenSigSendType" SG_ 327 CAN_DET_AMPLITUDE_40 1;
BA_ "GenSigCmt" SG_ 327 CAN_SCAN_INDEX_2LSB_40 "The two LSB of scan index 40";
BA_ "GenSigSendType" SG_ 327 CAN_SCAN_INDEX_2LSB_40 1;
BA_ "GenSigCmt" SG_ 325 CAN_SNR_LEVEL_38 "Signal to noise level 38";
BA_ "GenSigSendType" SG_ 325 CAN_SNR_LEVEL_38 1;
BA_ "GenSigVtName" SG_ 325 CAN_SNR_LEVEL_38 "VtSig_CAN_SNR_LEVEL_38";
BA_ "GenSigVtEn" SG_ 325 CAN_SNR_LEVEL_38 "TRUE";
BA_ "GenSigCmt" SG_ 325 CAN_DET_SUPER_RES_TARGET_38 "Super resolution target 38";
BA_ "GenSigSendType" SG_ 325 CAN_DET_SUPER_RES_TARGET_38 1;
BA_ "GenSigCmt" SG_ 325 CAN_DET_ND_TARGET_38 "Near discrimination target 38";
BA_ "GenSigSendType" SG_ 325 CAN_DET_ND_TARGET_38 1;
BA_ "GenSigCmt" SG_ 325 CAN_DET_HOST_VEH_CLUTTER_38 "Host vehicle clutter 38";
BA_ "GenSigSendType" SG_ 325 CAN_DET_HOST_VEH_CLUTTER_38 1;
BA_ "GenSigCmt" SG_ 325 CAN_DET_VALID_LEVEL_38 "Detected object valid level 38";
BA_ "GenSigSendType" SG_ 325 CAN_DET_VALID_LEVEL_38 1;
BA_ "GenSigCmt" SG_ 325 CAN_DET_AZIMUTH_38 "Detected object azimuth position 38";
BA_ "GenSigSendType" SG_ 325 CAN_DET_AZIMUTH_38 1;
BA_ "GenSigStartValue" SG_ 325 CAN_DET_AZIMUTH_38 8194;
BA_ "GenSigCmt" SG_ 325 CAN_DET_RANGE_38 "Detected object range 38";
BA_ "GenSigSendType" SG_ 325 CAN_DET_RANGE_38 1;
BA_ "GenSigCmt" SG_ 325 CAN_DET_RANGE_RATE_38 "Detected object range rate 38";
BA_ "GenSigSendType" SG_ 325 CAN_DET_RANGE_RATE_38 1;
BA_ "GenSigStartValue" SG_ 325 CAN_DET_RANGE_RATE_38 8192;
BA_ "GenSigCmt" SG_ 325 CAN_DET_AMPLITUDE_38 "Detected object amplitude 38";
BA_ "GenSigSendType" SG_ 325 CAN_DET_AMPLITUDE_38 1;
BA_ "GenSigCmt" SG_ 325 CAN_SCAN_INDEX_2LSB_38 "The two LSB of scan index 38";
BA_ "GenSigSendType" SG_ 325 CAN_SCAN_INDEX_2LSB_38 1;
BA_ "GenSigCmt" SG_ 324 CAN_SNR_LEVEL_37 "Signal to noise level 37";
BA_ "GenSigSendType" SG_ 324 CAN_SNR_LEVEL_37 1;
BA_ "GenSigVtName" SG_ 324 CAN_SNR_LEVEL_37 "VtSig_CAN_SNR_LEVEL_37";
BA_ "GenSigVtEn" SG_ 324 CAN_SNR_LEVEL_37 "TRUE";
BA_ "GenSigCmt" SG_ 324 CAN_DET_SUPER_RES_TARGET_37 "Super resolution target 37";
BA_ "GenSigSendType" SG_ 324 CAN_DET_SUPER_RES_TARGET_37 1;
BA_ "GenSigCmt" SG_ 324 CAN_DET_ND_TARGET_37 "Near discrimination target 37";
BA_ "GenSigSendType" SG_ 324 CAN_DET_ND_TARGET_37 1;
BA_ "GenSigCmt" SG_ 324 CAN_DET_HOST_VEH_CLUTTER_37 "Host vehicle clutter 37";
BA_ "GenSigSendType" SG_ 324 CAN_DET_HOST_VEH_CLUTTER_37 1;
BA_ "GenSigCmt" SG_ 324 CAN_DET_VALID_LEVEL_37 "Detected object valid level 37";
BA_ "GenSigSendType" SG_ 324 CAN_DET_VALID_LEVEL_37 1;
BA_ "GenSigCmt" SG_ 324 CAN_DET_AZIMUTH_37 "Detected object azimuth position 37";
BA_ "GenSigSendType" SG_ 324 CAN_DET_AZIMUTH_37 1;
BA_ "GenSigStartValue" SG_ 324 CAN_DET_AZIMUTH_37 8194;
BA_ "GenSigCmt" SG_ 324 CAN_DET_RANGE_37 "Detected object range 37";
BA_ "GenSigSendType" SG_ 324 CAN_DET_RANGE_37 1;
BA_ "GenSigCmt" SG_ 324 CAN_DET_RANGE_RATE_37 "Detected object range rate 37";
BA_ "GenSigSendType" SG_ 324 CAN_DET_RANGE_RATE_37 1;
BA_ "GenSigStartValue" SG_ 324 CAN_DET_RANGE_RATE_37 8192;
BA_ "GenSigCmt" SG_ 324 CAN_DET_AMPLITUDE_37 "Detected object amplitude 37";
BA_ "GenSigSendType" SG_ 324 CAN_DET_AMPLITUDE_37 1;
BA_ "GenSigCmt" SG_ 324 CAN_SCAN_INDEX_2LSB_37 "The two LSB of scan index 37";
BA_ "GenSigSendType" SG_ 324 CAN_SCAN_INDEX_2LSB_37 1;
BA_ "GenSigCmt" SG_ 323 CAN_SNR_LEVEL_36 "Signal to noise level 36";
BA_ "GenSigSendType" SG_ 323 CAN_SNR_LEVEL_36 1;
BA_ "GenSigVtName" SG_ 323 CAN_SNR_LEVEL_36 "VtSig_CAN_SNR_LEVEL_36";
BA_ "GenSigVtEn" SG_ 323 CAN_SNR_LEVEL_36 "TRUE";
BA_ "GenSigCmt" SG_ 323 CAN_DET_SUPER_RES_TARGET_36 "Super resolution target 36";
BA_ "GenSigSendType" SG_ 323 CAN_DET_SUPER_RES_TARGET_36 1;
BA_ "GenSigCmt" SG_ 323 CAN_DET_ND_TARGET_36 "Near discrimination target 36";
BA_ "GenSigSendType" SG_ 323 CAN_DET_ND_TARGET_36 1;
BA_ "GenSigCmt" SG_ 323 CAN_DET_HOST_VEH_CLUTTER_36 "Host vehicle clutter 36";
BA_ "GenSigSendType" SG_ 323 CAN_DET_HOST_VEH_CLUTTER_36 1;
BA_ "GenSigCmt" SG_ 323 CAN_DET_VALID_LEVEL_36 "Detected object valid level 36";
BA_ "GenSigSendType" SG_ 323 CAN_DET_VALID_LEVEL_36 1;
BA_ "GenSigCmt" SG_ 323 CAN_DET_AZIMUTH_36 "Detected object azimuth position 36";
BA_ "GenSigSendType" SG_ 323 CAN_DET_AZIMUTH_36 1;
BA_ "GenSigStartValue" SG_ 323 CAN_DET_AZIMUTH_36 8194;
BA_ "GenSigCmt" SG_ 323 CAN_DET_RANGE_36 "Detected object range 36";
BA_ "GenSigSendType" SG_ 323 CAN_DET_RANGE_36 1;
BA_ "GenSigCmt" SG_ 323 CAN_DET_RANGE_RATE_36 "Detected object range rate 36";
BA_ "GenSigSendType" SG_ 323 CAN_DET_RANGE_RATE_36 1;
BA_ "GenSigStartValue" SG_ 323 CAN_DET_RANGE_RATE_36 8192;
BA_ "GenSigCmt" SG_ 323 CAN_DET_AMPLITUDE_36 "Detected object amplitude 36";
BA_ "GenSigSendType" SG_ 323 CAN_DET_AMPLITUDE_36 1;
BA_ "GenSigCmt" SG_ 323 CAN_SCAN_INDEX_2LSB_36 "The two LSB of scan index 36";
BA_ "GenSigSendType" SG_ 323 CAN_SCAN_INDEX_2LSB_36 1;
BA_ "GenSigCmt" SG_ 322 CAN_SNR_LEVEL_35 "Signal to noise level 35";
BA_ "GenSigSendType" SG_ 322 CAN_SNR_LEVEL_35 1;
BA_ "GenSigVtName" SG_ 322 CAN_SNR_LEVEL_35 "VtSig_CAN_SNR_LEVEL_35";
BA_ "GenSigVtEn" SG_ 322 CAN_SNR_LEVEL_35 "TRUE";
BA_ "GenSigCmt" SG_ 322 CAN_DET_SUPER_RES_TARGET_35 "Super resolution target 35";
BA_ "GenSigSendType" SG_ 322 CAN_DET_SUPER_RES_TARGET_35 1;
BA_ "GenSigCmt" SG_ 322 CAN_DET_ND_TARGET_35 "Near discrimination target 35";
BA_ "GenSigSendType" SG_ 322 CAN_DET_ND_TARGET_35 1;
BA_ "GenSigCmt" SG_ 322 CAN_DET_HOST_VEH_CLUTTER_35 "Host vehicle clutter 35";
BA_ "GenSigSendType" SG_ 322 CAN_DET_HOST_VEH_CLUTTER_35 1;
BA_ "GenSigCmt" SG_ 322 CAN_DET_VALID_LEVEL_35 "Detected object valid level 35";
BA_ "GenSigSendType" SG_ 322 CAN_DET_VALID_LEVEL_35 1;
BA_ "GenSigCmt" SG_ 322 CAN_DET_AZIMUTH_35 "Detected object azimuth position 35";
BA_ "GenSigSendType" SG_ 322 CAN_DET_AZIMUTH_35 1;
BA_ "GenSigStartValue" SG_ 322 CAN_DET_AZIMUTH_35 8194;
BA_ "GenSigCmt" SG_ 322 CAN_DET_RANGE_35 "Detected object range 35";
BA_ "GenSigSendType" SG_ 322 CAN_DET_RANGE_35 1;
BA_ "GenSigCmt" SG_ 322 CAN_DET_RANGE_RATE_35 "Detected object range rate 35";
BA_ "GenSigSendType" SG_ 322 CAN_DET_RANGE_RATE_35 1;
BA_ "GenSigStartValue" SG_ 322 CAN_DET_RANGE_RATE_35 8192;
BA_ "GenSigCmt" SG_ 322 CAN_DET_AMPLITUDE_35 "Detected object amplitude 35";
BA_ "GenSigSendType" SG_ 322 CAN_DET_AMPLITUDE_35 1;
BA_ "GenSigCmt" SG_ 322 CAN_SCAN_INDEX_2LSB_35 "The two LSB of scan index 35";
BA_ "GenSigSendType" SG_ 322 CAN_SCAN_INDEX_2LSB_35 1;
BA_ "GenSigCmt" SG_ 321 CAN_SNR_LEVEL_34 "Signal to noise level 34";
BA_ "GenSigSendType" SG_ 321 CAN_SNR_LEVEL_34 1;
BA_ "GenSigVtName" SG_ 321 CAN_SNR_LEVEL_34 "VtSig_CAN_SNR_LEVEL_34";
BA_ "GenSigVtEn" SG_ 321 CAN_SNR_LEVEL_34 "TRUE";
BA_ "GenSigCmt" SG_ 321 CAN_DET_SUPER_RES_TARGET_34 "Super resolution target 34";
BA_ "GenSigSendType" SG_ 321 CAN_DET_SUPER_RES_TARGET_34 1;
BA_ "GenSigCmt" SG_ 321 CAN_DET_ND_TARGET_34 "Near discrimination target 34";
BA_ "GenSigSendType" SG_ 321 CAN_DET_ND_TARGET_34 1;
BA_ "GenSigCmt" SG_ 321 CAN_DET_HOST_VEH_CLUTTER_34 "Host vehicle clutter 34";
BA_ "GenSigSendType" SG_ 321 CAN_DET_HOST_VEH_CLUTTER_34 1;
BA_ "GenSigCmt" SG_ 321 CAN_DET_VALID_LEVEL_34 "Detected object valid level 34";
BA_ "GenSigSendType" SG_ 321 CAN_DET_VALID_LEVEL_34 1;
BA_ "GenSigCmt" SG_ 321 CAN_DET_AZIMUTH_34 "Detected object azimuth position 34";
BA_ "GenSigSendType" SG_ 321 CAN_DET_AZIMUTH_34 1;
BA_ "GenSigStartValue" SG_ 321 CAN_DET_AZIMUTH_34 8194;
BA_ "GenSigCmt" SG_ 321 CAN_DET_RANGE_34 "Detected object range 34";
BA_ "GenSigSendType" SG_ 321 CAN_DET_RANGE_34 1;
BA_ "GenSigCmt" SG_ 321 CAN_DET_RANGE_RATE_34 "Detected object range rate 34";
BA_ "GenSigSendType" SG_ 321 CAN_DET_RANGE_RATE_34 1;
BA_ "GenSigStartValue" SG_ 321 CAN_DET_RANGE_RATE_34 8192;
BA_ "GenSigCmt" SG_ 321 CAN_DET_AMPLITUDE_34 "Detected object amplitude 34";
BA_ "GenSigSendType" SG_ 321 CAN_DET_AMPLITUDE_34 1;
BA_ "GenSigCmt" SG_ 321 CAN_SCAN_INDEX_2LSB_34 "The two LSB of scan index 34";
BA_ "GenSigSendType" SG_ 321 CAN_SCAN_INDEX_2LSB_34 1;
BA_ "GenSigCmt" SG_ 320 CAN_SNR_LEVEL_33 "Signal to noise level 33";
BA_ "GenSigSendType" SG_ 320 CAN_SNR_LEVEL_33 1;
BA_ "GenSigVtName" SG_ 320 CAN_SNR_LEVEL_33 "VtSig_CAN_SNR_LEVEL_33";
BA_ "GenSigVtEn" SG_ 320 CAN_SNR_LEVEL_33 "TRUE";
BA_ "GenSigCmt" SG_ 320 CAN_DET_SUPER_RES_TARGET_33 "Super resolution target 33";
BA_ "GenSigSendType" SG_ 320 CAN_DET_SUPER_RES_TARGET_33 1;
BA_ "GenSigCmt" SG_ 320 CAN_DET_ND_TARGET_33 "Near discrimination target 33";
BA_ "GenSigSendType" SG_ 320 CAN_DET_ND_TARGET_33 1;
BA_ "GenSigCmt" SG_ 320 CAN_DET_HOST_VEH_CLUTTER_33 "Host vehicle clutter 33";
BA_ "GenSigSendType" SG_ 320 CAN_DET_HOST_VEH_CLUTTER_33 1;
BA_ "GenSigCmt" SG_ 320 CAN_DET_VALID_LEVEL_33 "Detected object valid level 33";
BA_ "GenSigSendType" SG_ 320 CAN_DET_VALID_LEVEL_33 1;
BA_ "GenSigCmt" SG_ 320 CAN_DET_AZIMUTH_33 "Detected object azimuth position 33";
BA_ "GenSigSendType" SG_ 320 CAN_DET_AZIMUTH_33 1;
BA_ "GenSigStartValue" SG_ 320 CAN_DET_AZIMUTH_33 8194;
BA_ "GenSigCmt" SG_ 320 CAN_DET_RANGE_33 "Detected object range 33";
BA_ "GenSigSendType" SG_ 320 CAN_DET_RANGE_33 1;
BA_ "GenSigCmt" SG_ 320 CAN_DET_RANGE_RATE_33 "Detected object range rate 33";
BA_ "GenSigSendType" SG_ 320 CAN_DET_RANGE_RATE_33 1;
BA_ "GenSigStartValue" SG_ 320 CAN_DET_RANGE_RATE_33 8192;
BA_ "GenSigCmt" SG_ 320 CAN_DET_AMPLITUDE_33 "Detected object amplitude 33";
BA_ "GenSigSendType" SG_ 320 CAN_DET_AMPLITUDE_33 1;
BA_ "GenSigCmt" SG_ 320 CAN_SCAN_INDEX_2LSB_33 "The two LSB of scan index 33";
BA_ "GenSigSendType" SG_ 320 CAN_SCAN_INDEX_2LSB_33 1;
BA_ "GenSigCmt" SG_ 319 CAN_SNR_LEVEL_32 "Signal to noise level 32";
BA_ "GenSigSendType" SG_ 319 CAN_SNR_LEVEL_32 1;
BA_ "GenSigVtName" SG_ 319 CAN_SNR_LEVEL_32 "VtSig_CAN_SNR_LEVEL_32";
BA_ "GenSigVtEn" SG_ 319 CAN_SNR_LEVEL_32 "TRUE";
BA_ "GenSigCmt" SG_ 319 CAN_DET_SUPER_RES_TARGET_32 "Super resolution target 32";
BA_ "GenSigSendType" SG_ 319 CAN_DET_SUPER_RES_TARGET_32 1;
BA_ "GenSigCmt" SG_ 319 CAN_DET_ND_TARGET_32 "Near discrimination target 32";
BA_ "GenSigSendType" SG_ 319 CAN_DET_ND_TARGET_32 1;
BA_ "GenSigCmt" SG_ 319 CAN_DET_HOST_VEH_CLUTTER_32 "Host vehicle clutter 32";
BA_ "GenSigSendType" SG_ 319 CAN_DET_HOST_VEH_CLUTTER_32 1;
BA_ "GenSigCmt" SG_ 319 CAN_DET_VALID_LEVEL_32 "Detected object valid level 32";
BA_ "GenSigSendType" SG_ 319 CAN_DET_VALID_LEVEL_32 1;
BA_ "GenSigCmt" SG_ 319 CAN_DET_AZIMUTH_32 "Detected object azimuth position 32";
BA_ "GenSigSendType" SG_ 319 CAN_DET_AZIMUTH_32 1;
BA_ "GenSigStartValue" SG_ 319 CAN_DET_AZIMUTH_32 8194;
BA_ "GenSigCmt" SG_ 319 CAN_DET_RANGE_32 "Detected object range 32";
BA_ "GenSigSendType" SG_ 319 CAN_DET_RANGE_32 1;
BA_ "GenSigCmt" SG_ 319 CAN_DET_RANGE_RATE_32 "Detected object range rate 32";
BA_ "GenSigSendType" SG_ 319 CAN_DET_RANGE_RATE_32 1;
BA_ "GenSigStartValue" SG_ 319 CAN_DET_RANGE_RATE_32 8192;
BA_ "GenSigCmt" SG_ 319 CAN_DET_AMPLITUDE_32 "Detected object amplitude 32";
BA_ "GenSigSendType" SG_ 319 CAN_DET_AMPLITUDE_32 1;
BA_ "GenSigCmt" SG_ 319 CAN_SCAN_INDEX_2LSB_32 "The two LSB of scan index 32";
BA_ "GenSigSendType" SG_ 319 CAN_SCAN_INDEX_2LSB_32 1;
BA_ "GenSigCmt" SG_ 318 CAN_SNR_LEVEL_31 "Signal to noise level 31";
BA_ "GenSigSendType" SG_ 318 CAN_SNR_LEVEL_31 1;
BA_ "GenSigVtName" SG_ 318 CAN_SNR_LEVEL_31 "VtSig_CAN_SNR_LEVEL_31";
BA_ "GenSigVtEn" SG_ 318 CAN_SNR_LEVEL_31 "TRUE";
BA_ "GenSigCmt" SG_ 318 CAN_DET_SUPER_RES_TARGET_31 "Super resolution target 31";
BA_ "GenSigSendType" SG_ 318 CAN_DET_SUPER_RES_TARGET_31 1;
BA_ "GenSigCmt" SG_ 318 CAN_DET_ND_TARGET_31 "Near discrimination target 31";
BA_ "GenSigSendType" SG_ 318 CAN_DET_ND_TARGET_31 1;
BA_ "GenSigCmt" SG_ 318 CAN_DET_HOST_VEH_CLUTTER_31 "Host vehicle clutter 31";
BA_ "GenSigSendType" SG_ 318 CAN_DET_HOST_VEH_CLUTTER_31 1;
BA_ "GenSigCmt" SG_ 318 CAN_DET_VALID_LEVEL_31 "Detected object valid level 31";
BA_ "GenSigSendType" SG_ 318 CAN_DET_VALID_LEVEL_31 1;
BA_ "GenSigCmt" SG_ 318 CAN_DET_AZIMUTH_31 "Detected object azimuth position 31";
BA_ "GenSigSendType" SG_ 318 CAN_DET_AZIMUTH_31 1;
BA_ "GenSigStartValue" SG_ 318 CAN_DET_AZIMUTH_31 8194;
BA_ "GenSigCmt" SG_ 318 CAN_DET_RANGE_31 "Detected object range 31";
BA_ "GenSigSendType" SG_ 318 CAN_DET_RANGE_31 1;
BA_ "GenSigCmt" SG_ 318 CAN_DET_RANGE_RATE_31 "Detected object range rate 31";
BA_ "GenSigSendType" SG_ 318 CAN_DET_RANGE_RATE_31 1;
BA_ "GenSigStartValue" SG_ 318 CAN_DET_RANGE_RATE_31 8192;
BA_ "GenSigCmt" SG_ 318 CAN_DET_AMPLITUDE_31 "Detected object amplitude 31";
BA_ "GenSigSendType" SG_ 318 CAN_DET_AMPLITUDE_31 1;
BA_ "GenSigCmt" SG_ 318 CAN_SCAN_INDEX_2LSB_31 "The two LSB of scan index 31";
BA_ "GenSigSendType" SG_ 318 CAN_SCAN_INDEX_2LSB_31 1;
BA_ "GenSigCmt" SG_ 317 CAN_SNR_LEVEL_30 "Signal to noise level 30";
BA_ "GenSigSendType" SG_ 317 CAN_SNR_LEVEL_30 1;
BA_ "GenSigVtName" SG_ 317 CAN_SNR_LEVEL_30 "VtSig_CAN_SNR_LEVEL_30";
BA_ "GenSigVtEn" SG_ 317 CAN_SNR_LEVEL_30 "TRUE";
BA_ "GenSigCmt" SG_ 317 CAN_DET_SUPER_RES_TARGET_30 "Super resolution target 30";
BA_ "GenSigSendType" SG_ 317 CAN_DET_SUPER_RES_TARGET_30 1;
BA_ "GenSigCmt" SG_ 317 CAN_DET_ND_TARGET_30 "Near discrimination target 30";
BA_ "GenSigSendType" SG_ 317 CAN_DET_ND_TARGET_30 1;
BA_ "GenSigCmt" SG_ 317 CAN_DET_HOST_VEH_CLUTTER_30 "Host vehicle clutter 30";
BA_ "GenSigSendType" SG_ 317 CAN_DET_HOST_VEH_CLUTTER_30 1;
BA_ "GenSigCmt" SG_ 317 CAN_DET_VALID_LEVEL_30 "Detected object valid level 30";
BA_ "GenSigSendType" SG_ 317 CAN_DET_VALID_LEVEL_30 1;
BA_ "GenSigCmt" SG_ 317 CAN_DET_AZIMUTH_30 "Detected object azimuth position 30";
BA_ "GenSigSendType" SG_ 317 CAN_DET_AZIMUTH_30 1;
BA_ "GenSigStartValue" SG_ 317 CAN_DET_AZIMUTH_30 8194;
BA_ "GenSigCmt" SG_ 317 CAN_DET_RANGE_30 "Detected object range 30";
BA_ "GenSigSendType" SG_ 317 CAN_DET_RANGE_30 1;
BA_ "GenSigCmt" SG_ 317 CAN_DET_RANGE_RATE_30 "Detected object range rate 30";
BA_ "GenSigSendType" SG_ 317 CAN_DET_RANGE_RATE_30 1;
BA_ "GenSigStartValue" SG_ 317 CAN_DET_RANGE_RATE_30 8192;
BA_ "GenSigCmt" SG_ 317 CAN_DET_AMPLITUDE_30 "Detected object amplitude 30";
BA_ "GenSigSendType" SG_ 317 CAN_DET_AMPLITUDE_30 1;
BA_ "GenSigCmt" SG_ 317 CAN_SCAN_INDEX_2LSB_30 "The two LSB of scan index 30";
BA_ "GenSigSendType" SG_ 317 CAN_SCAN_INDEX_2LSB_30 1;
BA_ "GenSigCmt" SG_ 316 CAN_SNR_LEVEL_29 "Signal to noise level 29";
BA_ "GenSigSendType" SG_ 316 CAN_SNR_LEVEL_29 1;
BA_ "GenSigVtName" SG_ 316 CAN_SNR_LEVEL_29 "VtSig_CAN_SNR_LEVEL_29";
BA_ "GenSigVtEn" SG_ 316 CAN_SNR_LEVEL_29 "TRUE";
BA_ "GenSigCmt" SG_ 316 CAN_DET_SUPER_RES_TARGET_29 "Super resolution target 29";
BA_ "GenSigSendType" SG_ 316 CAN_DET_SUPER_RES_TARGET_29 1;
BA_ "GenSigCmt" SG_ 316 CAN_DET_ND_TARGET_29 "Near discrimination target 29";
BA_ "GenSigSendType" SG_ 316 CAN_DET_ND_TARGET_29 1;
BA_ "GenSigCmt" SG_ 316 CAN_DET_HOST_VEH_CLUTTER_29 "Host vehicle clutter 29";
BA_ "GenSigSendType" SG_ 316 CAN_DET_HOST_VEH_CLUTTER_29 1;
BA_ "GenSigCmt" SG_ 316 CAN_DET_VALID_LEVEL_29 "Detected object valid level 29";
BA_ "GenSigSendType" SG_ 316 CAN_DET_VALID_LEVEL_29 1;
BA_ "GenSigCmt" SG_ 316 CAN_DET_AZIMUTH_29 "Detected object azimuth position 29";
BA_ "GenSigSendType" SG_ 316 CAN_DET_AZIMUTH_29 1;
BA_ "GenSigStartValue" SG_ 316 CAN_DET_AZIMUTH_29 8194;
BA_ "GenSigCmt" SG_ 316 CAN_DET_RANGE_29 "Detected object range 29";
BA_ "GenSigSendType" SG_ 316 CAN_DET_RANGE_29 1;
BA_ "GenSigCmt" SG_ 316 CAN_DET_RANGE_RATE_29 "Detected object range rate 29";
BA_ "GenSigSendType" SG_ 316 CAN_DET_RANGE_RATE_29 1;
BA_ "GenSigStartValue" SG_ 316 CAN_DET_RANGE_RATE_29 8192;
BA_ "GenSigCmt" SG_ 316 CAN_DET_AMPLITUDE_29 "Detected object amplitude 29";
BA_ "GenSigSendType" SG_ 316 CAN_DET_AMPLITUDE_29 1;
BA_ "GenSigCmt" SG_ 316 CAN_SCAN_INDEX_2LSB_29 "The two LSB of scan index 29";
BA_ "GenSigSendType" SG_ 316 CAN_SCAN_INDEX_2LSB_29 1;
BA_ "GenSigCmt" SG_ 314 CAN_SNR_LEVEL_27 "Signal to noise level 27";
BA_ "GenSigSendType" SG_ 314 CAN_SNR_LEVEL_27 1;
BA_ "GenSigVtName" SG_ 314 CAN_SNR_LEVEL_27 "VtSig_CAN_SNR_LEVEL_27";
BA_ "GenSigVtEn" SG_ 314 CAN_SNR_LEVEL_27 "TRUE";
BA_ "GenSigCmt" SG_ 314 CAN_DET_SUPER_RES_TARGET_27 "Super resolution target 27";
BA_ "GenSigSendType" SG_ 314 CAN_DET_SUPER_RES_TARGET_27 1;
BA_ "GenSigCmt" SG_ 314 CAN_DET_ND_TARGET_27 "Near discrimination target 27";
BA_ "GenSigSendType" SG_ 314 CAN_DET_ND_TARGET_27 1;
BA_ "GenSigCmt" SG_ 314 CAN_DET_HOST_VEH_CLUTTER_27 "Host vehicle clutter 27";
BA_ "GenSigSendType" SG_ 314 CAN_DET_HOST_VEH_CLUTTER_27 1;
BA_ "GenSigCmt" SG_ 314 CAN_DET_VALID_LEVEL_27 "Detected object valid level 27";
BA_ "GenSigSendType" SG_ 314 CAN_DET_VALID_LEVEL_27 1;
BA_ "GenSigCmt" SG_ 314 CAN_DET_AZIMUTH_27 "Detected object azimuth position 27";
BA_ "GenSigSendType" SG_ 314 CAN_DET_AZIMUTH_27 1;
BA_ "GenSigStartValue" SG_ 314 CAN_DET_AZIMUTH_27 8194;
BA_ "GenSigCmt" SG_ 314 CAN_DET_RANGE_27 "Detected object range 27";
BA_ "GenSigSendType" SG_ 314 CAN_DET_RANGE_27 1;
BA_ "GenSigCmt" SG_ 314 CAN_DET_RANGE_RATE_27 "Detected object range rate 27";
BA_ "GenSigSendType" SG_ 314 CAN_DET_RANGE_RATE_27 1;
BA_ "GenSigStartValue" SG_ 314 CAN_DET_RANGE_RATE_27 8192;
BA_ "GenSigCmt" SG_ 314 CAN_DET_AMPLITUDE_27 "Detected object amplitude 27";
BA_ "GenSigSendType" SG_ 314 CAN_DET_AMPLITUDE_27 1;
BA_ "GenSigCmt" SG_ 314 CAN_SCAN_INDEX_2LSB_27 "The two LSB of scan index 27";
BA_ "GenSigSendType" SG_ 314 CAN_SCAN_INDEX_2LSB_27 1;
BA_ "GenSigCmt" SG_ 313 CAN_SNR_LEVEL_26 "Signal to noise level 26";
BA_ "GenSigSendType" SG_ 313 CAN_SNR_LEVEL_26 1;
BA_ "GenSigVtName" SG_ 313 CAN_SNR_LEVEL_26 "VtSig_CAN_SNR_LEVEL_26";
BA_ "GenSigVtEn" SG_ 313 CAN_SNR_LEVEL_26 "TRUE";
BA_ "GenSigCmt" SG_ 313 CAN_DET_SUPER_RES_TARGET_26 "Super resolution target 26";
BA_ "GenSigSendType" SG_ 313 CAN_DET_SUPER_RES_TARGET_26 1;
BA_ "GenSigCmt" SG_ 313 CAN_DET_ND_TARGET_26 "Near discrimination target 26";
BA_ "GenSigSendType" SG_ 313 CAN_DET_ND_TARGET_26 1;
BA_ "GenSigCmt" SG_ 313 CAN_DET_HOST_VEH_CLUTTER_26 "Host vehicle clutter 26";
BA_ "GenSigSendType" SG_ 313 CAN_DET_HOST_VEH_CLUTTER_26 1;
BA_ "GenSigCmt" SG_ 313 CAN_DET_VALID_LEVEL_26 "Detected object valid level 26";
BA_ "GenSigSendType" SG_ 313 CAN_DET_VALID_LEVEL_26 1;
BA_ "GenSigCmt" SG_ 313 CAN_DET_AZIMUTH_26 "Detected object azimuth position 26";
BA_ "GenSigSendType" SG_ 313 CAN_DET_AZIMUTH_26 1;
BA_ "GenSigStartValue" SG_ 313 CAN_DET_AZIMUTH_26 8194;
BA_ "GenSigCmt" SG_ 313 CAN_DET_RANGE_26 "Detected object range 26";
BA_ "GenSigSendType" SG_ 313 CAN_DET_RANGE_26 1;
BA_ "GenSigCmt" SG_ 313 CAN_DET_RANGE_RATE_26 "Detected object range rate 26";
BA_ "GenSigSendType" SG_ 313 CAN_DET_RANGE_RATE_26 1;
BA_ "GenSigStartValue" SG_ 313 CAN_DET_RANGE_RATE_26 8192;
BA_ "GenSigCmt" SG_ 313 CAN_DET_AMPLITUDE_26 "Detected object amplitude 26";
BA_ "GenSigSendType" SG_ 313 CAN_DET_AMPLITUDE_26 1;
BA_ "GenSigCmt" SG_ 313 CAN_SCAN_INDEX_2LSB_26 "The two LSB of scan index 26";
BA_ "GenSigSendType" SG_ 313 CAN_SCAN_INDEX_2LSB_26 1;
BA_ "GenSigCmt" SG_ 312 CAN_SNR_LEVEL_25 "Signal to noise level 25";
BA_ "GenSigSendType" SG_ 312 CAN_SNR_LEVEL_25 1;
BA_ "GenSigVtName" SG_ 312 CAN_SNR_LEVEL_25 "VtSig_CAN_SNR_LEVEL_25";
BA_ "GenSigVtEn" SG_ 312 CAN_SNR_LEVEL_25 "TRUE";
BA_ "GenSigCmt" SG_ 312 CAN_DET_SUPER_RES_TARGET_25 "Super resolution target 25";
BA_ "GenSigSendType" SG_ 312 CAN_DET_SUPER_RES_TARGET_25 1;
BA_ "GenSigCmt" SG_ 312 CAN_DET_ND_TARGET_25 "Near discrimination target 25";
BA_ "GenSigSendType" SG_ 312 CAN_DET_ND_TARGET_25 1;
BA_ "GenSigCmt" SG_ 312 CAN_DET_HOST_VEH_CLUTTER_25 "Host vehicle clutter 25";
BA_ "GenSigSendType" SG_ 312 CAN_DET_HOST_VEH_CLUTTER_25 1;
BA_ "GenSigCmt" SG_ 312 CAN_DET_VALID_LEVEL_25 "Detected object valid level 25";
BA_ "GenSigSendType" SG_ 312 CAN_DET_VALID_LEVEL_25 1;
BA_ "GenSigCmt" SG_ 312 CAN_DET_AZIMUTH_25 "Detected object azimuth position 25";
BA_ "GenSigSendType" SG_ 312 CAN_DET_AZIMUTH_25 1;
BA_ "GenSigStartValue" SG_ 312 CAN_DET_AZIMUTH_25 8194;
BA_ "GenSigCmt" SG_ 312 CAN_DET_RANGE_25 "Detected object range 25";
BA_ "GenSigSendType" SG_ 312 CAN_DET_RANGE_25 1;
BA_ "GenSigCmt" SG_ 312 CAN_DET_RANGE_RATE_25 "Detected object range rate 25";
BA_ "GenSigSendType" SG_ 312 CAN_DET_RANGE_RATE_25 1;
BA_ "GenSigStartValue" SG_ 312 CAN_DET_RANGE_RATE_25 8192;
BA_ "GenSigCmt" SG_ 312 CAN_DET_AMPLITUDE_25 "Detected object amplitude 25";
BA_ "GenSigSendType" SG_ 312 CAN_DET_AMPLITUDE_25 1;
BA_ "GenSigCmt" SG_ 312 CAN_SCAN_INDEX_2LSB_25 "The two LSB of scan index 25";
BA_ "GenSigSendType" SG_ 312 CAN_SCAN_INDEX_2LSB_25 1;
BA_ "GenSigCmt" SG_ 311 CAN_SNR_LEVEL_24 "Signal to noise level 24";
BA_ "GenSigSendType" SG_ 311 CAN_SNR_LEVEL_24 1;
BA_ "GenSigVtName" SG_ 311 CAN_SNR_LEVEL_24 "VtSig_CAN_SNR_LEVEL_24";
BA_ "GenSigVtEn" SG_ 311 CAN_SNR_LEVEL_24 "TRUE";
BA_ "GenSigCmt" SG_ 311 CAN_DET_SUPER_RES_TARGET_24 "Super resolution target 24";
BA_ "GenSigSendType" SG_ 311 CAN_DET_SUPER_RES_TARGET_24 1;
BA_ "GenSigCmt" SG_ 311 CAN_DET_ND_TARGET_24 "Near discrimination target 24";
BA_ "GenSigSendType" SG_ 311 CAN_DET_ND_TARGET_24 1;
BA_ "GenSigCmt" SG_ 311 CAN_DET_HOST_VEH_CLUTTER_24 "Host vehicle clutter 24";
BA_ "GenSigSendType" SG_ 311 CAN_DET_HOST_VEH_CLUTTER_24 1;
BA_ "GenSigCmt" SG_ 311 CAN_DET_VALID_LEVEL_24 "Detected object valid level 24";
BA_ "GenSigSendType" SG_ 311 CAN_DET_VALID_LEVEL_24 1;
BA_ "GenSigCmt" SG_ 311 CAN_DET_AZIMUTH_24 "Detected object azimuth position 24";
BA_ "GenSigSendType" SG_ 311 CAN_DET_AZIMUTH_24 1;
BA_ "GenSigStartValue" SG_ 311 CAN_DET_AZIMUTH_24 8194;
BA_ "GenSigCmt" SG_ 311 CAN_DET_RANGE_24 "Detected object range 24";
BA_ "GenSigSendType" SG_ 311 CAN_DET_RANGE_24 1;
BA_ "GenSigCmt" SG_ 311 CAN_DET_RANGE_RATE_24 "Detected object range rate 24";
BA_ "GenSigSendType" SG_ 311 CAN_DET_RANGE_RATE_24 1;
BA_ "GenSigStartValue" SG_ 311 CAN_DET_RANGE_RATE_24 8192;
BA_ "GenSigCmt" SG_ 311 CAN_DET_AMPLITUDE_24 "Detected object amplitude 24";
BA_ "GenSigSendType" SG_ 311 CAN_DET_AMPLITUDE_24 1;
BA_ "GenSigCmt" SG_ 311 CAN_SCAN_INDEX_2LSB_24 "The two LSB of scan index 24";
BA_ "GenSigSendType" SG_ 311 CAN_SCAN_INDEX_2LSB_24 1;
BA_ "GenSigCmt" SG_ 310 CAN_SNR_LEVEL_23 "Signal to noise level 23";
BA_ "GenSigSendType" SG_ 310 CAN_SNR_LEVEL_23 1;
BA_ "GenSigVtName" SG_ 310 CAN_SNR_LEVEL_23 "VtSig_CAN_SNR_LEVEL_23";
BA_ "GenSigVtEn" SG_ 310 CAN_SNR_LEVEL_23 "TRUE";
BA_ "GenSigCmt" SG_ 310 CAN_DET_SUPER_RES_TARGET_23 "Super resolution target 23";
BA_ "GenSigSendType" SG_ 310 CAN_DET_SUPER_RES_TARGET_23 1;
BA_ "GenSigCmt" SG_ 310 CAN_DET_ND_TARGET_23 "Near discrimination target 23";
BA_ "GenSigSendType" SG_ 310 CAN_DET_ND_TARGET_23 1;
BA_ "GenSigCmt" SG_ 310 CAN_DET_HOST_VEH_CLUTTER_23 "Host vehicle clutter 23";
BA_ "GenSigSendType" SG_ 310 CAN_DET_HOST_VEH_CLUTTER_23 1;
BA_ "GenSigCmt" SG_ 310 CAN_DET_VALID_LEVEL_23 "Detected object valid level 23";
BA_ "GenSigSendType" SG_ 310 CAN_DET_VALID_LEVEL_23 1;
BA_ "GenSigCmt" SG_ 310 CAN_DET_AZIMUTH_23 "Detected object azimuth position 23";
BA_ "GenSigSendType" SG_ 310 CAN_DET_AZIMUTH_23 1;
BA_ "GenSigStartValue" SG_ 310 CAN_DET_AZIMUTH_23 8194;
BA_ "GenSigCmt" SG_ 310 CAN_DET_RANGE_23 "Detected object range 23";
BA_ "GenSigSendType" SG_ 310 CAN_DET_RANGE_23 1;
BA_ "GenSigCmt" SG_ 310 CAN_DET_RANGE_RATE_23 "Detected object range rate 23";
BA_ "GenSigSendType" SG_ 310 CAN_DET_RANGE_RATE_23 1;
BA_ "GenSigStartValue" SG_ 310 CAN_DET_RANGE_RATE_23 8192;
BA_ "GenSigCmt" SG_ 310 CAN_DET_AMPLITUDE_23 "Detected object amplitude 23";
BA_ "GenSigSendType" SG_ 310 CAN_DET_AMPLITUDE_23 1;
BA_ "GenSigCmt" SG_ 310 CAN_SCAN_INDEX_2LSB_23 "The two LSB of scan index 23";
BA_ "GenSigSendType" SG_ 310 CAN_SCAN_INDEX_2LSB_23 1;
BA_ "GenSigCmt" SG_ 309 CAN_SNR_LEVEL_22 "Signal to noise level 22";
BA_ "GenSigSendType" SG_ 309 CAN_SNR_LEVEL_22 1;
BA_ "GenSigVtName" SG_ 309 CAN_SNR_LEVEL_22 "VtSig_CAN_SNR_LEVEL_22";
BA_ "GenSigVtEn" SG_ 309 CAN_SNR_LEVEL_22 "TRUE";
BA_ "GenSigCmt" SG_ 309 CAN_DET_SUPER_RES_TARGET_22 "Super resolution target 22";
BA_ "GenSigSendType" SG_ 309 CAN_DET_SUPER_RES_TARGET_22 1;
BA_ "GenSigCmt" SG_ 309 CAN_DET_ND_TARGET_22 "Near discrimination target 22";
BA_ "GenSigSendType" SG_ 309 CAN_DET_ND_TARGET_22 1;
BA_ "GenSigCmt" SG_ 309 CAN_DET_HOST_VEH_CLUTTER_22 "Host vehicle clutter 22";
BA_ "GenSigSendType" SG_ 309 CAN_DET_HOST_VEH_CLUTTER_22 1;
BA_ "GenSigCmt" SG_ 309 CAN_DET_VALID_LEVEL_22 "Detected object valid level 22";
BA_ "GenSigSendType" SG_ 309 CAN_DET_VALID_LEVEL_22 1;
BA_ "GenSigCmt" SG_ 309 CAN_DET_AZIMUTH_22 "Detected object azimuth position 22";
BA_ "GenSigSendType" SG_ 309 CAN_DET_AZIMUTH_22 1;
BA_ "GenSigStartValue" SG_ 309 CAN_DET_AZIMUTH_22 8194;
BA_ "GenSigCmt" SG_ 309 CAN_DET_RANGE_22 "Detected object range 22";
BA_ "GenSigSendType" SG_ 309 CAN_DET_RANGE_22 1;
BA_ "GenSigCmt" SG_ 309 CAN_DET_RANGE_RATE_22 "Detected object range rate 22";
BA_ "GenSigSendType" SG_ 309 CAN_DET_RANGE_RATE_22 1;
BA_ "GenSigStartValue" SG_ 309 CAN_DET_RANGE_RATE_22 8192;
BA_ "GenSigCmt" SG_ 309 CAN_DET_AMPLITUDE_22 "Detected object amplitude 22";
BA_ "GenSigSendType" SG_ 309 CAN_DET_AMPLITUDE_22 1;
BA_ "GenSigCmt" SG_ 309 CAN_SCAN_INDEX_2LSB_22 "The two LSB of scan index 22";
BA_ "GenSigSendType" SG_ 309 CAN_SCAN_INDEX_2LSB_22 1;
BA_ "GenSigCmt" SG_ 308 CAN_SNR_LEVEL_21 "Signal to noise level 21";
BA_ "GenSigSendType" SG_ 308 CAN_SNR_LEVEL_21 1;
BA_ "GenSigVtName" SG_ 308 CAN_SNR_LEVEL_21 "VtSig_CAN_SNR_LEVEL_21";
BA_ "GenSigVtEn" SG_ 308 CAN_SNR_LEVEL_21 "TRUE";
BA_ "GenSigCmt" SG_ 308 CAN_DET_SUPER_RES_TARGET_21 "Super resolution target 21";
BA_ "GenSigSendType" SG_ 308 CAN_DET_SUPER_RES_TARGET_21 1;
BA_ "GenSigCmt" SG_ 308 CAN_DET_ND_TARGET_21 "Near discrimination target 21";
BA_ "GenSigSendType" SG_ 308 CAN_DET_ND_TARGET_21 1;
BA_ "GenSigCmt" SG_ 308 CAN_DET_HOST_VEH_CLUTTER_21 "Host vehicle clutter 21";
BA_ "GenSigSendType" SG_ 308 CAN_DET_HOST_VEH_CLUTTER_21 1;
BA_ "GenSigCmt" SG_ 308 CAN_DET_VALID_LEVEL_21 "Detected object valid level 21";
BA_ "GenSigSendType" SG_ 308 CAN_DET_VALID_LEVEL_21 1;
BA_ "GenSigCmt" SG_ 308 CAN_DET_AZIMUTH_21 "Detected object azimuth position 21";
BA_ "GenSigSendType" SG_ 308 CAN_DET_AZIMUTH_21 1;
BA_ "GenSigStartValue" SG_ 308 CAN_DET_AZIMUTH_21 8194;
BA_ "GenSigCmt" SG_ 308 CAN_DET_RANGE_21 "Detected object range 21";
BA_ "GenSigSendType" SG_ 308 CAN_DET_RANGE_21 1;
BA_ "GenSigCmt" SG_ 308 CAN_DET_RANGE_RATE_21 "Detected object range rate 21";
BA_ "GenSigSendType" SG_ 308 CAN_DET_RANGE_RATE_21 1;
BA_ "GenSigStartValue" SG_ 308 CAN_DET_RANGE_RATE_21 8192;
BA_ "GenSigCmt" SG_ 308 CAN_DET_AMPLITUDE_21 "Detected object amplitude 21";
BA_ "GenSigSendType" SG_ 308 CAN_DET_AMPLITUDE_21 1;
BA_ "GenSigCmt" SG_ 308 CAN_SCAN_INDEX_2LSB_21 "The two LSB of scan index 21";
BA_ "GenSigSendType" SG_ 308 CAN_SCAN_INDEX_2LSB_21 1;
BA_ "GenSigCmt" SG_ 307 CAN_SNR_LEVEL_20 "Signal to noise level 20";
BA_ "GenSigSendType" SG_ 307 CAN_SNR_LEVEL_20 1;
BA_ "GenSigVtName" SG_ 307 CAN_SNR_LEVEL_20 "VtSig_CAN_SNR_LEVEL_20";
BA_ "GenSigVtEn" SG_ 307 CAN_SNR_LEVEL_20 "TRUE";
BA_ "GenSigCmt" SG_ 307 CAN_DET_SUPER_RES_TARGET_20 "Super resolution target 20";
BA_ "GenSigSendType" SG_ 307 CAN_DET_SUPER_RES_TARGET_20 1;
BA_ "GenSigCmt" SG_ 307 CAN_DET_ND_TARGET_20 "Near discrimination target 20";
BA_ "GenSigSendType" SG_ 307 CAN_DET_ND_TARGET_20 1;
BA_ "GenSigCmt" SG_ 307 CAN_DET_HOST_VEH_CLUTTER_20 "Host vehicle clutter 20";
BA_ "GenSigSendType" SG_ 307 CAN_DET_HOST_VEH_CLUTTER_20 1;
BA_ "GenSigCmt" SG_ 307 CAN_DET_VALID_LEVEL_20 "Detected object valid level 20";
BA_ "GenSigSendType" SG_ 307 CAN_DET_VALID_LEVEL_20 1;
BA_ "GenSigCmt" SG_ 307 CAN_DET_AZIMUTH_20 "Detected object azimuth position 20";
BA_ "GenSigSendType" SG_ 307 CAN_DET_AZIMUTH_20 1;
BA_ "GenSigStartValue" SG_ 307 CAN_DET_AZIMUTH_20 8194;
BA_ "GenSigCmt" SG_ 307 CAN_DET_RANGE_20 "Detected object range 20";
BA_ "GenSigSendType" SG_ 307 CAN_DET_RANGE_20 1;
BA_ "GenSigCmt" SG_ 307 CAN_DET_RANGE_RATE_20 "Detected object range rate 20";
BA_ "GenSigSendType" SG_ 307 CAN_DET_RANGE_RATE_20 1;
BA_ "GenSigStartValue" SG_ 307 CAN_DET_RANGE_RATE_20 8192;
BA_ "GenSigCmt" SG_ 307 CAN_DET_AMPLITUDE_20 "Detected object amplitude 20";
BA_ "GenSigSendType" SG_ 307 CAN_DET_AMPLITUDE_20 1;
BA_ "GenSigCmt" SG_ 307 CAN_SCAN_INDEX_2LSB_20 "The two LSB of scan index 20";
BA_ "GenSigSendType" SG_ 307 CAN_SCAN_INDEX_2LSB_20 1;
BA_ "GenSigCmt" SG_ 306 CAN_SNR_LEVEL_19 "Signal to noise level 19";
BA_ "GenSigSendType" SG_ 306 CAN_SNR_LEVEL_19 1;
BA_ "GenSigVtName" SG_ 306 CAN_SNR_LEVEL_19 "VtSig_CAN_SNR_LEVEL_19";
BA_ "GenSigVtEn" SG_ 306 CAN_SNR_LEVEL_19 "TRUE";
BA_ "GenSigCmt" SG_ 306 CAN_DET_SUPER_RES_TARGET_19 "Super resolution target 19";
BA_ "GenSigSendType" SG_ 306 CAN_DET_SUPER_RES_TARGET_19 1;
BA_ "GenSigCmt" SG_ 306 CAN_DET_ND_TARGET_19 "Near discrimination target 19";
BA_ "GenSigSendType" SG_ 306 CAN_DET_ND_TARGET_19 1;
BA_ "GenSigCmt" SG_ 306 CAN_DET_HOST_VEH_CLUTTER_19 "Host vehicle clutter 19";
BA_ "GenSigSendType" SG_ 306 CAN_DET_HOST_VEH_CLUTTER_19 1;
BA_ "GenSigCmt" SG_ 306 CAN_DET_VALID_LEVEL_19 "Detected object valid level 19";
BA_ "GenSigSendType" SG_ 306 CAN_DET_VALID_LEVEL_19 1;
BA_ "GenSigCmt" SG_ 306 CAN_DET_AZIMUTH_19 "Detected object azimuth position 19";
BA_ "GenSigSendType" SG_ 306 CAN_DET_AZIMUTH_19 1;
BA_ "GenSigStartValue" SG_ 306 CAN_DET_AZIMUTH_19 8194;
BA_ "GenSigCmt" SG_ 306 CAN_DET_RANGE_19 "Detected object range 19";
BA_ "GenSigSendType" SG_ 306 CAN_DET_RANGE_19 1;
BA_ "GenSigCmt" SG_ 306 CAN_DET_RANGE_RATE_19 "Detected object range rate 19";
BA_ "GenSigSendType" SG_ 306 CAN_DET_RANGE_RATE_19 1;
BA_ "GenSigStartValue" SG_ 306 CAN_DET_RANGE_RATE_19 8192;
BA_ "GenSigCmt" SG_ 306 CAN_DET_AMPLITUDE_19 "Detected object amplitude 19";
BA_ "GenSigSendType" SG_ 306 CAN_DET_AMPLITUDE_19 1;
BA_ "GenSigCmt" SG_ 306 CAN_SCAN_INDEX_2LSB_19 "The two LSB of scan index 19";
BA_ "GenSigSendType" SG_ 306 CAN_SCAN_INDEX_2LSB_19 1;
BA_ "GenSigCmt" SG_ 305 CAN_SNR_LEVEL_18 "Signal to noise level 18";
BA_ "GenSigSendType" SG_ 305 CAN_SNR_LEVEL_18 1;
BA_ "GenSigVtName" SG_ 305 CAN_SNR_LEVEL_18 "VtSig_CAN_SNR_LEVEL_18";
BA_ "GenSigVtEn" SG_ 305 CAN_SNR_LEVEL_18 "TRUE";
BA_ "GenSigCmt" SG_ 305 CAN_DET_SUPER_RES_TARGET_18 "Super resolution target 18";
BA_ "GenSigSendType" SG_ 305 CAN_DET_SUPER_RES_TARGET_18 1;
BA_ "GenSigCmt" SG_ 305 CAN_DET_ND_TARGET_18 "Near discrimination target 18";
BA_ "GenSigSendType" SG_ 305 CAN_DET_ND_TARGET_18 1;
BA_ "GenSigCmt" SG_ 305 CAN_DET_HOST_VEH_CLUTTER_18 "Host vehicle clutter 18";
BA_ "GenSigSendType" SG_ 305 CAN_DET_HOST_VEH_CLUTTER_18 1;
BA_ "GenSigCmt" SG_ 305 CAN_DET_VALID_LEVEL_18 "Detected object valid level 18";
BA_ "GenSigSendType" SG_ 305 CAN_DET_VALID_LEVEL_18 1;
BA_ "GenSigCmt" SG_ 305 CAN_DET_AZIMUTH_18 "Detected object azimuth position 18";
BA_ "GenSigSendType" SG_ 305 CAN_DET_AZIMUTH_18 1;
BA_ "GenSigStartValue" SG_ 305 CAN_DET_AZIMUTH_18 8194;
BA_ "GenSigCmt" SG_ 305 CAN_DET_RANGE_18 "Detected object range 18";
BA_ "GenSigSendType" SG_ 305 CAN_DET_RANGE_18 1;
BA_ "GenSigCmt" SG_ 305 CAN_DET_RANGE_RATE_18 "Detected object range rate 18";
BA_ "GenSigSendType" SG_ 305 CAN_DET_RANGE_RATE_18 1;
BA_ "GenSigStartValue" SG_ 305 CAN_DET_RANGE_RATE_18 8192;
BA_ "GenSigCmt" SG_ 305 CAN_DET_AMPLITUDE_18 "Detected object amplitude 18";
BA_ "GenSigSendType" SG_ 305 CAN_DET_AMPLITUDE_18 1;
BA_ "GenSigCmt" SG_ 305 CAN_SCAN_INDEX_2LSB_18 "The two LSB of scan index 18";
BA_ "GenSigSendType" SG_ 305 CAN_SCAN_INDEX_2LSB_18 1;
BA_ "GenSigCmt" SG_ 341 CAN_SNR_LEVEL_54 "Signal to noise level 54";
BA_ "GenSigSendType" SG_ 341 CAN_SNR_LEVEL_54 1;
BA_ "GenSigVtName" SG_ 341 CAN_SNR_LEVEL_54 "VtSig_CAN_SNR_LEVEL_54";
BA_ "GenSigVtEn" SG_ 341 CAN_SNR_LEVEL_54 "TRUE";
BA_ "GenSigCmt" SG_ 341 CAN_DET_SUPER_RES_TARGET_54 "Super resolution target 54";
BA_ "GenSigSendType" SG_ 341 CAN_DET_SUPER_RES_TARGET_54 1;
BA_ "GenSigCmt" SG_ 341 CAN_DET_ND_TARGET_54 "Near discrimination target 54";
BA_ "GenSigSendType" SG_ 341 CAN_DET_ND_TARGET_54 1;
BA_ "GenSigCmt" SG_ 341 CAN_DET_HOST_VEH_CLUTTER_54 "Host vehicle clutter 54";
BA_ "GenSigSendType" SG_ 341 CAN_DET_HOST_VEH_CLUTTER_54 1;
BA_ "GenSigCmt" SG_ 341 CAN_DET_VALID_LEVEL_54 "Detected object valid level 54";
BA_ "GenSigSendType" SG_ 341 CAN_DET_VALID_LEVEL_54 1;
BA_ "GenSigCmt" SG_ 341 CAN_DET_AZIMUTH_54 "Detected object azimuth position 54";
BA_ "GenSigSendType" SG_ 341 CAN_DET_AZIMUTH_54 1;
BA_ "GenSigStartValue" SG_ 341 CAN_DET_AZIMUTH_54 8194;
BA_ "GenSigCmt" SG_ 341 CAN_DET_RANGE_54 "Detected object range 54";
BA_ "GenSigSendType" SG_ 341 CAN_DET_RANGE_54 1;
BA_ "GenSigCmt" SG_ 341 CAN_DET_RANGE_RATE_54 "Detected object range rate 54";
BA_ "GenSigSendType" SG_ 341 CAN_DET_RANGE_RATE_54 1;
BA_ "GenSigStartValue" SG_ 341 CAN_DET_RANGE_RATE_54 8192;
BA_ "GenSigCmt" SG_ 341 CAN_DET_AMPLITUDE_54 "Detected object amplitude 54";
BA_ "GenSigSendType" SG_ 341 CAN_DET_AMPLITUDE_54 1;
BA_ "GenSigCmt" SG_ 341 CAN_SCAN_INDEX_2LSB_54 "The two LSB of scan index 54";
BA_ "GenSigSendType" SG_ 341 CAN_SCAN_INDEX_2LSB_54 1;
BA_ "GenSigCmt" SG_ 340 CAN_SNR_LEVEL_53 "Signal to noise level 53";
BA_ "GenSigSendType" SG_ 340 CAN_SNR_LEVEL_53 1;
BA_ "GenSigVtName" SG_ 340 CAN_SNR_LEVEL_53 "VtSig_CAN_SNR_LEVEL_53";
BA_ "GenSigVtEn" SG_ 340 CAN_SNR_LEVEL_53 "TRUE";
BA_ "GenSigCmt" SG_ 340 CAN_DET_SUPER_RES_TARGET_53 "Super resolution target 53";
BA_ "GenSigSendType" SG_ 340 CAN_DET_SUPER_RES_TARGET_53 1;
BA_ "GenSigCmt" SG_ 340 CAN_DET_ND_TARGET_53 "Near discrimination target 53";
BA_ "GenSigSendType" SG_ 340 CAN_DET_ND_TARGET_53 1;
BA_ "GenSigCmt" SG_ 340 CAN_DET_HOST_VEH_CLUTTER_53 "Host vehicle clutter 53";
BA_ "GenSigSendType" SG_ 340 CAN_DET_HOST_VEH_CLUTTER_53 1;
BA_ "GenSigCmt" SG_ 340 CAN_DET_VALID_LEVEL_53 "Detected object valid level 53";
BA_ "GenSigSendType" SG_ 340 CAN_DET_VALID_LEVEL_53 1;
BA_ "GenSigCmt" SG_ 340 CAN_DET_AZIMUTH_53 "Detected object azimuth position 53";
BA_ "GenSigSendType" SG_ 340 CAN_DET_AZIMUTH_53 1;
BA_ "GenSigStartValue" SG_ 340 CAN_DET_AZIMUTH_53 8194;
BA_ "GenSigCmt" SG_ 340 CAN_DET_RANGE_53 "Detected object range 53";
BA_ "GenSigSendType" SG_ 340 CAN_DET_RANGE_53 1;
BA_ "GenSigCmt" SG_ 340 CAN_DET_RANGE_RATE_53 "Detected object range rate 53";
BA_ "GenSigSendType" SG_ 340 CAN_DET_RANGE_RATE_53 1;
BA_ "GenSigStartValue" SG_ 340 CAN_DET_RANGE_RATE_53 8192;
BA_ "GenSigCmt" SG_ 340 CAN_DET_AMPLITUDE_53 "Detected object amplitude 53";
BA_ "GenSigSendType" SG_ 340 CAN_DET_AMPLITUDE_53 1;
BA_ "GenSigCmt" SG_ 340 CAN_SCAN_INDEX_2LSB_53 "The two LSB of scan index 53";
BA_ "GenSigSendType" SG_ 340 CAN_SCAN_INDEX_2LSB_53 1;
BA_ "GenSigCmt" SG_ 339 CAN_SNR_LEVEL_52 "Signal to noise level 52";
BA_ "GenSigSendType" SG_ 339 CAN_SNR_LEVEL_52 1;
BA_ "GenSigVtName" SG_ 339 CAN_SNR_LEVEL_52 "VtSig_CAN_SNR_LEVEL_52";
BA_ "GenSigVtEn" SG_ 339 CAN_SNR_LEVEL_52 "TRUE";
BA_ "GenSigCmt" SG_ 339 CAN_DET_SUPER_RES_TARGET_52 "Super resolution target 52";
BA_ "GenSigSendType" SG_ 339 CAN_DET_SUPER_RES_TARGET_52 1;
BA_ "GenSigCmt" SG_ 339 CAN_DET_ND_TARGET_52 "Near discrimination target 52";
BA_ "GenSigSendType" SG_ 339 CAN_DET_ND_TARGET_52 1;
BA_ "GenSigCmt" SG_ 339 CAN_DET_HOST_VEH_CLUTTER_52 "Host vehicle clutter 52";
BA_ "GenSigSendType" SG_ 339 CAN_DET_HOST_VEH_CLUTTER_52 1;
BA_ "GenSigCmt" SG_ 339 CAN_DET_VALID_LEVEL_52 "Detected object valid level 52";
BA_ "GenSigSendType" SG_ 339 CAN_DET_VALID_LEVEL_52 1;
BA_ "GenSigCmt" SG_ 339 CAN_DET_AZIMUTH_52 "Detected object azimuth position 52";
BA_ "GenSigSendType" SG_ 339 CAN_DET_AZIMUTH_52 1;
BA_ "GenSigStartValue" SG_ 339 CAN_DET_AZIMUTH_52 8194;
BA_ "GenSigCmt" SG_ 339 CAN_DET_RANGE_52 "Detected object range 52";
BA_ "GenSigSendType" SG_ 339 CAN_DET_RANGE_52 1;
BA_ "GenSigCmt" SG_ 339 CAN_DET_RANGE_RATE_52 "Detected object range rate 52";
BA_ "GenSigSendType" SG_ 339 CAN_DET_RANGE_RATE_52 1;
BA_ "GenSigStartValue" SG_ 339 CAN_DET_RANGE_RATE_52 8192;
BA_ "GenSigCmt" SG_ 339 CAN_DET_AMPLITUDE_52 "Detected object amplitude 52";
BA_ "GenSigSendType" SG_ 339 CAN_DET_AMPLITUDE_52 1;
BA_ "GenSigCmt" SG_ 339 CAN_SCAN_INDEX_2LSB_52 "The two LSB of scan index 52";
BA_ "GenSigSendType" SG_ 339 CAN_SCAN_INDEX_2LSB_52 1;
BA_ "GenSigCmt" SG_ 338 CAN_SNR_LEVEL_51 "Signal to noise level 51";
BA_ "GenSigSendType" SG_ 338 CAN_SNR_LEVEL_51 1;
BA_ "GenSigVtName" SG_ 338 CAN_SNR_LEVEL_51 "VtSig_CAN_SNR_LEVEL_51";
BA_ "GenSigVtEn" SG_ 338 CAN_SNR_LEVEL_51 "TRUE";
BA_ "GenSigCmt" SG_ 338 CAN_DET_SUPER_RES_TARGET_51 "Super resolution target 51";
BA_ "GenSigSendType" SG_ 338 CAN_DET_SUPER_RES_TARGET_51 1;
BA_ "GenSigCmt" SG_ 338 CAN_DET_ND_TARGET_51 "Near discrimination target 51";
BA_ "GenSigSendType" SG_ 338 CAN_DET_ND_TARGET_51 1;
BA_ "GenSigCmt" SG_ 338 CAN_DET_HOST_VEH_CLUTTER_51 "Host vehicle clutter 51";
BA_ "GenSigSendType" SG_ 338 CAN_DET_HOST_VEH_CLUTTER_51 1;
BA_ "GenSigCmt" SG_ 338 CAN_DET_VALID_LEVEL_51 "Detected object valid level 51";
BA_ "GenSigSendType" SG_ 338 CAN_DET_VALID_LEVEL_51 1;
BA_ "GenSigCmt" SG_ 338 CAN_DET_AZIMUTH_51 "Detected object azimuth position 51";
BA_ "GenSigSendType" SG_ 338 CAN_DET_AZIMUTH_51 1;
BA_ "GenSigStartValue" SG_ 338 CAN_DET_AZIMUTH_51 8194;
BA_ "GenSigCmt" SG_ 338 CAN_DET_RANGE_51 "Detected object range 51";
BA_ "GenSigSendType" SG_ 338 CAN_DET_RANGE_51 1;
BA_ "GenSigCmt" SG_ 338 CAN_DET_RANGE_RATE_51 "Detected object range rate 51";
BA_ "GenSigSendType" SG_ 338 CAN_DET_RANGE_RATE_51 1;
BA_ "GenSigStartValue" SG_ 338 CAN_DET_RANGE_RATE_51 8192;
BA_ "GenSigCmt" SG_ 338 CAN_DET_AMPLITUDE_51 "Detected object amplitude 51";
BA_ "GenSigSendType" SG_ 338 CAN_DET_AMPLITUDE_51 1;
BA_ "GenSigCmt" SG_ 338 CAN_SCAN_INDEX_2LSB_51 "The two LSB of scan index 51";
BA_ "GenSigSendType" SG_ 338 CAN_SCAN_INDEX_2LSB_51 1;
BA_ "GenSigCmt" SG_ 337 CAN_SNR_LEVEL_50 "Signal to noise level 50";
BA_ "GenSigSendType" SG_ 337 CAN_SNR_LEVEL_50 1;
BA_ "GenSigVtName" SG_ 337 CAN_SNR_LEVEL_50 "VtSig_CAN_SNR_LEVEL_50";
BA_ "GenSigVtEn" SG_ 337 CAN_SNR_LEVEL_50 "TRUE";
BA_ "GenSigCmt" SG_ 337 CAN_DET_SUPER_RES_TARGET_50 "Super resolution target 50";
BA_ "GenSigSendType" SG_ 337 CAN_DET_SUPER_RES_TARGET_50 1;
BA_ "GenSigCmt" SG_ 337 CAN_DET_ND_TARGET_50 "Near discrimination target 50";
BA_ "GenSigSendType" SG_ 337 CAN_DET_ND_TARGET_50 1;
BA_ "GenSigCmt" SG_ 337 CAN_DET_HOST_VEH_CLUTTER_50 "Host vehicle clutter 50";
BA_ "GenSigSendType" SG_ 337 CAN_DET_HOST_VEH_CLUTTER_50 1;
BA_ "GenSigCmt" SG_ 337 CAN_DET_VALID_LEVEL_50 "Detected object valid level 50";
BA_ "GenSigSendType" SG_ 337 CAN_DET_VALID_LEVEL_50 1;
BA_ "GenSigCmt" SG_ 337 CAN_DET_AZIMUTH_50 "Detected object azimuth position 50";
BA_ "GenSigSendType" SG_ 337 CAN_DET_AZIMUTH_50 1;
BA_ "GenSigStartValue" SG_ 337 CAN_DET_AZIMUTH_50 8194;
BA_ "GenSigCmt" SG_ 337 CAN_DET_RANGE_50 "Detected object range 50";
BA_ "GenSigSendType" SG_ 337 CAN_DET_RANGE_50 1;
BA_ "GenSigCmt" SG_ 337 CAN_DET_RANGE_RATE_50 "Detected object range rate 50";
BA_ "GenSigSendType" SG_ 337 CAN_DET_RANGE_RATE_50 1;
BA_ "GenSigStartValue" SG_ 337 CAN_DET_RANGE_RATE_50 8192;
BA_ "GenSigCmt" SG_ 337 CAN_DET_AMPLITUDE_50 "Detected object amplitude 50";
BA_ "GenSigSendType" SG_ 337 CAN_DET_AMPLITUDE_50 1;
BA_ "GenSigCmt" SG_ 337 CAN_SCAN_INDEX_2LSB_50 "The two LSB of scan index 50";
BA_ "GenSigSendType" SG_ 337 CAN_SCAN_INDEX_2LSB_50 1;
BA_ "GenSigCmt" SG_ 336 CAN_SNR_LEVEL_49 "Signal to noise level 49";
BA_ "GenSigSendType" SG_ 336 CAN_SNR_LEVEL_49 1;
BA_ "GenSigVtName" SG_ 336 CAN_SNR_LEVEL_49 "VtSig_CAN_SNR_LEVEL_49";
BA_ "GenSigVtEn" SG_ 336 CAN_SNR_LEVEL_49 "TRUE";
BA_ "GenSigCmt" SG_ 336 CAN_DET_SUPER_RES_TARGET_49 "Super resolution target 49";
BA_ "GenSigSendType" SG_ 336 CAN_DET_SUPER_RES_TARGET_49 1;
BA_ "GenSigCmt" SG_ 336 CAN_DET_ND_TARGET_49 "Near discrimination target 49";
BA_ "GenSigSendType" SG_ 336 CAN_DET_ND_TARGET_49 1;
BA_ "GenSigCmt" SG_ 336 CAN_DET_HOST_VEH_CLUTTER_49 "Host vehicle clutter 49";
BA_ "GenSigSendType" SG_ 336 CAN_DET_HOST_VEH_CLUTTER_49 1;
BA_ "GenSigCmt" SG_ 336 CAN_DET_VALID_LEVEL_49 "Detected object valid level 49";
BA_ "GenSigSendType" SG_ 336 CAN_DET_VALID_LEVEL_49 1;
BA_ "GenSigCmt" SG_ 336 CAN_DET_AZIMUTH_49 "Detected object azimuth position 49";
BA_ "GenSigSendType" SG_ 336 CAN_DET_AZIMUTH_49 1;
BA_ "GenSigStartValue" SG_ 336 CAN_DET_AZIMUTH_49 8194;
BA_ "GenSigCmt" SG_ 336 CAN_DET_RANGE_49 "Detected object range 49";
BA_ "GenSigSendType" SG_ 336 CAN_DET_RANGE_49 1;
BA_ "GenSigCmt" SG_ 336 CAN_DET_RANGE_RATE_49 "Detected object range rate 49";
BA_ "GenSigSendType" SG_ 336 CAN_DET_RANGE_RATE_49 1;
BA_ "GenSigStartValue" SG_ 336 CAN_DET_RANGE_RATE_49 8192;
BA_ "GenSigCmt" SG_ 336 CAN_DET_AMPLITUDE_49 "Detected object amplitude 49";
BA_ "GenSigSendType" SG_ 336 CAN_DET_AMPLITUDE_49 1;
BA_ "GenSigCmt" SG_ 336 CAN_SCAN_INDEX_2LSB_49 "The two LSB of scan index 49";
BA_ "GenSigSendType" SG_ 336 CAN_SCAN_INDEX_2LSB_49 1;
BA_ "GenSigCmt" SG_ 326 CAN_SNR_LEVEL_39 "Signal to noise level 39";
BA_ "GenSigSendType" SG_ 326 CAN_SNR_LEVEL_39 1;
BA_ "GenSigVtName" SG_ 326 CAN_SNR_LEVEL_39 "VtSig_CAN_SNR_LEVEL_39";
BA_ "GenSigVtEn" SG_ 326 CAN_SNR_LEVEL_39 "TRUE";
BA_ "GenSigCmt" SG_ 326 CAN_DET_SUPER_RES_TARGET_39 "Super resolution target 39";
BA_ "GenSigSendType" SG_ 326 CAN_DET_SUPER_RES_TARGET_39 1;
BA_ "GenSigCmt" SG_ 326 CAN_DET_ND_TARGET_39 "Near discrimination target 39";
BA_ "GenSigSendType" SG_ 326 CAN_DET_ND_TARGET_39 1;
BA_ "GenSigCmt" SG_ 326 CAN_DET_HOST_VEH_CLUTTER_39 "Host vehicle clutter 39";
BA_ "GenSigSendType" SG_ 326 CAN_DET_HOST_VEH_CLUTTER_39 1;
BA_ "GenSigCmt" SG_ 326 CAN_DET_VALID_LEVEL_39 "Detected object valid level 39";
BA_ "GenSigSendType" SG_ 326 CAN_DET_VALID_LEVEL_39 1;
BA_ "GenSigCmt" SG_ 326 CAN_DET_AZIMUTH_39 "Detected object azimuth position 39";
BA_ "GenSigSendType" SG_ 326 CAN_DET_AZIMUTH_39 1;
BA_ "GenSigStartValue" SG_ 326 CAN_DET_AZIMUTH_39 8194;
BA_ "GenSigCmt" SG_ 326 CAN_DET_RANGE_39 "Detected object range 39";
BA_ "GenSigSendType" SG_ 326 CAN_DET_RANGE_39 1;
BA_ "GenSigCmt" SG_ 326 CAN_DET_RANGE_RATE_39 "Detected object range rate 39";
BA_ "GenSigSendType" SG_ 326 CAN_DET_RANGE_RATE_39 1;
BA_ "GenSigStartValue" SG_ 326 CAN_DET_RANGE_RATE_39 8192;
BA_ "GenSigCmt" SG_ 326 CAN_DET_AMPLITUDE_39 "Detected object amplitude 39";
BA_ "GenSigSendType" SG_ 326 CAN_DET_AMPLITUDE_39 1;
BA_ "GenSigCmt" SG_ 326 CAN_SCAN_INDEX_2LSB_39 "The two LSB of scan index 39";
BA_ "GenSigSendType" SG_ 326 CAN_SCAN_INDEX_2LSB_39 1;
BA_ "GenSigCmt" SG_ 315 CAN_SNR_LEVEL_28 "Signal to noise level 28";
BA_ "GenSigSendType" SG_ 315 CAN_SNR_LEVEL_28 1;
BA_ "GenSigVtName" SG_ 315 CAN_SNR_LEVEL_28 "VtSig_CAN_SNR_LEVEL_28";
BA_ "GenSigVtEn" SG_ 315 CAN_SNR_LEVEL_28 "TRUE";
BA_ "GenSigCmt" SG_ 315 CAN_DET_SUPER_RES_TARGET_28 "Super resolution target 28";
BA_ "GenSigSendType" SG_ 315 CAN_DET_SUPER_RES_TARGET_28 1;
BA_ "GenSigCmt" SG_ 315 CAN_DET_ND_TARGET_28 "Near discrimination target 28";
BA_ "GenSigSendType" SG_ 315 CAN_DET_ND_TARGET_28 1;
BA_ "GenSigCmt" SG_ 315 CAN_DET_HOST_VEH_CLUTTER_28 "Host vehicle clutter 28";
BA_ "GenSigSendType" SG_ 315 CAN_DET_HOST_VEH_CLUTTER_28 1;
BA_ "GenSigCmt" SG_ 315 CAN_DET_VALID_LEVEL_28 "Detected object valid level 28";
BA_ "GenSigSendType" SG_ 315 CAN_DET_VALID_LEVEL_28 1;
BA_ "GenSigCmt" SG_ 315 CAN_DET_AZIMUTH_28 "Detected object azimuth position 28";
BA_ "GenSigSendType" SG_ 315 CAN_DET_AZIMUTH_28 1;
BA_ "GenSigStartValue" SG_ 315 CAN_DET_AZIMUTH_28 8194;
BA_ "GenSigCmt" SG_ 315 CAN_DET_RANGE_28 "Detected object range 28";
BA_ "GenSigSendType" SG_ 315 CAN_DET_RANGE_28 1;
BA_ "GenSigCmt" SG_ 315 CAN_DET_RANGE_RATE_28 "Detected object range rate 28";
BA_ "GenSigSendType" SG_ 315 CAN_DET_RANGE_RATE_28 1;
BA_ "GenSigStartValue" SG_ 315 CAN_DET_RANGE_RATE_28 8192;
BA_ "GenSigCmt" SG_ 315 CAN_DET_AMPLITUDE_28 "Detected object amplitude 28";
BA_ "GenSigSendType" SG_ 315 CAN_DET_AMPLITUDE_28 1;
BA_ "GenSigCmt" SG_ 315 CAN_SCAN_INDEX_2LSB_28 "The two LSB of scan index 28";
BA_ "GenSigSendType" SG_ 315 CAN_SCAN_INDEX_2LSB_28 1;
BA_ "GenSigCmt" SG_ 304 CAN_SNR_LEVEL_17 "Signal to noise level 17";
BA_ "GenSigSendType" SG_ 304 CAN_SNR_LEVEL_17 1;
BA_ "GenSigVtName" SG_ 304 CAN_SNR_LEVEL_17 "VtSig_CAN_SNR_LEVEL_17";
BA_ "GenSigVtEn" SG_ 304 CAN_SNR_LEVEL_17 "TRUE";
BA_ "GenSigCmt" SG_ 304 CAN_DET_SUPER_RES_TARGET_17 "Super resolution target 17";
BA_ "GenSigSendType" SG_ 304 CAN_DET_SUPER_RES_TARGET_17 1;
BA_ "GenSigCmt" SG_ 304 CAN_DET_ND_TARGET_17 "Near discrimination target 17";
BA_ "GenSigSendType" SG_ 304 CAN_DET_ND_TARGET_17 1;
BA_ "GenSigCmt" SG_ 304 CAN_DET_HOST_VEH_CLUTTER_17 "Host vehicle clutter 17";
BA_ "GenSigSendType" SG_ 304 CAN_DET_HOST_VEH_CLUTTER_17 1;
BA_ "GenSigCmt" SG_ 304 CAN_DET_VALID_LEVEL_17 "Detected object valid level 17";
BA_ "GenSigSendType" SG_ 304 CAN_DET_VALID_LEVEL_17 1;
BA_ "GenSigCmt" SG_ 304 CAN_DET_AZIMUTH_17 "Detected object azimuth position 17";
BA_ "GenSigSendType" SG_ 304 CAN_DET_AZIMUTH_17 1;
BA_ "GenSigStartValue" SG_ 304 CAN_DET_AZIMUTH_17 8194;
BA_ "GenSigCmt" SG_ 304 CAN_DET_RANGE_17 "Detected object range 17";
BA_ "GenSigSendType" SG_ 304 CAN_DET_RANGE_17 1;
BA_ "GenSigCmt" SG_ 304 CAN_DET_RANGE_RATE_17 "Detected object range rate 17";
BA_ "GenSigSendType" SG_ 304 CAN_DET_RANGE_RATE_17 1;
BA_ "GenSigStartValue" SG_ 304 CAN_DET_RANGE_RATE_17 8192;
BA_ "GenSigCmt" SG_ 304 CAN_DET_AMPLITUDE_17 "Detected object amplitude 17";
BA_ "GenSigSendType" SG_ 304 CAN_DET_AMPLITUDE_17 1;
BA_ "GenSigCmt" SG_ 304 CAN_SCAN_INDEX_2LSB_17 "The two LSB of scan index 17";
BA_ "GenSigSendType" SG_ 304 CAN_SCAN_INDEX_2LSB_17 1;
BA_ "GenSigCmt" SG_ 303 CAN_SNR_LEVEL_16 "Signal to noise level 16";
BA_ "GenSigSendType" SG_ 303 CAN_SNR_LEVEL_16 1;
BA_ "GenSigVtName" SG_ 303 CAN_SNR_LEVEL_16 "VtSig_CAN_SNR_LEVEL_16";
BA_ "GenSigVtEn" SG_ 303 CAN_SNR_LEVEL_16 "TRUE";
BA_ "GenSigCmt" SG_ 303 CAN_DET_SUPER_RES_TARGET_16 "Super resolution target 16";
BA_ "GenSigSendType" SG_ 303 CAN_DET_SUPER_RES_TARGET_16 1;
BA_ "GenSigCmt" SG_ 303 CAN_DET_ND_TARGET_16 "Near discrimination target 16";
BA_ "GenSigSendType" SG_ 303 CAN_DET_ND_TARGET_16 1;
BA_ "GenSigCmt" SG_ 303 CAN_DET_HOST_VEH_CLUTTER_16 "Host vehicle clutter 16";
BA_ "GenSigSendType" SG_ 303 CAN_DET_HOST_VEH_CLUTTER_16 1;
BA_ "GenSigCmt" SG_ 303 CAN_DET_VALID_LEVEL_16 "Detected object valid level 16";
BA_ "GenSigSendType" SG_ 303 CAN_DET_VALID_LEVEL_16 1;
BA_ "GenSigCmt" SG_ 303 CAN_DET_AZIMUTH_16 "Detected object azimuth position 16";
BA_ "GenSigSendType" SG_ 303 CAN_DET_AZIMUTH_16 1;
BA_ "GenSigStartValue" SG_ 303 CAN_DET_AZIMUTH_16 8194;
BA_ "GenSigCmt" SG_ 303 CAN_DET_RANGE_16 "Detected object range 16";
BA_ "GenSigSendType" SG_ 303 CAN_DET_RANGE_16 1;
BA_ "GenSigCmt" SG_ 303 CAN_DET_RANGE_RATE_16 "Detected object range rate 16";
BA_ "GenSigSendType" SG_ 303 CAN_DET_RANGE_RATE_16 1;
BA_ "GenSigStartValue" SG_ 303 CAN_DET_RANGE_RATE_16 8192;
BA_ "GenSigCmt" SG_ 303 CAN_DET_AMPLITUDE_16 "Detected object amplitude 16";
BA_ "GenSigSendType" SG_ 303 CAN_DET_AMPLITUDE_16 1;
BA_ "GenSigCmt" SG_ 303 CAN_SCAN_INDEX_2LSB_16 "The two LSB of scan index 16";
BA_ "GenSigSendType" SG_ 303 CAN_SCAN_INDEX_2LSB_16 1;
BA_ "GenSigCmt" SG_ 302 CAN_SNR_LEVEL_15 "Signal to noise level 15";
BA_ "GenSigSendType" SG_ 302 CAN_SNR_LEVEL_15 1;
BA_ "GenSigVtName" SG_ 302 CAN_SNR_LEVEL_15 "VtSig_CAN_SNR_LEVEL_15";
BA_ "GenSigVtEn" SG_ 302 CAN_SNR_LEVEL_15 "TRUE";
BA_ "GenSigCmt" SG_ 302 CAN_DET_SUPER_RES_TARGET_15 "Super resolution target 15";
BA_ "GenSigSendType" SG_ 302 CAN_DET_SUPER_RES_TARGET_15 1;
BA_ "GenSigCmt" SG_ 302 CAN_DET_ND_TARGET_15 "Near discrimination target 15";
BA_ "GenSigSendType" SG_ 302 CAN_DET_ND_TARGET_15 1;
BA_ "GenSigCmt" SG_ 302 CAN_DET_HOST_VEH_CLUTTER_15 "Host vehicle clutter 15";
BA_ "GenSigSendType" SG_ 302 CAN_DET_HOST_VEH_CLUTTER_15 1;
BA_ "GenSigCmt" SG_ 302 CAN_DET_VALID_LEVEL_15 "Detected object valid level 15";
BA_ "GenSigSendType" SG_ 302 CAN_DET_VALID_LEVEL_15 1;
BA_ "GenSigCmt" SG_ 302 CAN_DET_AZIMUTH_15 "Detected object azimuth position 15";
BA_ "GenSigSendType" SG_ 302 CAN_DET_AZIMUTH_15 1;
BA_ "GenSigStartValue" SG_ 302 CAN_DET_AZIMUTH_15 8194;
BA_ "GenSigCmt" SG_ 302 CAN_DET_RANGE_15 "Detected object range 15";
BA_ "GenSigSendType" SG_ 302 CAN_DET_RANGE_15 1;
BA_ "GenSigCmt" SG_ 302 CAN_DET_RANGE_RATE_15 "Detected object range rate 15";
BA_ "GenSigSendType" SG_ 302 CAN_DET_RANGE_RATE_15 1;
BA_ "GenSigStartValue" SG_ 302 CAN_DET_RANGE_RATE_15 8192;
BA_ "GenSigCmt" SG_ 302 CAN_DET_AMPLITUDE_15 "Detected object amplitude 15";
BA_ "GenSigSendType" SG_ 302 CAN_DET_AMPLITUDE_15 1;
BA_ "GenSigCmt" SG_ 302 CAN_SCAN_INDEX_2LSB_15 "The two LSB of scan index 15";
BA_ "GenSigSendType" SG_ 302 CAN_SCAN_INDEX_2LSB_15 1;
BA_ "GenSigCmt" SG_ 301 CAN_SNR_LEVEL_14 "Signal to noise level 14";
BA_ "GenSigSendType" SG_ 301 CAN_SNR_LEVEL_14 1;
BA_ "GenSigVtName" SG_ 301 CAN_SNR_LEVEL_14 "VtSig_CAN_SNR_LEVEL_14";
BA_ "GenSigVtEn" SG_ 301 CAN_SNR_LEVEL_14 "TRUE";
BA_ "GenSigCmt" SG_ 301 CAN_DET_SUPER_RES_TARGET_14 "Super resolution target 14";
BA_ "GenSigSendType" SG_ 301 CAN_DET_SUPER_RES_TARGET_14 1;
BA_ "GenSigCmt" SG_ 301 CAN_DET_ND_TARGET_14 "Near discrimination target 14";
BA_ "GenSigSendType" SG_ 301 CAN_DET_ND_TARGET_14 1;
BA_ "GenSigCmt" SG_ 301 CAN_DET_HOST_VEH_CLUTTER_14 "Host vehicle clutter 14";
BA_ "GenSigSendType" SG_ 301 CAN_DET_HOST_VEH_CLUTTER_14 1;
BA_ "GenSigCmt" SG_ 301 CAN_DET_VALID_LEVEL_14 "Detected object valid level 14";
BA_ "GenSigSendType" SG_ 301 CAN_DET_VALID_LEVEL_14 1;
BA_ "GenSigCmt" SG_ 301 CAN_DET_AZIMUTH_14 "Detected object azimuth position 14";
BA_ "GenSigSendType" SG_ 301 CAN_DET_AZIMUTH_14 1;
BA_ "GenSigStartValue" SG_ 301 CAN_DET_AZIMUTH_14 8194;
BA_ "GenSigCmt" SG_ 301 CAN_DET_RANGE_14 "Detected object range 14";
BA_ "GenSigSendType" SG_ 301 CAN_DET_RANGE_14 1;
BA_ "GenSigCmt" SG_ 301 CAN_DET_RANGE_RATE_14 "Detected object range rate 14";
BA_ "GenSigSendType" SG_ 301 CAN_DET_RANGE_RATE_14 1;
BA_ "GenSigStartValue" SG_ 301 CAN_DET_RANGE_RATE_14 8192;
BA_ "GenSigCmt" SG_ 301 CAN_DET_AMPLITUDE_14 "Detected object amplitude 14";
BA_ "GenSigSendType" SG_ 301 CAN_DET_AMPLITUDE_14 1;
BA_ "GenSigCmt" SG_ 301 CAN_SCAN_INDEX_2LSB_14 "The two LSB of scan index 14";
BA_ "GenSigSendType" SG_ 301 CAN_SCAN_INDEX_2LSB_14 1;
BA_ "GenSigCmt" SG_ 300 CAN_SNR_LEVEL_13 "Signal to noise level 13";
BA_ "GenSigSendType" SG_ 300 CAN_SNR_LEVEL_13 1;
BA_ "GenSigVtName" SG_ 300 CAN_SNR_LEVEL_13 "VtSig_CAN_SNR_LEVEL_13";
BA_ "GenSigVtEn" SG_ 300 CAN_SNR_LEVEL_13 "TRUE";
BA_ "GenSigCmt" SG_ 300 CAN_DET_SUPER_RES_TARGET_13 "Super resolution target 13";
BA_ "GenSigSendType" SG_ 300 CAN_DET_SUPER_RES_TARGET_13 1;
BA_ "GenSigCmt" SG_ 300 CAN_DET_ND_TARGET_13 "Near discrimination target 13";
BA_ "GenSigSendType" SG_ 300 CAN_DET_ND_TARGET_13 1;
BA_ "GenSigCmt" SG_ 300 CAN_DET_HOST_VEH_CLUTTER_13 "Host vehicle clutter 13";
BA_ "GenSigSendType" SG_ 300 CAN_DET_HOST_VEH_CLUTTER_13 1;
BA_ "GenSigCmt" SG_ 300 CAN_DET_VALID_LEVEL_13 "Detected object valid level 13";
BA_ "GenSigSendType" SG_ 300 CAN_DET_VALID_LEVEL_13 1;
BA_ "GenSigCmt" SG_ 300 CAN_DET_AZIMUTH_13 "Detected object azimuth position 13";
BA_ "GenSigSendType" SG_ 300 CAN_DET_AZIMUTH_13 1;
BA_ "GenSigStartValue" SG_ 300 CAN_DET_AZIMUTH_13 8194;
BA_ "GenSigCmt" SG_ 300 CAN_DET_RANGE_13 "Detected object range 13";
BA_ "GenSigSendType" SG_ 300 CAN_DET_RANGE_13 1;
BA_ "GenSigCmt" SG_ 300 CAN_DET_RANGE_RATE_13 "Detected object range rate 13";
BA_ "GenSigSendType" SG_ 300 CAN_DET_RANGE_RATE_13 1;
BA_ "GenSigStartValue" SG_ 300 CAN_DET_RANGE_RATE_13 8192;
BA_ "GenSigCmt" SG_ 300 CAN_DET_AMPLITUDE_13 "Detected object amplitude 13";
BA_ "GenSigSendType" SG_ 300 CAN_DET_AMPLITUDE_13 1;
BA_ "GenSigCmt" SG_ 300 CAN_SCAN_INDEX_2LSB_13 "The two LSB of scan index 13";
BA_ "GenSigSendType" SG_ 300 CAN_SCAN_INDEX_2LSB_13 1;
BA_ "GenSigCmt" SG_ 299 CAN_SNR_LEVEL_12 "Signal to noise level 12";
BA_ "GenSigSendType" SG_ 299 CAN_SNR_LEVEL_12 1;
BA_ "GenSigVtName" SG_ 299 CAN_SNR_LEVEL_12 "VtSig_CAN_SNR_LEVEL_12";
BA_ "GenSigVtEn" SG_ 299 CAN_SNR_LEVEL_12 "TRUE";
BA_ "GenSigCmt" SG_ 299 CAN_DET_SUPER_RES_TARGET_12 "Super resolution target 12";
BA_ "GenSigSendType" SG_ 299 CAN_DET_SUPER_RES_TARGET_12 1;
BA_ "GenSigCmt" SG_ 299 CAN_DET_ND_TARGET_12 "Near discrimination target 12";
BA_ "GenSigSendType" SG_ 299 CAN_DET_ND_TARGET_12 1;
BA_ "GenSigCmt" SG_ 299 CAN_DET_HOST_VEH_CLUTTER_12 "Host vehicle clutter 12";
BA_ "GenSigSendType" SG_ 299 CAN_DET_HOST_VEH_CLUTTER_12 1;
BA_ "GenSigCmt" SG_ 299 CAN_DET_VALID_LEVEL_12 "Detected object valid level 12";
BA_ "GenSigSendType" SG_ 299 CAN_DET_VALID_LEVEL_12 1;
BA_ "GenSigCmt" SG_ 299 CAN_DET_AZIMUTH_12 "Detected object azimuth position 12";
BA_ "GenSigSendType" SG_ 299 CAN_DET_AZIMUTH_12 1;
BA_ "GenSigStartValue" SG_ 299 CAN_DET_AZIMUTH_12 8194;
BA_ "GenSigCmt" SG_ 299 CAN_DET_RANGE_12 "Detected object range 12";
BA_ "GenSigSendType" SG_ 299 CAN_DET_RANGE_12 1;
BA_ "GenSigCmt" SG_ 299 CAN_DET_RANGE_RATE_12 "Detected object range rate 12";
BA_ "GenSigSendType" SG_ 299 CAN_DET_RANGE_RATE_12 1;
BA_ "GenSigStartValue" SG_ 299 CAN_DET_RANGE_RATE_12 8192;
BA_ "GenSigCmt" SG_ 299 CAN_DET_AMPLITUDE_12 "Detected object amplitude 12";
BA_ "GenSigSendType" SG_ 299 CAN_DET_AMPLITUDE_12 1;
BA_ "GenSigCmt" SG_ 299 CAN_SCAN_INDEX_2LSB_12 "The two LSB of scan index 12";
BA_ "GenSigSendType" SG_ 299 CAN_SCAN_INDEX_2LSB_12 1;
BA_ "GenSigCmt" SG_ 298 CAN_SNR_LEVEL_11 "Signal to noise level 11";
BA_ "GenSigSendType" SG_ 298 CAN_SNR_LEVEL_11 1;
BA_ "GenSigVtName" SG_ 298 CAN_SNR_LEVEL_11 "VtSig_CAN_SNR_LEVEL_11";
BA_ "GenSigVtEn" SG_ 298 CAN_SNR_LEVEL_11 "TRUE";
BA_ "GenSigCmt" SG_ 298 CAN_DET_SUPER_RES_TARGET_11 "Super resolution target 11";
BA_ "GenSigSendType" SG_ 298 CAN_DET_SUPER_RES_TARGET_11 1;
BA_ "GenSigCmt" SG_ 298 CAN_DET_ND_TARGET_11 "Near discrimination target 11";
BA_ "GenSigSendType" SG_ 298 CAN_DET_ND_TARGET_11 1;
BA_ "GenSigCmt" SG_ 298 CAN_DET_HOST_VEH_CLUTTER_11 "Host vehicle clutter 11";
BA_ "GenSigSendType" SG_ 298 CAN_DET_HOST_VEH_CLUTTER_11 1;
BA_ "GenSigCmt" SG_ 298 CAN_DET_VALID_LEVEL_11 "Detected object valid level 11";
BA_ "GenSigSendType" SG_ 298 CAN_DET_VALID_LEVEL_11 1;
BA_ "GenSigCmt" SG_ 298 CAN_DET_AZIMUTH_11 "Detected object azimuth position 11";
BA_ "GenSigSendType" SG_ 298 CAN_DET_AZIMUTH_11 1;
BA_ "GenSigStartValue" SG_ 298 CAN_DET_AZIMUTH_11 8194;
BA_ "GenSigCmt" SG_ 298 CAN_DET_RANGE_11 "Detected object range 11";
BA_ "GenSigSendType" SG_ 298 CAN_DET_RANGE_11 1;
BA_ "GenSigCmt" SG_ 298 CAN_DET_RANGE_RATE_11 "Detected object range rate 11";
BA_ "GenSigSendType" SG_ 298 CAN_DET_RANGE_RATE_11 1;
BA_ "GenSigStartValue" SG_ 298 CAN_DET_RANGE_RATE_11 8192;
BA_ "GenSigCmt" SG_ 298 CAN_DET_AMPLITUDE_11 "Detected object amplitude 11";
BA_ "GenSigSendType" SG_ 298 CAN_DET_AMPLITUDE_11 1;
BA_ "GenSigCmt" SG_ 298 CAN_SCAN_INDEX_2LSB_11 "The two LSB of scan index 11";
BA_ "GenSigSendType" SG_ 298 CAN_SCAN_INDEX_2LSB_11 1;
BA_ "GenSigCmt" SG_ 297 CAN_SNR_LEVEL_10 "Signal to noise level 10";
BA_ "GenSigSendType" SG_ 297 CAN_SNR_LEVEL_10 1;
BA_ "GenSigVtName" SG_ 297 CAN_SNR_LEVEL_10 "VtSig_CAN_SNR_LEVEL_10";
BA_ "GenSigVtEn" SG_ 297 CAN_SNR_LEVEL_10 "TRUE";
BA_ "GenSigCmt" SG_ 297 CAN_DET_SUPER_RES_TARGET_10 "Super resolution target 10";
BA_ "GenSigSendType" SG_ 297 CAN_DET_SUPER_RES_TARGET_10 1;
BA_ "GenSigCmt" SG_ 297 CAN_DET_ND_TARGET_10 "Near discrimination target 10";
BA_ "GenSigSendType" SG_ 297 CAN_DET_ND_TARGET_10 1;
BA_ "GenSigCmt" SG_ 297 CAN_DET_HOST_VEH_CLUTTER_10 "Host vehicle clutter 10";
BA_ "GenSigSendType" SG_ 297 CAN_DET_HOST_VEH_CLUTTER_10 1;
BA_ "GenSigCmt" SG_ 297 CAN_DET_VALID_LEVEL_10 "Detected object valid level 10";
BA_ "GenSigSendType" SG_ 297 CAN_DET_VALID_LEVEL_10 1;
BA_ "GenSigCmt" SG_ 297 CAN_DET_AZIMUTH_10 "Detected object azimuth position 10";
BA_ "GenSigSendType" SG_ 297 CAN_DET_AZIMUTH_10 1;
BA_ "GenSigStartValue" SG_ 297 CAN_DET_AZIMUTH_10 8194;
BA_ "GenSigCmt" SG_ 297 CAN_DET_RANGE_10 "Detected object range 10";
BA_ "GenSigSendType" SG_ 297 CAN_DET_RANGE_10 1;
BA_ "GenSigCmt" SG_ 297 CAN_DET_RANGE_RATE_10 "Detected object range rate 10";
BA_ "GenSigSendType" SG_ 297 CAN_DET_RANGE_RATE_10 1;
BA_ "GenSigStartValue" SG_ 297 CAN_DET_RANGE_RATE_10 8192;
BA_ "GenSigCmt" SG_ 297 CAN_DET_AMPLITUDE_10 "Detected object amplitude 10";
BA_ "GenSigSendType" SG_ 297 CAN_DET_AMPLITUDE_10 1;
BA_ "GenSigCmt" SG_ 297 CAN_SCAN_INDEX_2LSB_10 "The two LSB of scan index 10";
BA_ "GenSigSendType" SG_ 297 CAN_SCAN_INDEX_2LSB_10 1;
BA_ "GenSigCmt" SG_ 296 CAN_SNR_LEVEL_09 "Signal to noise level 09";
BA_ "GenSigSendType" SG_ 296 CAN_SNR_LEVEL_09 1;
BA_ "GenSigVtName" SG_ 296 CAN_SNR_LEVEL_09 "VtSig_CAN_SNR_LEVEL_09";
BA_ "GenSigVtEn" SG_ 296 CAN_SNR_LEVEL_09 "TRUE";
BA_ "GenSigCmt" SG_ 296 CAN_DET_SUPER_RES_TARGET_09 "Super resolution target 09";
BA_ "GenSigSendType" SG_ 296 CAN_DET_SUPER_RES_TARGET_09 1;
BA_ "GenSigCmt" SG_ 296 CAN_DET_ND_TARGET_09 "Near discrimination target 09";
BA_ "GenSigSendType" SG_ 296 CAN_DET_ND_TARGET_09 1;
BA_ "GenSigCmt" SG_ 296 CAN_DET_HOST_VEH_CLUTTER_09 "Host vehicle clutter 09";
BA_ "GenSigSendType" SG_ 296 CAN_DET_HOST_VEH_CLUTTER_09 1;
BA_ "GenSigCmt" SG_ 296 CAN_DET_VALID_LEVEL_09 "Detected object valid level 09";
BA_ "GenSigSendType" SG_ 296 CAN_DET_VALID_LEVEL_09 1;
BA_ "GenSigCmt" SG_ 296 CAN_DET_AZIMUTH_09 "Detected object azimuth position 09";
BA_ "GenSigSendType" SG_ 296 CAN_DET_AZIMUTH_09 1;
BA_ "GenSigStartValue" SG_ 296 CAN_DET_AZIMUTH_09 8194;
BA_ "GenSigCmt" SG_ 296 CAN_DET_RANGE_09 "Detected object range 09";
BA_ "GenSigSendType" SG_ 296 CAN_DET_RANGE_09 1;
BA_ "GenSigCmt" SG_ 296 CAN_DET_RANGE_RATE_09 "Detected object range rate 09";
BA_ "GenSigSendType" SG_ 296 CAN_DET_RANGE_RATE_09 1;
BA_ "GenSigStartValue" SG_ 296 CAN_DET_RANGE_RATE_09 8192;
BA_ "GenSigCmt" SG_ 296 CAN_DET_AMPLITUDE_09 "Detected object amplitude 09";
BA_ "GenSigSendType" SG_ 296 CAN_DET_AMPLITUDE_09 1;
BA_ "GenSigCmt" SG_ 296 CAN_SCAN_INDEX_2LSB_09 "The two LSB of scan index 09";
BA_ "GenSigSendType" SG_ 296 CAN_SCAN_INDEX_2LSB_09 1;
BA_ "GenSigCmt" SG_ 295 CAN_SNR_LEVEL_08 "Signal to noise level 08";
BA_ "GenSigSendType" SG_ 295 CAN_SNR_LEVEL_08 1;
BA_ "GenSigVtName" SG_ 295 CAN_SNR_LEVEL_08 "VtSig_CAN_SNR_LEVEL_08";
BA_ "GenSigVtEn" SG_ 295 CAN_SNR_LEVEL_08 "TRUE";
BA_ "GenSigCmt" SG_ 295 CAN_DET_SUPER_RES_TARGET_08 "Super resolution target 08";
BA_ "GenSigSendType" SG_ 295 CAN_DET_SUPER_RES_TARGET_08 1;
BA_ "GenSigCmt" SG_ 295 CAN_DET_ND_TARGET_08 "Near discrimination target 08";
BA_ "GenSigSendType" SG_ 295 CAN_DET_ND_TARGET_08 1;
BA_ "GenSigCmt" SG_ 295 CAN_DET_HOST_VEH_CLUTTER_08 "Host vehicle clutter 08";
BA_ "GenSigSendType" SG_ 295 CAN_DET_HOST_VEH_CLUTTER_08 1;
BA_ "GenSigCmt" SG_ 295 CAN_DET_VALID_LEVEL_08 "Detected object valid level 08";
BA_ "GenSigSendType" SG_ 295 CAN_DET_VALID_LEVEL_08 1;
BA_ "GenSigCmt" SG_ 295 CAN_DET_AZIMUTH_08 "Detected object azimuth position 08";
BA_ "GenSigSendType" SG_ 295 CAN_DET_AZIMUTH_08 1;
BA_ "GenSigStartValue" SG_ 295 CAN_DET_AZIMUTH_08 8194;
BA_ "GenSigCmt" SG_ 295 CAN_DET_RANGE_08 "Detected object range 08";
BA_ "GenSigSendType" SG_ 295 CAN_DET_RANGE_08 1;
BA_ "GenSigCmt" SG_ 295 CAN_DET_RANGE_RATE_08 "Detected object range rate 08";
BA_ "GenSigSendType" SG_ 295 CAN_DET_RANGE_RATE_08 1;
BA_ "GenSigStartValue" SG_ 295 CAN_DET_RANGE_RATE_08 8192;
BA_ "GenSigCmt" SG_ 295 CAN_DET_AMPLITUDE_08 "Detected object amplitude 08";
BA_ "GenSigSendType" SG_ 295 CAN_DET_AMPLITUDE_08 1;
BA_ "GenSigCmt" SG_ 295 CAN_SCAN_INDEX_2LSB_08 "The two LSB of scan index 08";
BA_ "GenSigSendType" SG_ 295 CAN_SCAN_INDEX_2LSB_08 1;
BA_ "GenSigCmt" SG_ 294 CAN_SNR_LEVEL_07 "Signal to noise level 07";
BA_ "GenSigSendType" SG_ 294 CAN_SNR_LEVEL_07 1;
BA_ "GenSigVtName" SG_ 294 CAN_SNR_LEVEL_07 "VtSig_CAN_SNR_LEVEL_07";
BA_ "GenSigVtEn" SG_ 294 CAN_SNR_LEVEL_07 "TRUE";
BA_ "GenSigCmt" SG_ 294 CAN_DET_SUPER_RES_TARGET_07 "Super resolution target 07";
BA_ "GenSigSendType" SG_ 294 CAN_DET_SUPER_RES_TARGET_07 1;
BA_ "GenSigCmt" SG_ 294 CAN_DET_ND_TARGET_07 "Near discrimination target 07";
BA_ "GenSigSendType" SG_ 294 CAN_DET_ND_TARGET_07 1;
BA_ "GenSigCmt" SG_ 294 CAN_DET_HOST_VEH_CLUTTER_07 "Host vehicle clutter 07";
BA_ "GenSigSendType" SG_ 294 CAN_DET_HOST_VEH_CLUTTER_07 1;
BA_ "GenSigCmt" SG_ 294 CAN_DET_VALID_LEVEL_07 "Detected object valid level 07";
BA_ "GenSigSendType" SG_ 294 CAN_DET_VALID_LEVEL_07 1;
BA_ "GenSigCmt" SG_ 294 CAN_DET_AZIMUTH_07 "Detected object azimuth position 07";
BA_ "GenSigSendType" SG_ 294 CAN_DET_AZIMUTH_07 1;
BA_ "GenSigStartValue" SG_ 294 CAN_DET_AZIMUTH_07 8194;
BA_ "GenSigCmt" SG_ 294 CAN_DET_RANGE_07 "Detected object range 07";
BA_ "GenSigSendType" SG_ 294 CAN_DET_RANGE_07 1;
BA_ "GenSigCmt" SG_ 294 CAN_DET_RANGE_RATE_07 "Detected object range rate 07";
BA_ "GenSigSendType" SG_ 294 CAN_DET_RANGE_RATE_07 1;
BA_ "GenSigStartValue" SG_ 294 CAN_DET_RANGE_RATE_07 8192;
BA_ "GenSigCmt" SG_ 294 CAN_DET_AMPLITUDE_07 "Detected object amplitude 07";
BA_ "GenSigSendType" SG_ 294 CAN_DET_AMPLITUDE_07 1;
BA_ "GenSigCmt" SG_ 294 CAN_SCAN_INDEX_2LSB_07 "The two LSB of scan index 07";
BA_ "GenSigSendType" SG_ 294 CAN_SCAN_INDEX_2LSB_07 1;
BA_ "GenSigCmt" SG_ 293 CAN_SNR_LEVEL_06 "Signal to noise level 06";
BA_ "GenSigSendType" SG_ 293 CAN_SNR_LEVEL_06 1;
BA_ "GenSigVtName" SG_ 293 CAN_SNR_LEVEL_06 "VtSig_CAN_SNR_LEVEL_06";
BA_ "GenSigVtEn" SG_ 293 CAN_SNR_LEVEL_06 "TRUE";
BA_ "GenSigCmt" SG_ 293 CAN_DET_SUPER_RES_TARGET_06 "Super resolution target 06";
BA_ "GenSigSendType" SG_ 293 CAN_DET_SUPER_RES_TARGET_06 1;
BA_ "GenSigCmt" SG_ 293 CAN_DET_ND_TARGET_06 "Near discrimination target 06";
BA_ "GenSigSendType" SG_ 293 CAN_DET_ND_TARGET_06 1;
BA_ "GenSigCmt" SG_ 293 CAN_DET_HOST_VEH_CLUTTER_06 "Host vehicle clutter 06";
BA_ "GenSigSendType" SG_ 293 CAN_DET_HOST_VEH_CLUTTER_06 1;
BA_ "GenSigCmt" SG_ 293 CAN_DET_VALID_LEVEL_06 "Detected object valid level 06";
BA_ "GenSigSendType" SG_ 293 CAN_DET_VALID_LEVEL_06 1;
BA_ "GenSigCmt" SG_ 293 CAN_DET_AZIMUTH_06 "Detected object azimuth position 06";
BA_ "GenSigSendType" SG_ 293 CAN_DET_AZIMUTH_06 1;
BA_ "GenSigStartValue" SG_ 293 CAN_DET_AZIMUTH_06 8194;
BA_ "GenSigCmt" SG_ 293 CAN_DET_RANGE_06 "Detected object range 06";
BA_ "GenSigSendType" SG_ 293 CAN_DET_RANGE_06 1;
BA_ "GenSigCmt" SG_ 293 CAN_DET_RANGE_RATE_06 "Detected object range rate 06";
BA_ "GenSigSendType" SG_ 293 CAN_DET_RANGE_RATE_06 1;
BA_ "GenSigStartValue" SG_ 293 CAN_DET_RANGE_RATE_06 8192;
BA_ "GenSigCmt" SG_ 293 CAN_DET_AMPLITUDE_06 "Detected object amplitude 06";
BA_ "GenSigSendType" SG_ 293 CAN_DET_AMPLITUDE_06 1;
BA_ "GenSigCmt" SG_ 293 CAN_SCAN_INDEX_2LSB_06 "The two LSB of scan index 06";
BA_ "GenSigSendType" SG_ 293 CAN_SCAN_INDEX_2LSB_06 1;
BA_ "GenSigCmt" SG_ 292 CAN_SNR_LEVEL_05 "Signal to noise level 05";
BA_ "GenSigSendType" SG_ 292 CAN_SNR_LEVEL_05 1;
BA_ "GenSigVtName" SG_ 292 CAN_SNR_LEVEL_05 "VtSig_CAN_SNR_LEVEL_05";
BA_ "GenSigVtEn" SG_ 292 CAN_SNR_LEVEL_05 "TRUE";
BA_ "GenSigCmt" SG_ 292 CAN_DET_SUPER_RES_TARGET_05 "Super resolution target 05";
BA_ "GenSigSendType" SG_ 292 CAN_DET_SUPER_RES_TARGET_05 1;
BA_ "GenSigCmt" SG_ 292 CAN_DET_ND_TARGET_05 "Near discrimination target 05";
BA_ "GenSigSendType" SG_ 292 CAN_DET_ND_TARGET_05 1;
BA_ "GenSigCmt" SG_ 292 CAN_DET_HOST_VEH_CLUTTER_05 "Host vehicle clutter 05";
BA_ "GenSigSendType" SG_ 292 CAN_DET_HOST_VEH_CLUTTER_05 1;
BA_ "GenSigCmt" SG_ 292 CAN_DET_VALID_LEVEL_05 "Detected object valid level 05";
BA_ "GenSigSendType" SG_ 292 CAN_DET_VALID_LEVEL_05 1;
BA_ "GenSigCmt" SG_ 292 CAN_DET_AZIMUTH_05 "Detected object azimuth position 05";
BA_ "GenSigSendType" SG_ 292 CAN_DET_AZIMUTH_05 1;
BA_ "GenSigStartValue" SG_ 292 CAN_DET_AZIMUTH_05 8194;
BA_ "GenSigCmt" SG_ 292 CAN_DET_RANGE_05 "Detected object range 05";
BA_ "GenSigSendType" SG_ 292 CAN_DET_RANGE_05 1;
BA_ "GenSigCmt" SG_ 292 CAN_DET_RANGE_RATE_05 "Detected object range rate 05";
BA_ "GenSigSendType" SG_ 292 CAN_DET_RANGE_RATE_05 1;
BA_ "GenSigStartValue" SG_ 292 CAN_DET_RANGE_RATE_05 8192;
BA_ "GenSigCmt" SG_ 292 CAN_DET_AMPLITUDE_05 "Detected object amplitude 05";
BA_ "GenSigSendType" SG_ 292 CAN_DET_AMPLITUDE_05 1;
BA_ "GenSigCmt" SG_ 292 CAN_SCAN_INDEX_2LSB_05 "The two LSB of scan index 05";
BA_ "GenSigSendType" SG_ 292 CAN_SCAN_INDEX_2LSB_05 1;
BA_ "GenSigCmt" SG_ 290 CAN_SNR_LEVEL_03 "Signal to noise level 03";
BA_ "GenSigSendType" SG_ 290 CAN_SNR_LEVEL_03 1;
BA_ "GenSigVtName" SG_ 290 CAN_SNR_LEVEL_03 "VtSig_CAN_SNR_LEVEL_03";
BA_ "GenSigVtEn" SG_ 290 CAN_SNR_LEVEL_03 "TRUE";
BA_ "GenSigCmt" SG_ 290 CAN_DET_SUPER_RES_TARGET_03 "Super resolution target 03";
BA_ "GenSigSendType" SG_ 290 CAN_DET_SUPER_RES_TARGET_03 1;
BA_ "GenSigCmt" SG_ 290 CAN_DET_ND_TARGET_03 "Near discrimination target 03";
BA_ "GenSigSendType" SG_ 290 CAN_DET_ND_TARGET_03 1;
BA_ "GenSigCmt" SG_ 290 CAN_DET_HOST_VEH_CLUTTER_03 "Host vehicle clutter 03";
BA_ "GenSigSendType" SG_ 290 CAN_DET_HOST_VEH_CLUTTER_03 1;
BA_ "GenSigCmt" SG_ 290 CAN_DET_VALID_LEVEL_03 "Detected object valid level 03";
BA_ "GenSigSendType" SG_ 290 CAN_DET_VALID_LEVEL_03 1;
BA_ "GenSigCmt" SG_ 290 CAN_DET_AZIMUTH_03 "Detected object azimuth position 03";
BA_ "GenSigSendType" SG_ 290 CAN_DET_AZIMUTH_03 1;
BA_ "GenSigStartValue" SG_ 290 CAN_DET_AZIMUTH_03 8194;
BA_ "GenSigCmt" SG_ 290 CAN_DET_RANGE_03 "Detected object range 03";
BA_ "GenSigSendType" SG_ 290 CAN_DET_RANGE_03 1;
BA_ "GenSigCmt" SG_ 290 CAN_DET_RANGE_RATE_03 "Detected object range rate 03";
BA_ "GenSigSendType" SG_ 290 CAN_DET_RANGE_RATE_03 1;
BA_ "GenSigStartValue" SG_ 290 CAN_DET_RANGE_RATE_03 8192;
BA_ "GenSigCmt" SG_ 290 CAN_DET_AMPLITUDE_03 "Detected object amplitude 03";
BA_ "GenSigSendType" SG_ 290 CAN_DET_AMPLITUDE_03 1;
BA_ "GenSigCmt" SG_ 290 CAN_SCAN_INDEX_2LSB_03 "The two LSB of scan index 03";
BA_ "GenSigSendType" SG_ 290 CAN_SCAN_INDEX_2LSB_03 1;
BA_ "GenSigCmt" SG_ 289 CAN_SNR_LEVEL_02 "Signal to noise level 02";
BA_ "GenSigSendType" SG_ 289 CAN_SNR_LEVEL_02 1;
BA_ "GenSigVtName" SG_ 289 CAN_SNR_LEVEL_02 "VtSig_CAN_SNR_LEVEL_02";
BA_ "GenSigVtEn" SG_ 289 CAN_SNR_LEVEL_02 "TRUE";
BA_ "GenSigCmt" SG_ 289 CAN_DET_SUPER_RES_TARGET_02 "Super resolution target 02";
BA_ "GenSigSendType" SG_ 289 CAN_DET_SUPER_RES_TARGET_02 1;
BA_ "GenSigCmt" SG_ 289 CAN_DET_ND_TARGET_02 "Near discrimination target 02";
BA_ "GenSigSendType" SG_ 289 CAN_DET_ND_TARGET_02 1;
BA_ "GenSigCmt" SG_ 289 CAN_DET_HOST_VEH_CLUTTER_02 "Host vehicle clutter 02";
BA_ "GenSigSendType" SG_ 289 CAN_DET_HOST_VEH_CLUTTER_02 1;
BA_ "GenSigCmt" SG_ 289 CAN_DET_VALID_LEVEL_02 "Detected object valid level 02";
BA_ "GenSigSendType" SG_ 289 CAN_DET_VALID_LEVEL_02 1;
BA_ "GenSigCmt" SG_ 289 CAN_DET_AZIMUTH_02 "Detected object azimuth position 02";
BA_ "GenSigSendType" SG_ 289 CAN_DET_AZIMUTH_02 1;
BA_ "GenSigStartValue" SG_ 289 CAN_DET_AZIMUTH_02 8194;
BA_ "GenSigCmt" SG_ 289 CAN_DET_RANGE_02 "Detected object range 02";
BA_ "GenSigSendType" SG_ 289 CAN_DET_RANGE_02 1;
BA_ "GenSigCmt" SG_ 289 CAN_DET_RANGE_RATE_02 "Detected object range rate 02";
BA_ "GenSigSendType" SG_ 289 CAN_DET_RANGE_RATE_02 1;
BA_ "GenSigStartValue" SG_ 289 CAN_DET_RANGE_RATE_02 8192;
BA_ "GenSigCmt" SG_ 289 CAN_DET_AMPLITUDE_02 "Detected object amplitude 02";
BA_ "GenSigSendType" SG_ 289 CAN_DET_AMPLITUDE_02 1;
BA_ "GenSigCmt" SG_ 289 CAN_SCAN_INDEX_2LSB_02 "The two LSB of scan index 02";
BA_ "GenSigSendType" SG_ 289 CAN_SCAN_INDEX_2LSB_02 1;
BA_ "GenSigCmt" SG_ 288 CAN_SNR_LEVEL_01 "Signal to noise level 01";
BA_ "GenSigSendType" SG_ 288 CAN_SNR_LEVEL_01 1;
BA_ "GenSigVtName" SG_ 288 CAN_SNR_LEVEL_01 "VtSig_CAN_SNR_LEVEL_01";
BA_ "GenSigVtEn" SG_ 288 CAN_SNR_LEVEL_01 "TRUE";
BA_ "GenSigCmt" SG_ 288 CAN_DET_SUPER_RES_TARGET_01 "Super resolution target 01";
BA_ "GenSigSendType" SG_ 288 CAN_DET_SUPER_RES_TARGET_01 1;
BA_ "GenSigCmt" SG_ 288 CAN_DET_ND_TARGET_01 "Near discrimination target 01";
BA_ "GenSigSendType" SG_ 288 CAN_DET_ND_TARGET_01 1;
BA_ "GenSigCmt" SG_ 288 CAN_DET_HOST_VEH_CLUTTER_01 "Host vehicle clutter 01";
BA_ "GenSigSendType" SG_ 288 CAN_DET_HOST_VEH_CLUTTER_01 1;
BA_ "GenSigCmt" SG_ 288 CAN_DET_VALID_LEVEL_01 "Detected object valid level 01";
BA_ "GenSigSendType" SG_ 288 CAN_DET_VALID_LEVEL_01 1;
BA_ "GenSigCmt" SG_ 288 CAN_DET_AZIMUTH_01 "Detected object azimuth position 01";
BA_ "GenSigSendType" SG_ 288 CAN_DET_AZIMUTH_01 1;
BA_ "GenSigStartValue" SG_ 288 CAN_DET_AZIMUTH_01 8194;
BA_ "GenSigCmt" SG_ 288 CAN_DET_RANGE_01 "Detected object range 01";
BA_ "GenSigSendType" SG_ 288 CAN_DET_RANGE_01 1;
BA_ "GenSigCmt" SG_ 288 CAN_DET_RANGE_RATE_01 "Detected object range rate 01";
BA_ "GenSigSendType" SG_ 288 CAN_DET_RANGE_RATE_01 1;
BA_ "GenSigStartValue" SG_ 288 CAN_DET_RANGE_RATE_01 8192;
BA_ "GenSigCmt" SG_ 288 CAN_DET_AMPLITUDE_01 "Detected object amplitude 01";
BA_ "GenSigSendType" SG_ 288 CAN_DET_AMPLITUDE_01 1;
BA_ "GenSigCmt" SG_ 288 CAN_SCAN_INDEX_2LSB_01 "The two LSB of scan index 01";
BA_ "GenSigSendType" SG_ 288 CAN_SCAN_INDEX_2LSB_01 1;
VAL_ 330 CAN_SNR_LEVEL_43 3 "High" 2 "Moderate" 1 "Low" 0 "Very Low" ;
VAL_ 329 CAN_SNR_LEVEL_42 3 "High" 2 "Moderate" 1 "Low" 0 "Very Low" ;
VAL_ 328 CAN_SNR_LEVEL_41 3 "High" 2 "Moderate" 1 "Low" 0 "Very Low" ;
VAL_ 327 CAN_SNR_LEVEL_40 3 "High" 2 "Moderate" 1 "Low" 0 "Very Low" ;
VAL_ 325 CAN_SNR_LEVEL_38 3 "High" 2 "Moderate" 1 "Low" 0 "Very Low" ;
VAL_ 324 CAN_SNR_LEVEL_37 3 "High" 2 "Moderate" 1 "Low" 0 "Very Low" ;
VAL_ 323 CAN_SNR_LEVEL_36 3 "High" 2 "Moderate" 1 "Low" 0 "Very Low" ;
VAL_ 322 CAN_SNR_LEVEL_35 3 "High" 2 "Moderate" 1 "Low" 0 "Very Low" ;
VAL_ 321 CAN_SNR_LEVEL_34 3 "High" 2 "Moderate" 1 "Low" 0 "Very Low" ;
VAL_ 320 CAN_SNR_LEVEL_33 3 "High" 2 "Moderate" 1 "Low" 0 "Very Low" ;
VAL_ 319 CAN_SNR_LEVEL_32 3 "High" 2 "Moderate" 1 "Low" 0 "Very Low" ;
VAL_ 318 CAN_SNR_LEVEL_31 3 "High" 2 "Moderate" 1 "Low" 0 "Very Low" ;
VAL_ 317 CAN_SNR_LEVEL_30 3 "High" 2 "Moderate" 1 "Low" 0 "Very Low" ;
VAL_ 316 CAN_SNR_LEVEL_29 3 "High" 2 "Moderate" 1 "Low" 0 "Very Low" ;
VAL_ 314 CAN_SNR_LEVEL_27 3 "High" 2 "Moderate" 1 "Low" 0 "Very Low" ;
VAL_ 313 CAN_SNR_LEVEL_26 3 "High" 2 "Moderate" 1 "Low" 0 "Very Low" ;
VAL_ 312 CAN_SNR_LEVEL_25 3 "High" 2 "Moderate" 1 "Low" 0 "Very Low" ;
VAL_ 311 CAN_SNR_LEVEL_24 3 "High" 2 "Moderate" 1 "Low" 0 "Very Low" ;
VAL_ 310 CAN_SNR_LEVEL_23 3 "High" 2 "Moderate" 1 "Low" 0 "Very Low" ;
VAL_ 309 CAN_SNR_LEVEL_22 3 "High" 2 "Moderate" 1 "Low" 0 "Very Low" ;
VAL_ 308 CAN_SNR_LEVEL_21 3 "High" 2 "Moderate" 1 "Low" 0 "Very Low" ;
VAL_ 307 CAN_SNR_LEVEL_20 3 "High" 2 "Moderate" 1 "Low" 0 "Very Low" ;
VAL_ 306 CAN_SNR_LEVEL_19 3 "High" 2 "Moderate" 1 "Low" 0 "Very Low" ;
VAL_ 305 CAN_SNR_LEVEL_18 3 "High" 2 "Moderate" 1 "Low" 0 "Very Low" ;
VAL_ 341 CAN_SNR_LEVEL_54 3 "High" 2 "Moderate" 1 "Low" 0 "Very Low" ;
VAL_ 340 CAN_SNR_LEVEL_53 3 "High" 2 "Moderate" 1 "Low" 0 "Very Low" ;
VAL_ 339 CAN_SNR_LEVEL_52 3 "High" 2 "Moderate" 1 "Low" 0 "Very Low" ;
VAL_ 338 CAN_SNR_LEVEL_51 3 "High" 2 "Moderate" 1 "Low" 0 "Very Low" ;
VAL_ 337 CAN_SNR_LEVEL_50 3 "High" 2 "Moderate" 1 "Low" 0 "Very Low" ;
VAL_ 336 CAN_SNR_LEVEL_49 3 "High" 2 "Moderate" 1 "Low" 0 "Very Low" ;
VAL_ 326 CAN_SNR_LEVEL_39 3 "High" 2 "Moderate" 1 "Low" 0 "Very Low" ;
VAL_ 315 CAN_SNR_LEVEL_28 3 "High" 2 "Moderate" 1 "Low" 0 "Very Low" ;
VAL_ 304 CAN_SNR_LEVEL_17 3 "High" 2 "Moderate" 1 "Low" 0 "Very Low" ;
VAL_ 303 CAN_SNR_LEVEL_16 3 "High" 2 "Moderate" 1 "Low" 0 "Very Low" ;
VAL_ 302 CAN_SNR_LEVEL_15 3 "High" 2 "Moderate" 1 "Low" 0 "Very Low" ;
VAL_ 301 CAN_SNR_LEVEL_14 3 "High" 2 "Moderate" 1 "Low" 0 "Very Low" ;
VAL_ 300 CAN_SNR_LEVEL_13 3 "High" 2 "Moderate" 1 "Low" 0 "Very Low" ;
VAL_ 299 CAN_SNR_LEVEL_12 3 "High" 2 "Moderate" 1 "Low" 0 "Very Low" ;
VAL_ 298 CAN_SNR_LEVEL_11 3 "High" 2 "Moderate" 1 "Low" 0 "Very Low" ;
VAL_ 297 CAN_SNR_LEVEL_10 3 "High" 2 "Moderate" 1 "Low" 0 "Very Low" ;
VAL_ 296 CAN_SNR_LEVEL_09 3 "High" 2 "Moderate" 1 "Low" 0 "Very Low" ;
VAL_ 295 CAN_SNR_LEVEL_08 3 "High" 2 "Moderate" 1 "Low" 0 "Very Low" ;
VAL_ 294 CAN_SNR_LEVEL_07 3 "High" 2 "Moderate" 1 "Low" 0 "Very Low" ;
VAL_ 293 CAN_SNR_LEVEL_06 3 "High" 2 "Moderate" 1 "Low" 0 "Very Low" ;
VAL_ 292 CAN_SNR_LEVEL_05 3 "High" 2 "Moderate" 1 "Low" 0 "Very Low" ;
VAL_ 290 CAN_SNR_LEVEL_03 3 "High" 2 "Moderate" 1 "Low" 0 "Very Low" ;
VAL_ 289 CAN_SNR_LEVEL_02 3 "High" 2 "Moderate" 1 "Low" 0 "Very Low" ;
VAL_ 288 CAN_SNR_LEVEL_01 3 "High" 2 "Moderate" 1 "Low" 0 "Very Low" ;
